VERSION ""

NS_ :

BS_:

BU_: Dummy_FO TestTool_FO LRR_FO RFSRR_FO LFSRR_FO RSRR_FO VIS_FO EOCM_F_FO
VAL_TABLE_ vt_BooleanValues 1 "true" 0 "false" ;
VAL_TABLE_ PAWarningSt 15 "Zone 15" 14 "Zone 14" 13 "Zone 13" 12 "Zone 12" 11 "Zone 11" 10 "Zone 10" 9 "Zone 9" 8 "Zone 8" 7 "Zone 7" 6 "Zone 6" 5 "Zone 5" 4 "Zone 4" 3 "Zone 3" 2 "Zone 2" 1 "Zone 1" 0 "No Object" ;
VAL_TABLE_ BWWarningSt 4 "Vehicle Hold" 3 "Auto Brake" 2 "Imminent Alert" 1 "Caution Alert" 0 "No Alert" ;
VAL_TABLE_ PASysStatus 3 "Failed" 2 "Inhibited" 1 "Enabled" 0 "Disabled" ;
VAL_TABLE_ VBBrkCtrlSt 4 "Release Control" 3 "Hold Vehicle" 2 "Apply Brake" 1 "Decrease Torque" 0 "No Action" ;
VAL_TABLE_ UPABrkCtrlStat 4 "Release Control" 3 "Hold Vehicle" 2 "Apply Brake" 1 "Decrease Torque" 0 "No Action" ;
VAL_TABLE_ ObstacleType 6 "NO_OBJECT" 5 "OBJ_GUARDRAIL" 4 "OBJ_TUNNEL " 3 "OBJ_TRAFFIC_SIGN" 2 "OBJ_VEHICLE" 1 "OBJ_BRIDGE " 0 "OBJ_UNKNOWN" ;
VAL_TABLE_ VpathMode 2 "Mid Hi Spped" 1 "Low Speed" 0 "Disabled" ;
VAL_TABLE_ LaneChngStatus 2 "Lane Change Right" 1 "Lane Change Left" 0 "Idle" ;
VAL_TABLE_ TravelDirection 3 "Other (excessive side slip)" 2 "reverse / stopped in rvrs gear" 1 "Forward / stopped in frwd gear" 0 "Unknown" ;
VAL_TABLE_ TrueOrFalse 1 "true" 0 "false" ;
VAL_TABLE_ ModeCommand 5 "Sensing with Reduced Power" 4 "Undefined" 3 "Radio Silent" 2 "Sensing" 1 "Not Sensing" 0 "Undefined" ;
VAL_TABLE_ LaneSnsLLnPosValid 1 "Invalid" 0 "Valid" ;
VAL_TABLE_ LnSnsRLnPosValid 1 "Invalid" 0 "Valid" ;
VAL_TABLE_ Elevation 3 "Low " 2 "mid (reserved)" 1 "high " 0 "Unknown" ;
VAL_TABLE_ ModeCommandFdbk 5 "Sensing with reduced power" 4 "Undefined" 3 "Radio Silent" 2 "Sensing" 1 "Not Sensing" 0 "Undefined" ;
VAL_TABLE_ relativeLane 3 "Left Lane" 2 "Right Lane" 1 "Host Lane" 0 "Unknown" ;
VAL_TABLE_ RoadTypeInfo 5 "Constiction Zone Exit" 4 "Construction Zone Entry" 3 "Highway" 2 "Secondary Road" 1 "City" 0 "Unknown" ;
VAL_TABLE_ ObjectLossInfo 2 "elevation conditions" 1 "tight curve" 0 "not lost" ;
VAL_TABLE_ MeasurementStatus 3 "Measured this cycle" 2 "Latent track not detctd this cyc" 1 "New Object" 0 "No Object" ;
VAL_TABLE_ ObjectType 7 "no object present" 6 "fixed roadside object" 5 "fixed overhead object" 4 "pedestrian" 3 "motocycle  / bicycle" 2 "Large vehicle (semi)" 1 "4 Wheel Vehicle (car, small trk)" 0 "Unknown" ;
VAL_TABLE_ Confidence 3 "confident" 2 "speculative" 1 "highly speculative" 0 "invalid" ;
VAL_TABLE_ DynamicProp 4 "Moving in opposite direction" 3 "Moving in same direction as host" 2 "Has moved but currently stopped" 1 "Has never moved" 0 "Unknown" ;
VAL_TABLE_ OtsdAmbtLtLvlStat 2 "Day" 1 "Night" 0 "Unknown" ;
VAL_TABLE_ SysPwrMd 3 "Crank Request" 2 "Run" 1 "Accessory" 0 "Off" ;
VAL_TABLE_ ValidityStates 1 "Invalid" 0 "Valid" ;

BO_ 1401 R_Rwd_Fus_Obj_TrackB_9: 7 EOCM_F_FO
 SG_ RwdFusTrkBAnlgRlLn9 : 46|8@0- (0.1,0) [-12.8|12.7] ""  Dummy_FO
 SG_ RwdFusTrkB9RollingCnt : 7|2@0+ (1,0) [0|3] ""  Dummy_FO
 SG_ RwdFusTrkB9Width : 5|6@0+ (0.25,0) [0|15.75] "m"  Dummy_FO
 SG_ RwdFusTrkB9MsgIndex : 15|4@0+ (1,0) [0|15] ""  Dummy_FO
 SG_ RwdFusTrkB9DynProp : 11|3@0+ (1,0) [0|7] ""  Dummy_FO
 SG_ RwdFusTrkB9RelLnAccl : 8|9@0- (0.125,0) [-32|31.875] "m/s^2"  Dummy_FO
 SG_ RwdFusTrkB9RelLane : 31|2@0+ (1,0) [0|3] ""  Dummy_FO
 SG_ RwdFusTrkB9Height : 54|6@0+ (0.25,0) [0|15.75] "m"  Dummy_FO
 SG_ RFusTrkB9ObjSrcLFSrr : 29|1@0+ (1,0) [0|1] ""  Dummy_FO
 SG_ RFusTrkB9ObjSrcLCSrr : 28|1@0+ (1,0) [0|1] ""  Dummy_FO
 SG_ RFusTrkB9ObjSrcRCSrr : 27|1@0+ (1,0) [0|1] ""  Dummy_FO
 SG_ RFusTrkB9ObjSrcRFSrr : 26|1@0+ (1,0) [0|1] ""  Dummy_FO
 SG_ RFusTrkB9ObjSrcVIs : 25|1@0+ (1,0) [0|1] ""  Dummy_FO
 SG_ RwdFusTrkB9ObjSrcLrr : 24|1@0+ (1,0) [0|1] ""  Dummy_FO
 SG_ RwdFusTrkB9NmCycTrkd : 39|3@0+ (1,0) [0|7] ""  Dummy_FO
 SG_ RwdFusTrkB9LatPosDev : 36|3@0+ (1,0) [0|7] ""  Dummy_FO
 SG_ RwdFusTrkB9LngPosDev : 33|3@0+ (1,0) [0|7] ""  Dummy_FO

BO_ 1400 R_Rwd_Fus_Obj_TrackB_8: 7 EOCM_F_FO
 SG_ RwdFusTrkBAnlgRlLn8 : 46|8@0- (0.1,0) [-12.8|12.7] ""  Dummy_FO
 SG_ RwdFusTrkB8RollingCnt : 7|2@0+ (1,0) [0|3] ""  Dummy_FO
 SG_ RwdFusTrkB8Width : 5|6@0+ (0.25,0) [0|15.75] "m"  Dummy_FO
 SG_ RwdFusTrkB8MsgIndex : 15|4@0+ (1,0) [0|15] ""  Dummy_FO
 SG_ RwdFusTrkB8DynProp : 11|3@0+ (1,0) [0|7] ""  Dummy_FO
 SG_ RwdFusTrkB8RelLnAccl : 8|9@0- (0.125,0) [-32|31.875] "m/s^2"  Dummy_FO
 SG_ RwdFusTrkB8RelLane : 31|2@0+ (1,0) [0|3] ""  Dummy_FO
 SG_ RwdFusTrkB8Height : 54|6@0+ (0.25,0) [0|15.75] "m"  Dummy_FO
 SG_ RFusTrkB8ObjSrcLFSrr : 29|1@0+ (1,0) [0|1] ""  Dummy_FO
 SG_ RFusTrkB8ObjSrcLCSrr : 28|1@0+ (1,0) [0|1] ""  Dummy_FO
 SG_ RFusTrkB8ObjSrcRCSrr : 27|1@0+ (1,0) [0|1] ""  Dummy_FO
 SG_ RFusTrkB8ObjSrcRFSrr : 26|1@0+ (1,0) [0|1] ""  Dummy_FO
 SG_ RFusTrkB8ObjSrcVIs : 25|1@0+ (1,0) [0|1] ""  Dummy_FO
 SG_ RwdFusTrkB8ObjSrcLrr : 24|1@0+ (1,0) [0|1] ""  Dummy_FO
 SG_ RwdFusTrkB8NmCycTrkd : 39|3@0+ (1,0) [0|7] ""  Dummy_FO
 SG_ RwdFusTrkB8LatPosDev : 36|3@0+ (1,0) [0|7] ""  Dummy_FO
 SG_ RwdFusTrkB8LngPosDev : 33|3@0+ (1,0) [0|7] ""  Dummy_FO

BO_ 1399 R_Rwd_Fus_Obj_TrackB_7: 7 EOCM_F_FO
 SG_ RwdFusTrkBAnlgRlLn7 : 46|8@0- (0.1,0) [-12.8|12.7] ""  Dummy_FO
 SG_ RwdFusTrkB7RollingCnt : 7|2@0+ (1,0) [0|3] ""  Dummy_FO
 SG_ RwdFusTrkB7Width : 5|6@0+ (0.25,0) [0|15.75] "m"  Dummy_FO
 SG_ RwdFusTrkB7MsgIndex : 15|4@0+ (1,0) [0|15] ""  Dummy_FO
 SG_ RwdFusTrkB7DynProp : 11|3@0+ (1,0) [0|7] ""  Dummy_FO
 SG_ RwdFusTrkB7RelLnAccl : 8|9@0- (0.125,0) [-32|31.875] "m/s^2"  Dummy_FO
 SG_ RwdFusTrkB7RelLane : 31|2@0+ (1,0) [0|3] ""  Dummy_FO
 SG_ RwdFusTrkB7Height : 54|6@0+ (0.25,0) [0|15.75] "m"  Dummy_FO
 SG_ RFusTrkB7ObjSrcLFSrr : 29|1@0+ (1,0) [0|1] ""  Dummy_FO
 SG_ RFusTrkB7ObjSrcLCSrr : 28|1@0+ (1,0) [0|1] ""  Dummy_FO
 SG_ RFusTrkB7ObjSrcRCSrr : 27|1@0+ (1,0) [0|1] ""  Dummy_FO
 SG_ RFusTrkB7ObjSrcRFSrr : 26|1@0+ (1,0) [0|1] ""  Dummy_FO
 SG_ RFusTrkB7ObjSrcVIs : 25|1@0+ (1,0) [0|1] ""  Dummy_FO
 SG_ RwdFusTrkB7ObjSrcLrr : 24|1@0+ (1,0) [0|1] ""  Dummy_FO
 SG_ RwdFusTrkB7NmCycTrkd : 39|3@0+ (1,0) [0|7] ""  Dummy_FO
 SG_ RwdFusTrkB7LatPosDev : 36|3@0+ (1,0) [0|7] ""  Dummy_FO
 SG_ RwdFusTrkB7LngPosDev : 33|3@0+ (1,0) [0|7] ""  Dummy_FO

BO_ 1398 R_Rwd_Fus_Obj_TrackB_6: 7 EOCM_F_FO
 SG_ RwdFusTrkB6LngPosDev : 33|3@0+ (1,0) [0|7] ""  Dummy_FO
 SG_ RwdFusTrkBAnlgRlLn6 : 46|8@0- (0.1,0) [-12.8|12.7] ""  Dummy_FO
 SG_ RwdFusTrkB6RollingCnt : 7|2@0+ (1,0) [0|3] ""  Dummy_FO
 SG_ RwdFusTrkB6Width : 5|6@0+ (0.25,0) [0|15.75] "m"  Dummy_FO
 SG_ RwdFusTrkB6MsgIndex : 15|4@0+ (1,0) [0|15] ""  Dummy_FO
 SG_ RwdFusTrkB6DynProp : 11|3@0+ (1,0) [0|7] ""  Dummy_FO
 SG_ RwdFusTrkB6RelLnAccl : 8|9@0- (0.125,0) [-32|31.875] "m/s^2"  Dummy_FO
 SG_ RwdFusTrkB6RelLane : 31|2@0+ (1,0) [0|3] ""  Dummy_FO
 SG_ RwdFusTrkB6Height : 54|6@0+ (0.25,0) [0|15.75] "m"  Dummy_FO
 SG_ RFusTrkB6ObjSrcLFSrr : 29|1@0+ (1,0) [0|1] ""  Dummy_FO
 SG_ RFusTrkB6ObjSrcLCSrr : 28|1@0+ (1,0) [0|1] ""  Dummy_FO
 SG_ RFusTrkB6ObjSrcRCSrr : 27|1@0+ (1,0) [0|1] ""  Dummy_FO
 SG_ RFusTrkB6ObjSrcRFSrr : 26|1@0+ (1,0) [0|1] ""  Dummy_FO
 SG_ RFusTrkB6ObjSrcVIs : 25|1@0+ (1,0) [0|1] ""  Dummy_FO
 SG_ RwdFusTrkB6ObjSrcLrr : 24|1@0+ (1,0) [0|1] ""  Dummy_FO
 SG_ RwdFusTrkB6NmCycTrkd : 39|3@0+ (1,0) [0|7] ""  Dummy_FO
 SG_ RwdFusTrkB6LatPosDev : 36|3@0+ (1,0) [0|7] ""  Dummy_FO

BO_ 1397 R_Rwd_Fus_Obj_TrackB_5: 7 EOCM_F_FO
 SG_ RwdFusTrkBAnlgRlLn5 : 46|8@0- (0.1,0) [-12.8|12.7] ""  Dummy_FO
 SG_ RwdFusTrkB5RollingCnt : 7|2@0+ (1,0) [0|3] ""  Dummy_FO
 SG_ RwdFusTrkB5Width : 5|6@0+ (0.25,0) [0|15.75] "m"  Dummy_FO
 SG_ RwdFusTrkB5MsgIndex : 15|4@0+ (1,0) [0|15] ""  Dummy_FO
 SG_ RwdFusTrkB5DynProp : 11|3@0+ (1,0) [0|7] ""  Dummy_FO
 SG_ RwdFusTrkB5RelLnAccl : 8|9@0- (0.125,0) [-32|31.875] "m/s^2"  Dummy_FO
 SG_ RwdFusTrkB5RelLane : 31|2@0+ (1,0) [0|3] ""  Dummy_FO
 SG_ RwdFusTrkB5Height : 54|6@0+ (0.25,0) [0|15.75] "m"  Dummy_FO
 SG_ RFusTrkB5ObjSrcLFSrr : 29|1@0+ (1,0) [0|1] ""  Dummy_FO
 SG_ RFusTrkB5ObjSrcLCSrr : 28|1@0+ (1,0) [0|1] ""  Dummy_FO
 SG_ RFusTrkB5ObjSrcRCSrr : 27|1@0+ (1,0) [0|1] ""  Dummy_FO
 SG_ RFusTrkB5ObjSrcRFSrr : 26|1@0+ (1,0) [0|1] ""  Dummy_FO
 SG_ RFusTrkB5ObjSrcVIs : 25|1@0+ (1,0) [0|1] ""  Dummy_FO
 SG_ RwdFusTrkB5ObjSrcLrr : 24|1@0+ (1,0) [0|1] ""  Dummy_FO
 SG_ RwdFusTrkB5NmCycTrkd : 39|3@0+ (1,0) [0|7] ""  Dummy_FO
 SG_ RwdFusTrkB5LatPosDev : 36|3@0+ (1,0) [0|7] ""  Dummy_FO
 SG_ RwdFusTrkB5LngPosDev : 33|3@0+ (1,0) [0|7] ""  Dummy_FO

BO_ 1396 R_Rwd_Fus_Obj_TrackB_4: 7 EOCM_F_FO
 SG_ RwdFusTrkBAnlgRlLn4 : 46|8@0- (0.1,0) [-12.8|12.7] ""  Dummy_FO
 SG_ RwdFusTrkB4RollingCnt : 7|2@0+ (1,0) [0|3] ""  Dummy_FO
 SG_ RwdFusTrkB4Width : 5|6@0+ (0.25,0) [0|15.75] "m"  Dummy_FO
 SG_ RwdFusTrkB4MsgIndex : 15|4@0+ (1,0) [0|15] ""  Dummy_FO
 SG_ RwdFusTrkB4DynProp : 11|3@0+ (1,0) [0|7] ""  Dummy_FO
 SG_ RwdFusTrkB4RelLnAccl : 8|9@0- (0.125,0) [-32|31.875] "m/s^2"  Dummy_FO
 SG_ RwdFusTrkB4RelLane : 31|2@0+ (1,0) [0|3] ""  Dummy_FO
 SG_ RwdFusTrkB4Height : 54|6@0+ (0.25,0) [0|15.75] "m"  Dummy_FO
 SG_ RFusTrkB4ObjSrcLFSrr : 29|1@0+ (1,0) [0|1] ""  Dummy_FO
 SG_ RFusTrkB4ObjSrcLCSrr : 28|1@0+ (1,0) [0|1] ""  Dummy_FO
 SG_ RFusTrkB4ObjSrcRCSrr : 27|1@0+ (1,0) [0|1] ""  Dummy_FO
 SG_ RFusTrkB4ObjSrcRFSrr : 26|1@0+ (1,0) [0|1] ""  Dummy_FO
 SG_ RFusTrkB4ObjSrcVIs : 25|1@0+ (1,0) [0|1] ""  Dummy_FO
 SG_ RwdFusTrkB4ObjSrcLrr : 24|1@0+ (1,0) [0|1] ""  Dummy_FO
 SG_ RwdFusTrkB4NmCycTrkd : 39|3@0+ (1,0) [0|7] ""  Dummy_FO
 SG_ RwdFusTrkB4LatPosDev : 36|3@0+ (1,0) [0|7] ""  Dummy_FO
 SG_ RwdFusTrkB4LngPosDev : 33|3@0+ (1,0) [0|7] ""  Dummy_FO

BO_ 1395 R_Rwd_Fus_Obj_TrackB_3: 7 EOCM_F_FO
 SG_ RwdFusTrkBAnlgRlLn3 : 46|8@0- (0.1,0) [-12.8|12.7] ""  Dummy_FO
 SG_ RwdFusTrkB3RollingCnt : 7|2@0+ (1,0) [0|3] ""  Dummy_FO
 SG_ RwdFusTrkB3Width : 5|6@0+ (0.25,0) [0|15.75] "m"  Dummy_FO
 SG_ RwdFusTrkB3MsgIndex : 15|4@0+ (1,0) [0|15] ""  Dummy_FO
 SG_ RwdFusTrkB3DynProp : 11|3@0+ (1,0) [0|7] ""  Dummy_FO
 SG_ RwdFusTrkB3RelLnAccl : 8|9@0- (0.125,0) [-32|31.875] "m/s^2"  Dummy_FO
 SG_ RwdFusTrkB3RelLane : 31|2@0+ (1,0) [0|3] ""  Dummy_FO
 SG_ RwdFusTrkB3Height : 54|6@0+ (0.25,0) [0|15.75] "m"  Dummy_FO
 SG_ RFusTrkB3ObjSrcLFSrr : 29|1@0+ (1,0) [0|1] ""  Dummy_FO
 SG_ RFusTrkB3ObjSrcLCSrr : 28|1@0+ (1,0) [0|1] ""  Dummy_FO
 SG_ RFusTrkB3ObjSrcRCSrr : 27|1@0+ (1,0) [0|1] ""  Dummy_FO
 SG_ RFusTrkB3ObjSrcRFSrr : 26|1@0+ (1,0) [0|1] ""  Dummy_FO
 SG_ RFusTrkB3ObjSrcVIs : 25|1@0+ (1,0) [0|1] ""  Dummy_FO
 SG_ RwdFusTrkB3ObjSrcLrr : 24|1@0+ (1,0) [0|1] ""  Dummy_FO
 SG_ RwdFusTrkB3NmCycTrkd : 39|3@0+ (1,0) [0|7] ""  Dummy_FO
 SG_ RwdFusTrkB3LatPosDev : 36|3@0+ (1,0) [0|7] ""  Dummy_FO
 SG_ RwdFusTrkB3LngPosDev : 33|3@0+ (1,0) [0|7] ""  Dummy_FO

BO_ 1394 R_Rwd_Fus_Obj_TrackB_2: 7 EOCM_F_FO
 SG_ RwdFusTrkBAnlgRlLn2 : 46|8@0- (0.1,0) [-12.8|12.7] ""  Dummy_FO
 SG_ RwdFusTrkB2RollingCnt : 7|2@0+ (1,0) [0|3] ""  Dummy_FO
 SG_ RwdFusTrkB2Width : 5|6@0+ (0.25,0) [0|15.75] "m"  Dummy_FO
 SG_ RwdFusTrkB2MsgIndex : 15|4@0+ (1,0) [0|15] ""  Dummy_FO
 SG_ RwdFusTrkB2DynProp : 11|3@0+ (1,0) [0|7] ""  Dummy_FO
 SG_ RwdFusTrkB2RelLnAccl : 8|9@0- (0.125,0) [-32|31.875] "m/s^2"  Dummy_FO
 SG_ RwdFusTrkB2RelLane : 31|2@0+ (1,0) [0|3] ""  Dummy_FO
 SG_ RwdFusTrkB2Height : 54|6@0+ (0.25,0) [0|15.75] "m"  Dummy_FO
 SG_ RFusTrkB2ObjSrcLFSrr : 29|1@0+ (1,0) [0|1] ""  Dummy_FO
 SG_ RFusTrkB2ObjSrcLCSrr : 28|1@0+ (1,0) [0|1] ""  Dummy_FO
 SG_ RFusTrkB2ObjSrcRCSrr : 27|1@0+ (1,0) [0|1] ""  Dummy_FO
 SG_ RFusTrkB2ObjSrcRFSrr : 26|1@0+ (1,0) [0|1] ""  Dummy_FO
 SG_ RFusTrkB2ObjSrcVIs : 25|1@0+ (1,0) [0|1] ""  Dummy_FO
 SG_ RwdFusTrkB2ObjSrcLrr : 24|1@0+ (1,0) [0|1] ""  Dummy_FO
 SG_ RwdFusTrkB2NmCycTrkd : 39|3@0+ (1,0) [0|7] ""  Dummy_FO
 SG_ RwdFusTrkB2LatPosDev : 36|3@0+ (1,0) [0|7] ""  Dummy_FO
 SG_ RwdFusTrkB2LngPosDev : 33|3@0+ (1,0) [0|7] ""  Dummy_FO

BO_ 1407 R_Rwd_Fus_Obj_TrackB_15: 7 EOCM_F_FO
 SG_ RwdFusTrkBAnlgRlLn15 : 46|8@0- (0.1,0) [-12.8|12.7] ""  Dummy_FO
 SG_ RwdFusTrkB15RollingCnt : 7|2@0+ (1,0) [0|3] ""  Dummy_FO
 SG_ RwdFusTrkB15Width : 5|6@0+ (0.25,0) [0|15.75] "m"  Dummy_FO
 SG_ RwdFusTrkB15MsgIndex : 15|4@0+ (1,0) [0|15] ""  Dummy_FO
 SG_ RwdFusTrkB15DynProp : 11|3@0+ (1,0) [0|7] ""  Dummy_FO
 SG_ RwdFusTrkB15RelLnAccl : 8|9@0- (0.125,0) [-32|31.875] "m/s^2"  Dummy_FO
 SG_ RwdFusTrkB15RelLane : 31|2@0+ (1,0) [0|3] ""  Dummy_FO
 SG_ RwdFusTrkB15Height : 54|6@0+ (0.25,0) [0|15.75] "m"  Dummy_FO
 SG_ RFusTrkB15ObjSrcLFSrr : 29|1@0+ (1,0) [0|1] ""  Dummy_FO
 SG_ RFusTrkB15ObjSrcLCSrr : 28|1@0+ (1,0) [0|1] ""  Dummy_FO
 SG_ RFusTrkB15ObjSrcRCSrr : 27|1@0+ (1,0) [0|1] ""  Dummy_FO
 SG_ RFusTrkB15ObjSrcRFSrr : 26|1@0+ (1,0) [0|1] ""  Dummy_FO
 SG_ RFusTkB15ObjSrcVIs : 25|1@0+ (1,0) [0|1] ""  Dummy_FO
 SG_ RwdFusTrkB15ObjSrcLrr : 24|1@0+ (1,0) [0|1] ""  Dummy_FO
 SG_ RwdFusTrkB15NmCycTrkd : 39|3@0+ (1,0) [0|7] ""  Dummy_FO
 SG_ RwdFusTrkB15LatPosDev : 36|3@0+ (1,0) [0|7] ""  Dummy_FO
 SG_ RwdFusTrkB15LngPosDev : 33|3@0+ (1,0) [0|7] ""  Dummy_FO

BO_ 1406 R_Rwd_Fus_Obj_TrackB_14: 7 EOCM_F_FO
 SG_ RwdFusTrkBAnlgRlLn14 : 46|8@0- (0.1,0) [-12.8|12.7] ""  Dummy_FO
 SG_ RwdFusTrkB14RollingCnt : 7|2@0+ (1,0) [0|3] ""  Dummy_FO
 SG_ RwdFusTrkB14Width : 5|6@0+ (0.25,0) [0|15.75] "m"  Dummy_FO
 SG_ RwdFusTrkB14MsgIndex : 15|4@0+ (1,0) [0|15] ""  Dummy_FO
 SG_ RwdFusTrkB14DynProp : 11|3@0+ (1,0) [0|7] ""  Dummy_FO
 SG_ RwdFusTrkB14RelLnAccl : 8|9@0- (0.125,0) [-32|31.875] "m/s^2"  Dummy_FO
 SG_ RwdFusTrkB14RelLane : 31|2@0+ (1,0) [0|3] ""  Dummy_FO
 SG_ RwdFusTrkB14Height : 54|6@0+ (0.25,0) [0|15.75] "m"  Dummy_FO
 SG_ RFusTrkB14ObjSrcLFSrr : 29|1@0+ (1,0) [0|1] ""  Dummy_FO
 SG_ RFusTrkB14ObjSrcLCSrr : 28|1@0+ (1,0) [0|1] ""  Dummy_FO
 SG_ RFusTrkB14ObjSrcRCSrr : 27|1@0+ (1,0) [0|1] ""  Dummy_FO
 SG_ RFusTrkB14ObjSrcRFSrr : 26|1@0+ (1,0) [0|1] ""  Dummy_FO
 SG_ RFusTrkB14ObjSrcVIs : 25|1@0+ (1,0) [0|1] ""  Dummy_FO
 SG_ RwdFusTrkB14ObjSrcLrr : 24|1@0+ (1,0) [0|1] ""  Dummy_FO
 SG_ RwdFusTrkB14NmCycTrkd : 39|3@0+ (1,0) [0|7] ""  Dummy_FO
 SG_ RwdFusTrkB14LatPosDev : 36|3@0+ (1,0) [0|7] ""  Dummy_FO
 SG_ RwdFusTrkB14LngPosDev : 33|3@0+ (1,0) [0|7] ""  Dummy_FO

BO_ 1405 R_Rwd_Fus_Obj_TrackB_13: 7 EOCM_F_FO
 SG_ RwdFusTrkBAnlgRlLn13 : 46|8@0- (0.1,0) [-12.8|12.7] ""  Dummy_FO
 SG_ RwdFusTrkB13RollingCnt : 7|2@0+ (1,0) [0|3] ""  Dummy_FO
 SG_ RwdFusTrkB13Width : 5|6@0+ (0.25,0) [0|15.75] "m"  Dummy_FO
 SG_ RwdFusTrkB13MsgIndex : 15|4@0+ (1,0) [0|15] ""  Dummy_FO
 SG_ RwdFusTrkB13DynProp : 11|3@0+ (1,0) [0|7] ""  Dummy_FO
 SG_ RwdFusTrkB13RelLnAccl : 8|9@0- (0.125,0) [-32|31.875] "m/s^2"  Dummy_FO
 SG_ RwdFusTrkB13RelLane : 31|2@0+ (1,0) [0|3] ""  Dummy_FO
 SG_ RwdFusTrkB13Height : 54|6@0+ (0.25,0) [0|15.75] "m"  Dummy_FO
 SG_ RFusTrkB13ObjSrcLFSrr : 29|1@0+ (1,0) [0|1] ""  Dummy_FO
 SG_ RFusTrkB13ObjSrcLCSrr : 28|1@0+ (1,0) [0|1] ""  Dummy_FO
 SG_ RFusTrkB13ObjSrcRCSrr : 27|1@0+ (1,0) [0|1] ""  Dummy_FO
 SG_ RFusTrkB13ObjSrcRFSrr : 26|1@0+ (1,0) [0|1] ""  Dummy_FO
 SG_ RFusTrkB13ObjSrcVIs : 25|1@0+ (1,0) [0|1] ""  Dummy_FO
 SG_ RwdFusTrkB13ObjSrcLrr : 24|1@0+ (1,0) [0|1] ""  Dummy_FO
 SG_ RwdFusTrkB13NmCycTrkd : 39|3@0+ (1,0) [0|7] ""  Dummy_FO
 SG_ RwdFusTrkB13LatPosDev : 36|3@0+ (1,0) [0|7] ""  Dummy_FO
 SG_ RwdFusTrkB13LngPosDev : 33|3@0+ (1,0) [0|7] ""  Dummy_FO

BO_ 1404 R_Rwd_Fus_Obj_TrackB_12: 7 EOCM_F_FO
 SG_ RwdFusTrkBAnlgRlLn12 : 46|8@0- (0.1,0) [-12.8|12.7] ""  Dummy_FO
 SG_ RwdFusTrkB12RollingCnt : 7|2@0+ (1,0) [0|3] ""  Dummy_FO
 SG_ RwdFusTrkB12Width : 5|6@0+ (0.25,0) [0|15.75] "m"  Dummy_FO
 SG_ RwdFusTrkB12MsgIndex : 15|4@0+ (1,0) [0|15] ""  Dummy_FO
 SG_ RwdFusTrkB12DynProp : 11|3@0+ (1,0) [0|7] ""  Dummy_FO
 SG_ RwdFusTrkB12RelLnAccl : 8|9@0- (0.125,0) [-32|31.875] "m/s^2"  Dummy_FO
 SG_ RwdFusTrkB12RelLane : 31|2@0+ (1,0) [0|3] ""  Dummy_FO
 SG_ RwdFusTrkB12Height : 54|6@0+ (0.25,0) [0|15.75] "m"  Dummy_FO
 SG_ RFusTrkB12ObjSrcLFSrr : 29|1@0+ (1,0) [0|1] ""  Dummy_FO
 SG_ RFusTrkB12ObjSrcLCSrr : 28|1@0+ (1,0) [0|1] ""  Dummy_FO
 SG_ RFusTrkB12ObjSrcRCSrr : 27|1@0+ (1,0) [0|1] ""  Dummy_FO
 SG_ RFusTrkB12ObjSrcRFSrr : 26|1@0+ (1,0) [0|1] ""  Dummy_FO
 SG_ RFusTrkB12ObjSrcVIs : 25|1@0+ (1,0) [0|1] ""  Dummy_FO
 SG_ RwdFusTrkB12ObjSrcLrr : 24|1@0+ (1,0) [0|1] ""  Dummy_FO
 SG_ RwdFusTrkB12NmCycTrkd : 39|3@0+ (1,0) [0|7] ""  Dummy_FO
 SG_ RwdFusTrkB12LatPosDev : 36|3@0+ (1,0) [0|7] ""  Dummy_FO
 SG_ RwdFusTrkB12LngPosDev : 33|3@0+ (1,0) [0|7] ""  Dummy_FO

BO_ 1403 R_Rwd_Fus_Obj_TrackB_11: 7 EOCM_F_FO
 SG_ RwdFusTrkBAnlgRlLn11 : 46|8@0- (0.1,0) [-12.8|12.7] ""  Dummy_FO
 SG_ RwdFusTrkB11RollingCnt : 7|2@0+ (1,0) [0|3] ""  Dummy_FO
 SG_ RwdFusTrkB11Width : 5|6@0+ (0.25,0) [0|15.75] "m"  Dummy_FO
 SG_ RwdFusTrkB11MsgIndex : 15|4@0+ (1,0) [0|15] ""  Dummy_FO
 SG_ RwdFusTrkB11DynProp : 11|3@0+ (1,0) [0|7] ""  Dummy_FO
 SG_ RwdFusTrkB11RelLnAccl : 8|9@0- (0.125,0) [-32|31.875] "m/s^2"  Dummy_FO
 SG_ RwdFusTrkB11RelLane : 31|2@0+ (1,0) [0|3] ""  Dummy_FO
 SG_ RwdFusTrkB11Height : 54|6@0+ (0.25,0) [0|15.75] "m"  Dummy_FO
 SG_ RFusTrkB11ObjSrcLFSrr : 29|1@0+ (1,0) [0|1] ""  Dummy_FO
 SG_ RFusTrkB11ObjSrcLCSrr : 28|1@0+ (1,0) [0|1] ""  Dummy_FO
 SG_ RFusTrkB11ObjSrcRCSrr : 27|1@0+ (1,0) [0|1] ""  Dummy_FO
 SG_ RFusTrkB11ObjSrcRFSrr : 26|1@0+ (1,0) [0|1] ""  Dummy_FO
 SG_ RFusTrkB11ObjSrcVIs : 25|1@0+ (1,0) [0|1] ""  Dummy_FO
 SG_ RwdFusTrkB11ObjSrcLrr : 24|1@0+ (1,0) [0|1] ""  Dummy_FO
 SG_ RwdFusTrkB11NmCycTrkd : 39|3@0+ (1,0) [0|7] ""  Dummy_FO
 SG_ RwdFusTrkB11LatPosDev : 36|3@0+ (1,0) [0|7] ""  Dummy_FO
 SG_ RwdFusTrkB11LngPosDev : 33|3@0+ (1,0) [0|7] ""  Dummy_FO

BO_ 1402 R_Rwd_Fus_Obj_TrackB_10: 7 EOCM_F_FO
 SG_ RwdFusTrkB10NmCycTrkd : 39|3@0+ (1,0) [0|7] ""  Dummy_FO
 SG_ RwdFusTrkB10LatPosDev : 36|3@0+ (1,0) [0|7] ""  Dummy_FO
 SG_ RwdFusTrkB10LngPosDev : 33|3@0+ (1,0) [0|7] ""  Dummy_FO
 SG_ RwdFusTrkBAnlgRlLn10 : 46|8@0- (0.1,0) [-12.8|12.7] ""  Dummy_FO
 SG_ RwdFusTrkB10RollingCnt : 7|2@0+ (1,0) [0|3] ""  Dummy_FO
 SG_ RwdFusTrkB10Width : 5|6@0+ (0.25,0) [0|15.75] "m"  Dummy_FO
 SG_ RwdFusTrkB10MsgIndex : 15|4@0+ (1,0) [0|15] ""  Dummy_FO
 SG_ RwdFusTrkB10DynProp : 11|3@0+ (1,0) [0|7] ""  Dummy_FO
 SG_ RwdFusTrkB10RelLnAccl : 8|9@0- (0.125,0) [-32|31.875] "m/s^2"  Dummy_FO
 SG_ RwdFusTrkB10RelLane : 31|2@0+ (1,0) [0|3] ""  Dummy_FO
 SG_ RwdFusTrkB10Height : 54|6@0+ (0.25,0) [0|15.75] "m"  Dummy_FO
 SG_ RFusTrkB10ObjSrcLFSrr : 29|1@0+ (1,0) [0|1] ""  Dummy_FO
 SG_ RFusTrkB10ObjSrcLCSrr : 28|1@0+ (1,0) [0|1] ""  Dummy_FO
 SG_ RFusTrkB10ObjSrcRCSrr : 27|1@0+ (1,0) [0|1] ""  Dummy_FO
 SG_ RFusTrkB10ObjSrcRFSrr : 26|1@0+ (1,0) [0|1] ""  Dummy_FO
 SG_ RFusTrkB10ObjSrcVIs : 25|1@0+ (1,0) [0|1] ""  Dummy_FO
 SG_ RwdFusTrkB10ObjSrcLrr : 24|1@0+ (1,0) [0|1] ""  Dummy_FO

BO_ 1393 R_Rwd_Fus_Obj_TrackB_1: 7 EOCM_F_FO
 SG_ RwdFusTrkBAnlgRlLn1 : 46|8@0- (0.1,0) [-12.8|12.7] ""  Dummy_FO
 SG_ RwdFusTrkB1RollingCnt : 7|2@0+ (1,0) [0|3] ""  Dummy_FO
 SG_ RwdFusTrkB1Width : 5|6@0+ (0.25,0) [0|15.75] "m"  Dummy_FO
 SG_ RwdFusTrkB1MsgIndex : 15|4@0+ (1,0) [0|15] ""  Dummy_FO
 SG_ RwdFusTrkB1DynProp : 11|3@0+ (1,0) [0|7] ""  Dummy_FO
 SG_ RwdFusTrkB1RelLnAccl : 8|9@0- (0.125,0) [-32|31.875] "m/s^2"  Dummy_FO
 SG_ RwdFusTrkB1RelLane : 31|2@0+ (1,0) [0|3] ""  Dummy_FO
 SG_ RwdFusTrkB1Height : 54|6@0+ (0.25,0) [0|15.75] "m"  Dummy_FO
 SG_ RFusTrkB1ObjSrcLFSrr : 29|1@0+ (1,0) [0|1] ""  Dummy_FO
 SG_ RFusTrkB1ObjSrcLCSrr : 28|1@0+ (1,0) [0|1] ""  Dummy_FO
 SG_ RFusTrkB1ObjSrcRCSrr : 27|1@0+ (1,0) [0|1] ""  Dummy_FO
 SG_ RFusTrkB1ObjSrcRFSrr : 26|1@0+ (1,0) [0|1] ""  Dummy_FO
 SG_ RFusTrkB1ObjSrcVIs : 25|1@0+ (1,0) [0|1] ""  Dummy_FO
 SG_ RwdFusTrkB1ObjSrcLrr : 24|1@0+ (1,0) [0|1] ""  Dummy_FO
 SG_ RwdFusTrkB1NmCycTrkd : 39|3@0+ (1,0) [0|7] ""  Dummy_FO
 SG_ RwdFusTrkB1LatPosDev : 36|3@0+ (1,0) [0|7] ""  Dummy_FO
 SG_ RwdFusTrkB1LngPosDev : 33|3@0+ (1,0) [0|7] ""  Dummy_FO

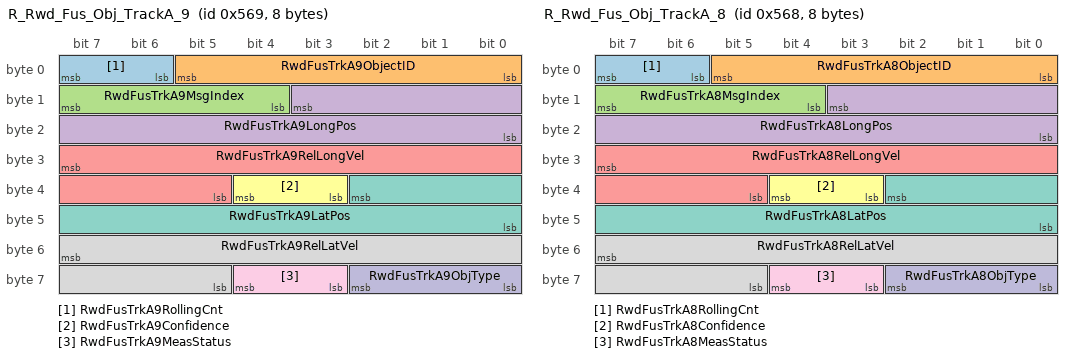
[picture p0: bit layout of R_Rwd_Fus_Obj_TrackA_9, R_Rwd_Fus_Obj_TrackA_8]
BO_ 1385 R_Rwd_Fus_Obj_TrackA_9: 8 EOCM_F_FO
 SG_ RwdFusTrkA9RollingCnt : 7|2@0+ (1,0) [0|3] ""  Dummy_FO
 SG_ RwdFusTrkA9ObjectID : 5|6@0+ (1,0) [0|63] ""  Dummy_FO
 SG_ RwdFusTrkA9MsgIndex : 15|4@0+ (1,0) [0|15] ""  Dummy_FO
 SG_ RwdFusTrkA9LongPos : 11|12@0- (0.125,0) [-256|255.875] "m"  Dummy_FO
 SG_ RwdFusTrkA9RelLongVel : 31|11@0- (0.125,0) [-128|127.875] "m/s"  Dummy_FO
 SG_ RwdFusTrkA9Confidence : 36|2@0+ (1,0) [0|3] ""  Dummy_FO
 SG_ RwdFusTrkA9LatPos : 34|11@0- (0.125,0) [-128|127.875] "m"  Dummy_FO
 SG_ RwdFusTrkA9RelLatVel : 55|11@0- (0.125,0) [-128|127.875] "m/s"  Dummy_FO
 SG_ RwdFusTrkA9MeasStatus : 60|2@0+ (1,0) [0|3] ""  Dummy_FO
 SG_ RwdFusTrkA9ObjType : 58|3@0+ (1,0) [0|7] ""  Dummy_FO

BO_ 1384 R_Rwd_Fus_Obj_TrackA_8: 8 EOCM_F_FO
 SG_ RwdFusTrkA8RollingCnt : 7|2@0+ (1,0) [0|3] ""  Dummy_FO
 SG_ RwdFusTrkA8ObjectID : 5|6@0+ (1,0) [0|63] ""  Dummy_FO
 SG_ RwdFusTrkA8MsgIndex : 15|4@0+ (1,0) [0|15] ""  Dummy_FO
 SG_ RwdFusTrkA8LongPos : 11|12@0- (0.125,0) [-256|255.875] "m"  Dummy_FO
 SG_ RwdFusTrkA8RelLongVel : 31|11@0- (0.125,0) [-128|127.875] "m/s"  Dummy_FO
 SG_ RwdFusTrkA8Confidence : 36|2@0+ (1,0) [0|3] ""  Dummy_FO
 SG_ RwdFusTrkA8LatPos : 34|11@0- (0.125,0) [-128|127.875] "m"  Dummy_FO
 SG_ RwdFusTrkA8RelLatVel : 55|11@0- (0.125,0) [-128|127.875] "m/s"  Dummy_FO
 SG_ RwdFusTrkA8MeasStatus : 60|2@0+ (1,0) [0|3] ""  Dummy_FO
 SG_ RwdFusTrkA8ObjType : 58|3@0+ (1,0) [0|7] ""  Dummy_FO

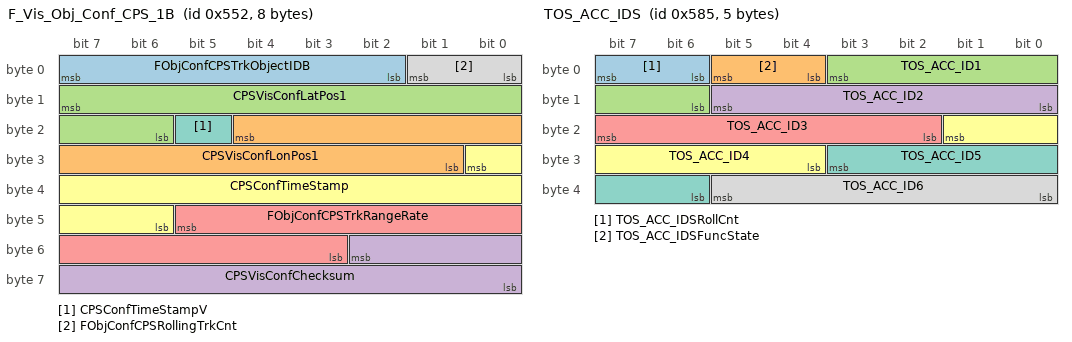
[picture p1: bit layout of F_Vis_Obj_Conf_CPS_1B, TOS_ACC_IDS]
BO_ 1362 F_Vis_Obj_Conf_CPS_1B: 8 EOCM_F_FO
 SG_ FObjConfCPSTrkObjectIDB : 7|6@0+ (1,0) [0|63] ""  VIS_FO
 SG_ CPSVisConfLonPos1 : 20|12@0- (0.125,0) [-256|255.875] "m"  VIS_FO
 SG_ CPSVisConfLatPos1 : 15|10@0- (0.125,0) [-64|63.875] "m"  VIS_FO
 SG_ CPSVisConfChecksum : 50|11@0+ (1,0) [0|2047] ""  VIS_FO
 SG_ FObjConfCPSTrkRangeRate : 45|11@0- (0.125,0) [-128|127.875] "m/s"  VIS_FO
 SG_ CPSConfTimeStamp : 24|11@0+ (1,0) [0|2047] "ms"  VIS_FO
 SG_ CPSConfTimeStampV : 21|1@0+ (1,0) [0|1] ""  VIS_FO
 SG_ FObjConfCPSRollingTrkCnt : 1|2@0+ (1,0) [0|3] ""  VIS_FO

BO_ 1413 TOS_ACC_IDS: 5 EOCM_F_FO
 SG_ TOS_ACC_IDSRollCnt : 7|2@0+ (1,0) [0|3] ""  Dummy_FO
 SG_ TOS_ACC_IDSFuncState : 5|2@0+ (1,0) [0|3] ""  Dummy_FO
 SG_ TOS_ACC_ID1 : 3|6@0+ (1,0) [0|63] ""  Dummy_FO
 SG_ TOS_ACC_ID2 : 13|6@0+ (1,0) [0|63] ""  Dummy_FO
 SG_ TOS_ACC_ID3 : 23|6@0+ (1,0) [0|63] ""  Dummy_FO
 SG_ TOS_ACC_ID4 : 17|6@0+ (1,0) [0|63] ""  Dummy_FO
 SG_ TOS_ACC_ID5 : 27|6@0+ (1,0) [0|63] ""  Dummy_FO
 SG_ TOS_ACC_ID6 : 37|6@0+ (1,0) [0|63] ""  Dummy_FO

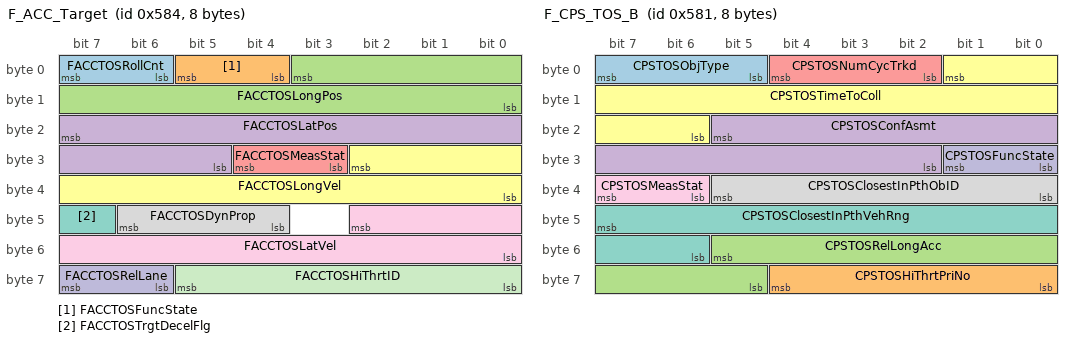
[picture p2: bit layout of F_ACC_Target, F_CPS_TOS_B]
BO_ 1412 F_ACC_Target: 8 EOCM_F_FO
 SG_ FACCTOSRollCnt : 7|2@0+ (1,0) [0|3] ""  Dummy_FO
 SG_ FACCTOSFuncState : 5|2@0+ (1,0) [0|3] ""  Dummy_FO
 SG_ FACCTOSLongPos : 3|12@0- (0.125,0) [-256|255.875] "m"  Dummy_FO
 SG_ FACCTOSLatPos : 23|11@0- (0.125,0) [-128|127.875] "m"  Dummy_FO
 SG_ FACCTOSMeasStat : 28|2@0+ (1,0) [0|3] ""  Dummy_FO
 SG_ FACCTOSLongVel : 26|11@0- (0.125,0) [-128|127.875] "m/s"  Dummy_FO
 SG_ FACCTOSTrgtDecelFlg : 47|1@0+ (1,0) [0|1] ""  Dummy_FO
 SG_ FACCTOSDynProp : 46|3@0+ (1,0) [0|7] ""  Dummy_FO
 SG_ FACCTOSLatVel : 42|11@0- (0.125,0) [-128|127.875] "m/s"  Dummy_FO
 SG_ FACCTOSRelLane : 63|2@0+ (1,0) [0|3] ""  Dummy_FO
 SG_ FACCTOSHiThrtID : 61|6@0+ (1,0) [0|63] ""  Dummy_FO

BO_ 1409 F_CPS_TOS_B: 8 EOCM_F_FO
 SG_ CPSTOSObjType : 7|3@0+ (1,0) [0|7] ""  Dummy_FO
 SG_ CPSTOSHiThrtPriNo : 60|5@0+ (1,0) [0|31] ""  Dummy_FO
 SG_ CPSTOSRelLongAcc : 53|9@0- (0.125,0) [-32|31.875] "m/s^2"  Dummy_FO
 SG_ CPSTOSConfAsmt : 21|12@0+ (1,0) [0|4095] ""  Dummy_FO
 SG_ CPSTOSNumCycTrkd : 4|3@0+ (1,0) [0|7] ""  Dummy_FO
 SG_ CPSTOSTimeToColl : 1|12@0+ (0.025,0) [0|102.375] "s"  Dummy_FO
 SG_ CPSTOSClosestInPthVehRng : 47|10@0+ (0.25,0) [0|255.75] "m"  Dummy_FO
 SG_ CPSTOSClosestInPthObID : 37|6@0+ (1,0) [0|63] "m"  Dummy_FO
 SG_ CPSTOSMeasStat : 39|2@0+ (1,0) [0|3] ""  Dummy_FO
 SG_ CPSTOSFuncState : 25|2@0+ (1,0) [0|3] ""  Dummy_FO

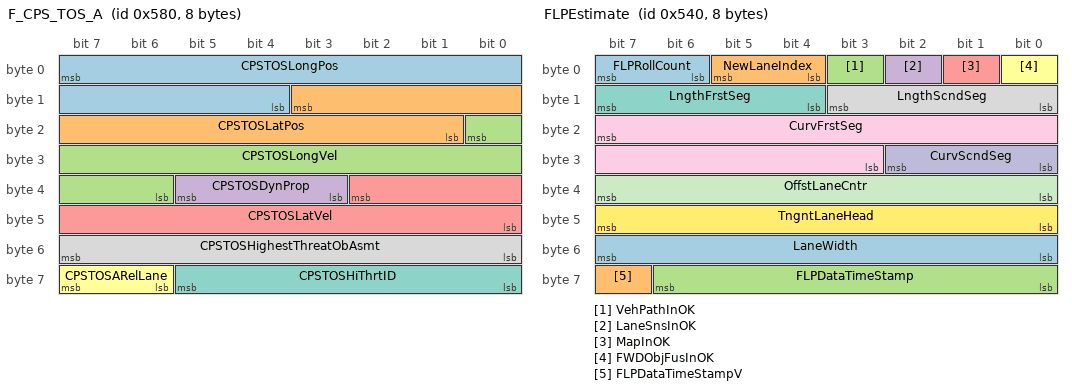
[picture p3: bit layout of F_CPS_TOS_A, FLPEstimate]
BO_ 1408 F_CPS_TOS_A: 8 EOCM_F_FO
 SG_ CPSTOSLongPos : 7|12@0- (0.125,0) [-256|255.875] "m"  Dummy_FO
 SG_ CPSTOSLatPos : 11|11@0- (0.125,0) [-128|127.875] "m"  Dummy_FO
 SG_ CPSTOSLongVel : 16|11@0- (0.125,0) [-128|127.875] "m/s"  Dummy_FO
 SG_ CPSTOSDynProp : 37|3@0+ (1,0) [0|7] ""  Dummy_FO
 SG_ CPSTOSLatVel : 34|11@0- (0.125,0) [-128|127.875] "m/s"  Dummy_FO
 SG_ CPSTOSARelLane : 63|2@0+ (1,0) [0|3] ""  Dummy_FO
 SG_ CPSTOSHiThrtID : 61|6@0+ (1,0) [0|63] ""  Dummy_FO
 SG_ CPSTOSHighestThreatObAsmt : 55|8@0+ (1,0) [0|255] ""  Dummy_FO

BO_ 1344 FLPEstimate: 8 EOCM_F_FO
 SG_ FLPRollCount : 7|2@0+ (1,0) [0|3] ""  Dummy_FO
 SG_ NewLaneIndex : 5|2@0+ (1,0) [0|3] ""  Dummy_FO
 SG_ VehPathInOK : 3|1@0+ (1,0) [0|1] ""  Dummy_FO
 SG_ LaneSnsInOK : 2|1@0+ (1,0) [0|1] ""  Dummy_FO
 SG_ MapInOK : 1|1@0+ (1,0) [0|1] ""  Dummy_FO
 SG_ FWDObjFusInOK : 0|1@0+ (1,0) [0|1] ""  Dummy_FO
 SG_ LngthFrstSeg : 15|4@0+ (10,0) [0|150] "m"  Dummy_FO
 SG_ LngthScndSeg : 11|4@0+ (10,0) [0|150] "m"  Dummy_FO
 SG_ CurvFrstSeg : 23|13@0- (5E-005,0) [-0.2048|0.20475] "1/m"  Dummy_FO
 SG_ CurvScndSeg : 26|3@0- (0.001,0) [-0.004|0.003] "1/m"  Dummy_FO
 SG_ OffstLaneCntr : 39|8@0- (0.05,0) [-6.4|6.35] "m"  Dummy_FO
 SG_ TngntLaneHead : 47|8@0- (0.002,0) [-0.256|0.254] "m/m"  Dummy_FO
 SG_ LaneWidth : 55|8@0+ (0.05,0) [0|12.75] "m"  Dummy_FO
 SG_ FLPDataTimeStampV : 63|1@0+ (1,0) [0|1] ""  Dummy_FO
 SG_ FLPDataTimeStamp : 62|7@0+ (16,0) [0|2032] "ms"  Dummy_FO

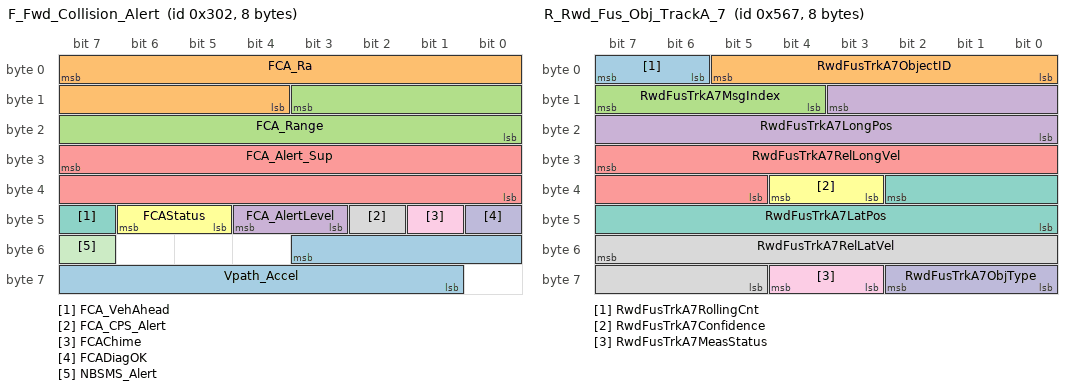
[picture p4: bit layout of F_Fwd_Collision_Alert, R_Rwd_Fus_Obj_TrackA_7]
BO_ 770 F_Fwd_Collision_Alert: 8 EOCM_F_FO
 SG_ Vpath_Accel : 51|11@0- (0.125,0) [-128|127.875] "m/s^2"  Dummy_FO
 SG_ FCA_Ra : 7|12@0- (0.125,0) [-256|255.875] "m"  Dummy_FO
 SG_ FCA_Range : 11|12@0- (0.125,0) [-256|255.875] "m"  Dummy_FO
 SG_ FCA_AlertLevel : 44|2@0+ (1,0) [0|3] ""  Dummy_FO
 SG_ FCA_Alert_Sup : 31|16@0+ (1,0) [0|65535] ""  Dummy_FO
 SG_ FCAStatus : 46|2@0+ (1,0) [0|3] ""  Dummy_FO
 SG_ FCA_VehAhead : 47|1@0+ (1,0) [0|1] ""  Dummy_FO
 SG_ FCA_CPS_Alert : 42|1@0+ (1,0) [0|1] ""  Dummy_FO
 SG_ FCAChime : 41|1@0+ (1,0) [0|1] ""  Dummy_FO
 SG_ FCADiagOK : 40|1@0+ (1,0) [0|1] ""  Dummy_FO
 SG_ NBSMS_Alert : 55|1@0+ (1,0) [0|1] ""  Dummy_FO

BO_ 1601 USDT_Resp_From_VIS: 8 VIS_FO
 SG_ DgnInf_OBJ641 : 7|64@0+ (1,0) [0|1.844674407371E+019] ""  TestTool_FO

BO_ 1606 USDT_Resp_From_RFSRR: 8 RFSRR_FO
 SG_ DgnInf_OBJ646 : 7|64@0+ (1,0) [0|1.844674407371E+019] ""  TestTool_FO

BO_ 1603 USDT_Resp_From_LFSRR: 8 LFSRR_FO
 SG_ DgnInf_OBJ643 : 7|64@0+ (1,0) [0|1.844674407371E+019] ""  TestTool_FO

BO_ 1602 USDT_Resp_From_LRR: 8 LRR_FO
 SG_ DgnInf_OBJ642 : 7|64@0+ (1,0) [0|1.844674407371E+019] ""  TestTool_FO

BO_ 1625 USDT_Resp_From_RSRR: 8 RSRR_FO
 SG_ DgnInf_OBJ644 : 7|64@0+ (1,0) [0|1.844674407371E+019] ""  TestTool_FO

BO_ 1611 USDT_Resp_From_FEOCM_FO: 8 EOCM_F_FO
 SG_ DgnInf_OBJ64B : 7|64@0+ (1,0) [0|1.844674407371E+019] ""  TestTool_FO

BO_ 1383 R_Rwd_Fus_Obj_TrackA_7: 8 EOCM_F_FO
 SG_ RwdFusTrkA7RollingCnt : 7|2@0+ (1,0) [0|3] ""  Dummy_FO
 SG_ RwdFusTrkA7ObjectID : 5|6@0+ (1,0) [0|63] ""  Dummy_FO
 SG_ RwdFusTrkA7MsgIndex : 15|4@0+ (1,0) [0|15] ""  Dummy_FO
 SG_ RwdFusTrkA7LongPos : 11|12@0- (0.125,0) [-256|255.875] "m"  Dummy_FO
 SG_ RwdFusTrkA7RelLongVel : 31|11@0- (0.125,0) [-128|127.875] "m/s"  Dummy_FO
 SG_ RwdFusTrkA7Confidence : 36|2@0+ (1,0) [0|3] ""  Dummy_FO
 SG_ RwdFusTrkA7LatPos : 34|11@0- (0.125,0) [-128|127.875] "m"  Dummy_FO
 SG_ RwdFusTrkA7RelLatVel : 55|11@0- (0.125,0) [-128|127.875] "m/s"  Dummy_FO
 SG_ RwdFusTrkA7MeasStatus : 60|2@0+ (1,0) [0|3] ""  Dummy_FO
 SG_ RwdFusTrkA7ObjType : 58|3@0+ (1,0) [0|7] ""  Dummy_FO

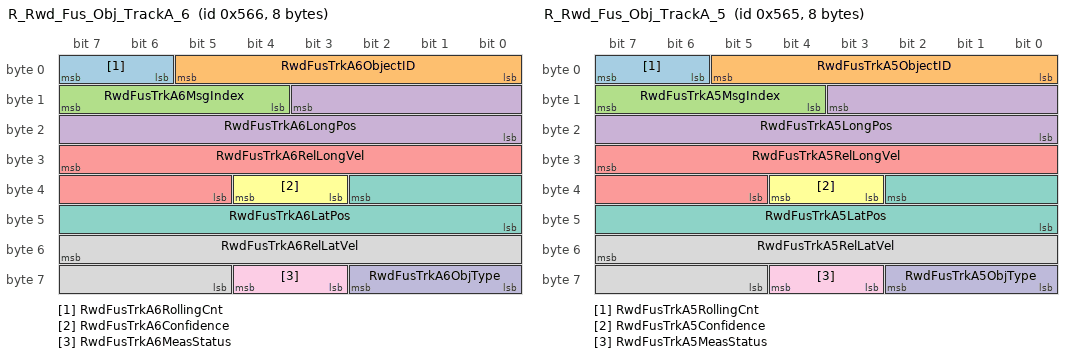
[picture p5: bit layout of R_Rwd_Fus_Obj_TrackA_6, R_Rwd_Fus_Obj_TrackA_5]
BO_ 1382 R_Rwd_Fus_Obj_TrackA_6: 8 EOCM_F_FO
 SG_ RwdFusTrkA6RollingCnt : 7|2@0+ (1,0) [0|3] ""  Dummy_FO
 SG_ RwdFusTrkA6ObjectID : 5|6@0+ (1,0) [0|63] ""  Dummy_FO
 SG_ RwdFusTrkA6MsgIndex : 15|4@0+ (1,0) [0|15] ""  Dummy_FO
 SG_ RwdFusTrkA6LongPos : 11|12@0- (0.125,0) [-256|255.875] "m"  Dummy_FO
 SG_ RwdFusTrkA6RelLongVel : 31|11@0- (0.125,0) [-128|127.875] "m/s"  Dummy_FO
 SG_ RwdFusTrkA6Confidence : 36|2@0+ (1,0) [0|3] ""  Dummy_FO
 SG_ RwdFusTrkA6LatPos : 34|11@0- (0.125,0) [-128|127.875] "m"  Dummy_FO
 SG_ RwdFusTrkA6RelLatVel : 55|11@0- (0.125,0) [-128|127.875] "m/s"  Dummy_FO
 SG_ RwdFusTrkA6MeasStatus : 60|2@0+ (1,0) [0|3] ""  Dummy_FO
 SG_ RwdFusTrkA6ObjType : 58|3@0+ (1,0) [0|7] ""  Dummy_FO

BO_ 1381 R_Rwd_Fus_Obj_TrackA_5: 8 EOCM_F_FO
 SG_ RwdFusTrkA5RollingCnt : 7|2@0+ (1,0) [0|3] ""  Dummy_FO
 SG_ RwdFusTrkA5ObjectID : 5|6@0+ (1,0) [0|63] ""  Dummy_FO
 SG_ RwdFusTrkA5MsgIndex : 15|4@0+ (1,0) [0|15] ""  Dummy_FO
 SG_ RwdFusTrkA5LongPos : 11|12@0- (0.125,0) [-256|255.875] "m"  Dummy_FO
 SG_ RwdFusTrkA5RelLongVel : 31|11@0- (0.125,0) [-128|127.875] "m/s"  Dummy_FO
 SG_ RwdFusTrkA5Confidence : 36|2@0+ (1,0) [0|3] ""  Dummy_FO
 SG_ RwdFusTrkA5LatPos : 34|11@0- (0.125,0) [-128|127.875] "m"  Dummy_FO
 SG_ RwdFusTrkA5RelLatVel : 55|11@0- (0.125,0) [-128|127.875] "m/s"  Dummy_FO
 SG_ RwdFusTrkA5MeasStatus : 60|2@0+ (1,0) [0|3] ""  Dummy_FO
 SG_ RwdFusTrkA5ObjType : 58|3@0+ (1,0) [0|7] ""  Dummy_FO

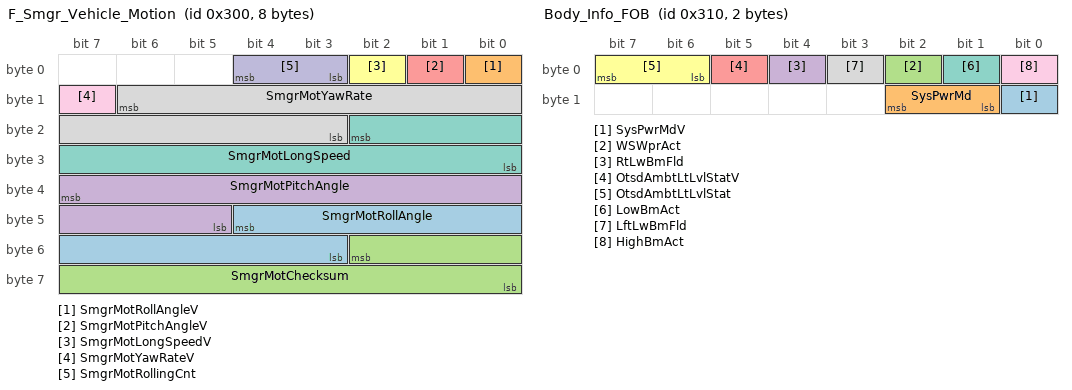
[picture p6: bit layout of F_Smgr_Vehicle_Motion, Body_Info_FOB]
BO_ 768 F_Smgr_Vehicle_Motion: 8 EOCM_F_FO
 SG_ SmgrMotRollAngle : 44|10@0- (0.1,0) [-51.2|51.1] "deg"  VIS_FO
 SG_ SmgrMotRollAngleV : 0|1@0+ (1,0) [0|1] ""  VIS_FO
 SG_ SmgrMotChecksum : 50|11@0+ (1,0) [0|2047] ""  VIS_FO
 SG_ SmgrMotPitchAngle : 39|11@0- (0.1,0) [-102.4|102.3] "deg"  VIS_FO
 SG_ SmgrMotPitchAngleV : 1|1@0+ (1,0) [0|1] ""  VIS_FO
 SG_ SmgrMotLongSpeedV : 2|1@0+ (1,0) [0|1] " "  VIS_FO
 SG_ SmgrMotLongSpeed : 18|11@0- (0.1,0) [-102.4|102.3] "m/s"  VIS_FO
 SG_ SmgrMotYawRate : 14|12@0- (0.05,0) [-102.4|102.35] "deg/s"  VIS_FO
 SG_ SmgrMotYawRateV : 15|1@0+ (1,0) [0|1] ""  VIS_FO
 SG_ SmgrMotRollingCnt : 4|2@0+ (1,0) [0|3] ""  VIS_FO

BO_ 1350 UUDT_Resp_From_RFSRR: 8 RFSRR_FO
 SG_ DgnInf_OBJ546 : 7|64@0+ (1,0) [0|1.844674407371E+019] ""  TestTool_FO

BO_ 1369 UUDT_Resp_From_RSRR: 8 RSRR_FO
 SG_ DgnInf_OBJ544 : 7|64@0+ (1,0) [0|1.844674407371E+019] ""  TestTool_FO

BO_ 1347 UUDT_Resp_From_LFSRR: 8 LFSRR_FO
 SG_ DgnInf_OBJ543 : 7|64@0+ (1,0) [0|1.844674407371E+019] ""  TestTool_FO

BO_ 1346 UUDT_Resp_From_LRR: 8 LRR_FO
 SG_ DgnInf_OBJ542 : 7|64@0+ (1,0) [0|1.844674407371E+019] ""  TestTool_FO

BO_ 1345 UUDT_Resp_From_VIS: 8 VIS_FO
 SG_ DgnInf_OBJ541 : 7|64@0+ (1,0) [0|1.844674407371E+019] ""  TestTool_FO

BO_ 579 USDT_Req_to_LFSRR: 8 TestTool_FO
 SG_ DgnInf : 7|64@0+ (1,0) [0|1.844674407371E+019] ""  LFSRR_FO

BO_ 577 USDT_Req_to_VIS: 8 TestTool_FO
 SG_ DgnInf : 7|64@0+ (1,0) [0|1.844674407371E+019] ""  VIS_FO

BO_ 578 USDT_Req_to_LRR: 8 TestTool_FO
 SG_ DgnInf : 7|64@0+ (1,0) [0|1.844674407371E+019] ""  LRR_FO

BO_ 582 USDT_Req_to_RFSRR: 8 TestTool_FO
 SG_ DgnInf : 7|64@0+ (1,0) [0|1.844674407371E+019] ""  RFSRR_FO

BO_ 601 USDT_Req_to_RSRR: 8 TestTool_FO
 SG_ DgnInf : 7|64@0+ (1,0) [0|1.844674407371E+019] ""  RSRR_FO

BO_ 1355 UUDT_Resp_From_FEOCM_FO: 8 EOCM_F_FO
 SG_ DgnInf_OBJ54B : 7|64@0+ (1,0) [0|1.844674407371E+019] ""  TestTool_FO

BO_ 587 USDT_Req_to_FEOCM_obj: 8 TestTool_FO
 SG_ DgnInf : 7|64@0+ (1,0) [0|1.844674407371E+019] ""  EOCM_F_FO

BO_ 784 Body_Info_FOB: 2 EOCM_F_FO
 SG_ SysPwrMdV : 8|1@0+ (1,0) [0|1] ""  VIS_FO,RSRR_FO,RFSRR_FO,LRR_FO,LFSRR_FO
 SG_ SysPwrMd : 10|2@0+ (1,0) [0|3] ""  VIS_FO,RSRR_FO,RFSRR_FO,LRR_FO,LFSRR_FO
 SG_ WSWprAct : 2|1@0+ (1,0) [0|1] ""  VIS_FO
 SG_ RtLwBmFld : 4|1@0+ (1,0) [0|1] ""  VIS_FO
 SG_ OtsdAmbtLtLvlStatV : 5|1@0+ (1,0) [0|1] ""  VIS_FO
 SG_ OtsdAmbtLtLvlStat : 7|2@0+ (1,0) [0|3] ""  VIS_FO
 SG_ LowBmAct : 1|1@0+ (1,0) [0|1] ""  VIS_FO
 SG_ LftLwBmFld : 3|1@0+ (1,0) [0|1] ""  VIS_FO
 SG_ HighBmAct : 0|1@0+ (1,0) [0|1] ""  VIS_FO

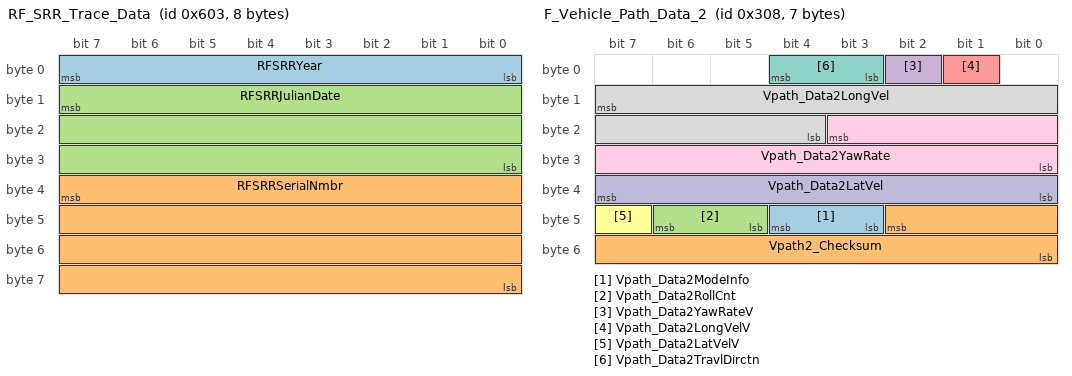
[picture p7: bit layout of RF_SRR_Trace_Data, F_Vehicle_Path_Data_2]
BO_ 1539 RF_SRR_Trace_Data: 8 RFSRR_FO
 SG_ RFSRRYear : 7|8@0+ (1,0) [0|0] ""  EOCM_F_FO
 SG_ RFSRRSerialNmbr : 39|32@0+ (1,0) [0|0] ""  EOCM_F_FO
 SG_ RFSRRJulianDate : 15|24@0+ (1,0) [0|0] ""  EOCM_F_FO

BO_ 776 F_Vehicle_Path_Data_2: 7 EOCM_F_FO
 SG_ Vpath_Data2ModeInfo : 44|2@0+ (1,0) [0|3] ""  VIS_FO,RSRR_FO,RFSRR_FO,LRR_FO,LFSRR_FO
 SG_ Vpath2_Checksum : 42|11@0+ (1,0) [0|2047] ""  VIS_FO,RFSRR_FO,LFSRR_FO,RSRR_FO,LRR_FO
 SG_ Vpath_Data2RollCnt : 46|2@0+ (1,0) [0|3] ""  VIS_FO,RSRR_FO,RFSRR_FO,LRR_FO,LFSRR_FO
 SG_ Vpath_Data2YawRateV : 2|1@0+ (1,0) [0|1] ""  VIS_FO,RSRR_FO,RFSRR_FO,LRR_FO,LFSRR_FO
 SG_ Vpath_Data2LongVelV : 1|1@0+ (1,0) [0|1] ""  VIS_FO,RSRR_FO,RFSRR_FO,LRR_FO,LFSRR_FO
 SG_ Vpath_Data2LatVelV : 47|1@0+ (1,0) [0|1] ""  VIS_FO,RSRR_FO,RFSRR_FO,LRR_FO,LFSRR_FO
 SG_ Vpath_Data2TravlDirctn : 4|2@0+ (1,0) [0|0] ""  VIS_FO,RSRR_FO,RFSRR_FO,LRR_FO,LFSRR_FO
 SG_ Vpath_Data2LongVel : 15|12@0- (0.0625,0) [-128|127.9375] "m/s"  VIS_FO,RSRR_FO,RFSRR_FO,LRR_FO,LFSRR_FO
 SG_ Vpath_Data2YawRate : 19|12@0- (0.0625,0) [-128|127.9375] "deg/s"  VIS_FO,RSRR_FO,RFSRR_FO,LRR_FO,LFSRR_FO
 SG_ Vpath_Data2LatVel : 39|8@0- (0.05,0) [-6.4|6.35] "m/s"  VIS_FO,RSRR_FO,RFSRR_FO,LRR_FO,LFSRR_FO

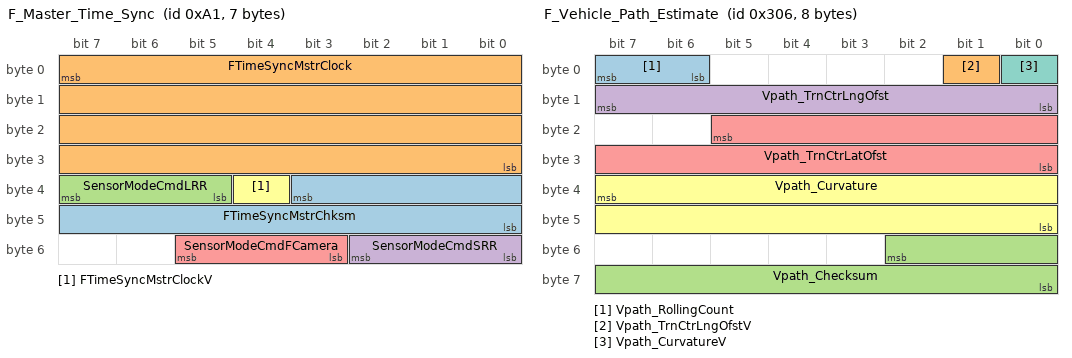
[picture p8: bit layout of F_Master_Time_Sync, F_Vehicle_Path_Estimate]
BO_ 161 F_Master_Time_Sync: 7 EOCM_F_FO
 SG_ FTimeSyncMstrChksm : 35|12@0+ (1,0) [0|4095] ""  VIS_FO,RSRR_FO,RFSRR_FO,LRR_FO,LFSRR_FO
 SG_ FTimeSyncMstrClock : 7|32@0+ (1,0) [0|4294967295] "ms"  VIS_FO,RSRR_FO,RFSRR_FO,LRR_FO,LFSRR_FO
 SG_ SensorModeCmdLRR : 39|3@0+ (1,0) [0|0] ""  VIS_FO,RSRR_FO,RFSRR_FO,LRR_FO,LFSRR_FO
 SG_ SensorModeCmdSRR : 50|3@0+ (1,0) [0|0] ""  VIS_FO,RSRR_FO,RFSRR_FO,LRR_FO,LFSRR_FO
 SG_ SensorModeCmdFCamera : 53|3@0+ (1,0) [0|0] ""  VIS_FO,RSRR_FO,RFSRR_FO,LRR_FO,LFSRR_FO
 SG_ FTimeSyncMstrClockV : 36|1@0+ (1,0) [0|1] ""  VIS_FO,RSRR_FO,LRR_FO,RFSRR_FO,LFSRR_FO

BO_ 774 F_Vehicle_Path_Estimate: 8 EOCM_F_FO
 SG_ Vpath_RollingCount : 7|2@0+ (1,0) [0|3] ""  VIS_FO,RSRR_FO,RFSRR_FO,LRR_FO,LFSRR_FO
 SG_ Vpath_TrnCtrLngOfstV : 1|1@0+ (1,0) [0|1] ""  LRR_FO,VIS_FO,RSRR_FO,RFSRR_FO,LFSRR_FO
 SG_ Vpath_Checksum : 50|11@0+ (1,0) [0|2047] ""  VIS_FO,RSRR_FO,RFSRR_FO,LRR_FO,LFSRR_FO
 SG_ Vpath_TrnCtrLngOfst : 15|8@0- (0.1,0) [-12.8|12.7] "m"  LRR_FO,VIS_FO,RSRR_FO,RFSRR_FO,LFSRR_FO
 SG_ Vpath_TrnCtrLatOfst : 21|14@0- (1,0) [-8192|8191] "m"  LRR_FO,VIS_FO,RSRR_FO,RFSRR_FO,LFSRR_FO
 SG_ Vpath_Curvature : 39|16@0- (1E-005,0) [-0.32768|0.32767] "1/m"  VIS_FO,RSRR_FO,RFSRR_FO,LRR_FO,LFSRR_FO
 SG_ Vpath_CurvatureV : 0|1@0+ (1,0) [0|1] ""  VIS_FO,LRR_FO,RSRR_FO,RFSRR_FO,LFSRR_FO

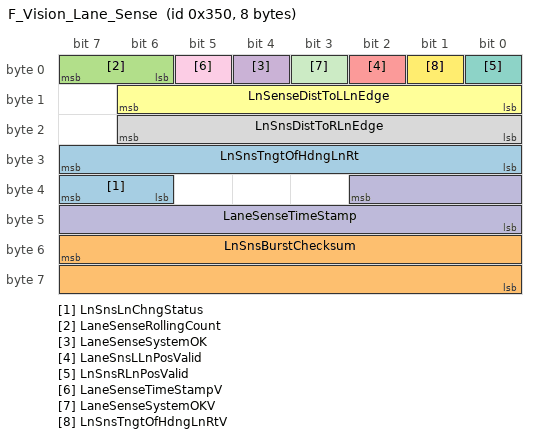
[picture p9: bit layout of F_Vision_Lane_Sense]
BO_ 848 F_Vision_Lane_Sense: 8 VIS_FO
 SG_ LnSnsLnChngStatus : 39|2@0+ (1,0) [0|3] ""  EOCM_F_FO
 SG_ LnSnsBurstChecksum : 55|16@0+ (1,0) [0|65535] ""  EOCM_F_FO
 SG_ LaneSenseRollingCount : 7|2@0+ (1,0) [0|3] ""  EOCM_F_FO
 SG_ LaneSenseSystemOK : 4|1@0+ (1,0) [0|1] ""  EOCM_F_FO
 SG_ LaneSnsLLnPosValid : 2|1@0+ (1,0) [0|1] ""  EOCM_F_FO
 SG_ LnSenseDistToLLnEdge : 14|7@0+ (0.05,0) [0|6.35] "m"  EOCM_F_FO
 SG_ LnSnsRLnPosValid : 0|1@0+ (1,0) [0|1] ""  EOCM_F_FO
 SG_ LnSnsDistToRLnEdge : 22|7@0+ (0.05,0) [0|6.35] "m"  EOCM_F_FO
 SG_ LaneSenseTimeStampV : 5|1@0+ (1,0) [0|1] ""  EOCM_F_FO
 SG_ LaneSenseTimeStamp : 34|11@0+ (1,0) [0|2047] "ms"  EOCM_F_FO
 SG_ LaneSenseSystemOKV : 3|1@0+ (1,0) [0|1] ""  EOCM_F_FO
 SG_ LnSnsTngtOfHdngLnRtV : 1|1@0+ (1,0) [0|1] ""  EOCM_F_FO
 SG_ LnSnsTngtOfHdngLnRt : 31|8@0- (0.002,0) [-0.256|0.254] "m/m"  EOCM_F_FO

CM_ "Front Object Bus (High Speed)";
CM_ BU_ Dummy_FO "This is for avoid signle ended signalling";
CM_ BU_ LRR_FO "Long Range Radar";
CM_ BU_ RFSRR_FO "Right Front Short Range Radar";
CM_ BU_ LFSRR_FO "Left Front Short Range Radar";
CM_ BU_ RSRR_FO "Rear Short Range Radar";
CM_ BU_ VIS_FO "Vision";
CM_ BU_ EOCM_F_FO "External Object Control Module - Front";
CM_ SG_ 1409 CPSTOSObjType "0 = unknown
1 = 4-wheel vehicle (car, small truck)
2 = large vehicle (semi)
3 = motorcycle/bicycle
4 = pedestrian
5 = fixed overhead object
6 = fixed roadside object
7 = no object present";
CM_ SG_ 1409 CPSTOSConfAsmt "0 = unknown
1 = 4-wheel vehicle (car, small truck)
2 = large vehicle (semi)
3 = motorcycle/bicycle
4 = pedestrian
5 = fixed overhead object
6 = fixed roadside object
7 = no object present";
CM_ SG_ 1409 CPSTOSNumCycTrkd "0 = 0
1 = 1
2 = less than 4
3 = less than 8
4 = less than 16
5 = less then 32
6 = less than 64
7 = 64 or more";
CM_ SG_ 1409 CPSTOSTimeToColl "0 = unknown
(This may not be tru TTC but rather time to intersection of target center with vehicle system origin)
";
CM_ SG_ 1409 CPSTOSClosestInPthVehRng "E=N*1/4";
CM_ SG_ 1409 CPSTOSClosestInPthObID "E=N*1";
BA_DEF_  "BusType" STRING ;
BA_DEF_ SG_  "VNSigSLHSSharedDiagnostic" ENUM  "No","Yes";
BA_DEF_ SG_  "SignalType" STRING ;
BA_DEF_ SG_  "PacketOrder" INT 0 65535;
BA_DEF_ SG_  "SignalLongName" STRING ;
BA_DEF_ SG_  "GenSigStartValue" INT 0 65535;
BA_DEF_ SG_  "VNSigAllNodes" ENUM  "No","Yes";
BA_DEF_ SG_  "GenSigSendType" ENUM  "not used","not used","not used","not used","not used","not used","not used","NoSigSendType","not used","not used","OnAnyChange","OnChangeIfActive","OnDelta";
BA_DEF_ SG_  "GenSigSendOnInit" ENUM  "Not Initialized","Application","Handler";
BA_DEF_ BO_  "GenMsgILSupport" ENUM  "No","Yes";
BA_DEF_ BO_  "TpApplType" STRING ;
BA_DEF_ BO_  "Prio" INT 0 7;
BA_DEF_ BO_  "MessageSubnet" ENUM  "LS","MS","HS","CE","PE","HV","FO";
BA_DEF_ BO_  "DiagState" ENUM  "No","Yes";
BA_DEF_ BO_  "GenMsgDelayTime" INT 0 100000;
BA_DEF_ BO_  "GenMsgCycleTime" INT 0 100000;
BA_DEF_ BO_  "GenMsgCycleTimeFast" INT 0 100000;
BA_DEF_ BO_  "GenMsgSendType" ENUM  "cyclicX","spontanX","cyclicIfActiveX","spontanWithDelay","cyclicAndSpontanX","cyclicAndSpontanWithDelay","spontanWithRepitition","cyclicIfActiveAndSpontanWD";
BA_DEF_ BO_  "DiagResponse" ENUM  "No","Yes";
BA_DEF_ BO_  "DiagRequest" ENUM  "No","Yes";
BA_DEF_ BO_  "NmMessage" ENUM  "No","Yes";
BA_DEF_ BU_  "MessageManagerUsed" ENUM  "No","Yes";
BA_DEF_ BU_  "NmNode" ENUM  "No","Yes";
BA_DEF_ BU_  "ILUsed" ENUM  "No","Yes";
BA_DEF_ BU_  "NodeLayerModules" STRING ;
BA_DEF_ BU_  "VNECUSLHSSharedDiagnostic" ENUM  "None","Activator","Remoted","Activator and Remoted","Shared Local";
BA_DEF_ BU_  "D22_ReqType" ENUM  "Functional","Physical","Both";
BA_DEF_ BU_  "D2D_ReqType" ENUM  "Functional","Physical","Both";
BA_DEF_ BU_  "DAE_ReqType" ENUM  "Functional","Physical","Both";
BA_DEF_ BU_  "DAA_ReqType" ENUM  "Functional","Physical","Both";
BA_DEF_ BU_  "DA9_ReqType" ENUM  "Functional","Physical","Both";
BA_DEF_ BU_  "DA9_FRdDiagInfo" ENUM  "No","Yes","vector_leerstring";
BA_DEF_ BU_  "DA5_ReqType" ENUM  "Functional","Physical","Both";
BA_DEF_ BU_  "DA5_FProgMode" ENUM  "No","Yes","vector_leerstring";
BA_DEF_ BU_  "DA2_ReqType" ENUM  "Functional","Physical","Both";
BA_DEF_ BU_  "DA2_FRptPrgStat" ENUM  "No","Yes","vector_leerstring";
BA_DEF_ BU_  "D3E_ReqType" ENUM  "Functional","Physical","Both";
BA_DEF_ BU_  "D3E_FTstrPres" ENUM  "No","Yes","vector_leerstring";
BA_DEF_ BU_  "D3B_ReqType" ENUM  "Functional","Physical","Both";
BA_DEF_ BU_  "D36_ReqType" ENUM  "Functional","Physical","Both";
BA_DEF_ BU_  "D36_FXfrData" ENUM  "No","Yes","vector_leerstring";
BA_DEF_ BU_  "D34_ReqType" ENUM  "Functional","Physical","Both";
BA_DEF_ BU_  "D34_FReqDwnld" ENUM  "No","Yes";
BA_DEF_ BU_  "D2C_ReqType" ENUM  "Functional","Physical","Both";
BA_DEF_ BU_  "D28_ReqType" ENUM  "Functional","Physical","Both";
BA_DEF_ BU_  "D28_FDisNormComm" ENUM  "No","Yes","vector_leerstring";
BA_DEF_ BU_  "D27_ReqType" ENUM  "Functional","Physical","Both";
BA_DEF_ BU_  "D23_ReqType" ENUM  "Functional","Physical","Both";
BA_DEF_ BU_  "D20_ReqType" ENUM  "Functional","Physical","Both";
BA_DEF_ BU_  "D20_FRtnNormComm" ENUM  "No","Yes","vector_leerstring";
BA_DEF_ BU_  "D1A_ReqType" ENUM  "Functional","Physical","Both";
BA_DEF_ BU_  "D1A_FRdDataID" ENUM  "No","Yes","vector_leerstring";
BA_DEF_ BU_  "D12_ReqType" ENUM  "Functional","Physical","Both";
BA_DEF_ BU_  "D10_ReqType" ENUM  "Functional","Physical ","Both";
BA_DEF_ BU_  "D10_FInitDiagOp" ENUM  "No","Yes","vector_leerstring";
BA_DEF_ BU_  "D04_ReqType" ENUM  "Functional","Physical","Both","vector_leerstring";
BA_DEF_ BU_  "D04_FClrDTC" ENUM  "No","Yes","vector_leerstring";
BA_DEF_ BU_  "VNECUAllNodes" ENUM  "None","Activator","Remoted","Activator and Remoted","Shared Local";
BA_DEF_ BU_  "ECU_Id" HEX 0 255;
BA_DEF_ BU_  "SourceId" HEX 0 253;
BA_DEF_  "SyncJumpWidthMax" INT 0 255;
BA_DEF_  "SyncJumpWidthMin" INT 0 255;
BA_DEF_  "SamplePointMax" FLOAT 0 100;
BA_DEF_  "SamplePointMin" FLOAT 0 100;
BA_DEF_  "Baudrate" INT 0 1000000;
BA_DEF_  "VehicleArchitecture" STRING ;
BA_DEF_  "VNInitActSLHSSharedDiagnostic" ENUM  "No","Yes";
BA_DEF_  "VN_SLHSSharedDiagnostic" INT 0 255;
BA_DEF_  "VersionNumber" INT 0 65535;
BA_DEF_  "NmMessageCount" INT 0 32;
BA_DEF_  "NmBaseAddress" HEX 0 2032;
BA_DEF_  "NetworkType" STRING ;
BA_DEF_  "VNMFPeriodicInterval" INT 0 65535;
BA_DEF_  "BusWakeUpDelay" INT 0 65535;
BA_DEF_  "BusOffRecoveryTime" INT 0 65535;
BA_DEF_  "NodeStatusMsgID" HEX 0 536870911;
BA_DEF_  "NodeStatusMsgCycleTime" INT 0 65535;
BA_DEF_  "NodeStatusMsgTimeoutTime" INT 0 65535;
BA_DEF_  "UseGMParameterIDs" INT 0 1;
BA_DEF_  "VersionWeek" INT 0 255;
BA_DEF_  "VersionYear" INT 0 255;
BA_DEF_  "VN_AllNodes" INT 0 255;
BA_DEF_  "Manufacturer" ENUM  "DBAG","VAG","BMW","PAG","GM";
BA_DEF_  "NmType" STRING ;
BA_DEF_REL_ BU_SG_REL_  "GenSigSuprvRespComment" STRING ;
BA_DEF_REL_ BU_SG_REL_  "GenSigVBitResp" ENUM  "No","Yes";
BA_DEF_REL_ BU_SG_REL_  "GenSigVBitRespComment" STRING ;
BA_DEF_REL_ BU_SG_REL_  "GenSigVDAFailComment" STRING ;
BA_DEF_REL_ BU_SG_REL_  "GenSigSuprvResp" ENUM  "None","Notify App","Substitute Default";
BA_DEF_REL_ BU_SG_REL_  "GenSigTimeoutMsg" HEX -2147483648 268435455;
BA_DEF_REL_ BU_SG_REL_  "GenSigTimeoutTime" INT 0 15000;
BA_DEF_DEF_  "BusType" "";
BA_DEF_DEF_  "VNSigSLHSSharedDiagnostic" "No";
BA_DEF_DEF_  "SignalType" "";
BA_DEF_DEF_  "PacketOrder" 0;
BA_DEF_DEF_  "SignalLongName" "";
BA_DEF_DEF_  "GenSigStartValue" 0;
BA_DEF_DEF_  "VNSigAllNodes" "No";
BA_DEF_DEF_  "GenSigSendType" "NoSigSendType";
BA_DEF_DEF_  "GenSigSendOnInit" "Not Initialized";
BA_DEF_DEF_  "GenMsgILSupport" "Yes";
BA_DEF_DEF_  "TpApplType" "";
BA_DEF_DEF_  "Prio" 4;
BA_DEF_DEF_  "MessageSubnet" "FO";
BA_DEF_DEF_  "DiagState" "No";
BA_DEF_DEF_  "GenMsgDelayTime" 0;
BA_DEF_DEF_  "GenMsgCycleTime" 0;
BA_DEF_DEF_  "GenMsgCycleTimeFast" 0;
BA_DEF_DEF_  "GenMsgSendType" "spontanX";
BA_DEF_DEF_  "DiagResponse" "No";
BA_DEF_DEF_  "DiagRequest" "No";
BA_DEF_DEF_  "NmMessage" "No";
BA_DEF_DEF_REL_ "GenSigSuprvRespComment" "";
BA_DEF_DEF_REL_ "GenSigVBitResp" "No";
BA_DEF_DEF_REL_ "GenSigVBitRespComment" "";
BA_DEF_DEF_REL_ "GenSigVDAFailComment" "";
BA_DEF_DEF_REL_ "GenSigSuprvResp" "None";
BA_DEF_DEF_REL_ "GenSigTimeoutMsg" 0;
BA_DEF_DEF_REL_ "GenSigTimeoutTime" 0;
BA_DEF_DEF_  "MessageManagerUsed" "Yes";
BA_DEF_DEF_  "NmNode" "Yes";
BA_DEF_DEF_  "ILUsed" "Yes";
BA_DEF_DEF_  "NodeLayerModules" "gmlan02.dll";
BA_DEF_DEF_  "VNECUSLHSSharedDiagnostic" "None";
BA_DEF_DEF_  "D22_ReqType" "Both";
BA_DEF_DEF_  "D2D_ReqType" "Both";
BA_DEF_DEF_  "DAE_ReqType" "Both";
BA_DEF_DEF_  "DAA_ReqType" "Both";
BA_DEF_DEF_  "DA9_ReqType" "Both";
BA_DEF_DEF_  "DA9_FRdDiagInfo" "Yes";
BA_DEF_DEF_  "DA5_ReqType" "Both";
BA_DEF_DEF_  "DA5_FProgMode" "Yes";
BA_DEF_DEF_  "DA2_ReqType" "Both";
BA_DEF_DEF_  "DA2_FRptPrgStat" "Yes";
BA_DEF_DEF_  "D3E_ReqType" "Both";
BA_DEF_DEF_  "D3E_FTstrPres" "Yes";
BA_DEF_DEF_  "D3B_ReqType" "Both";
BA_DEF_DEF_  "D36_ReqType" "Both";
BA_DEF_DEF_  "D36_FXfrData" "Yes";
BA_DEF_DEF_  "D34_ReqType" "Both";
BA_DEF_DEF_  "D34_FReqDwnld" "Yes";
BA_DEF_DEF_  "D2C_ReqType" "Both";
BA_DEF_DEF_  "D28_ReqType" "Both";
BA_DEF_DEF_  "D28_FDisNormComm" "Yes";
BA_DEF_DEF_  "D27_ReqType" "Both";
BA_DEF_DEF_  "D23_ReqType" "Both";
BA_DEF_DEF_  "D20_ReqType" "Both";
BA_DEF_DEF_  "D20_FRtnNormComm" "Yes";
BA_DEF_DEF_  "D1A_ReqType" "Both";
BA_DEF_DEF_  "D1A_FRdDataID" "Yes";
BA_DEF_DEF_  "D12_ReqType" "Both";
BA_DEF_DEF_  "D10_ReqType" "Both";
BA_DEF_DEF_  "D10_FInitDiagOp" "Yes";
BA_DEF_DEF_  "D04_ReqType" "Both";
BA_DEF_DEF_  "D04_FClrDTC" "Yes";
BA_DEF_DEF_  "VNECUAllNodes" "None";
BA_DEF_DEF_  "ECU_Id" 0;
BA_DEF_DEF_  "SourceId" 0;
BA_DEF_DEF_  "SyncJumpWidthMax" 0;
BA_DEF_DEF_  "SyncJumpWidthMin" 0;
BA_DEF_DEF_  "SamplePointMax" 0;
BA_DEF_DEF_  "SamplePointMin" 0;
BA_DEF_DEF_  "Baudrate" 0;
BA_DEF_DEF_  "VehicleArchitecture" "";
BA_DEF_DEF_  "VNInitActSLHSSharedDiagnostic" "No";
BA_DEF_DEF_  "VN_SLHSSharedDiagnostic" 0;
BA_DEF_DEF_  "VersionNumber" 0;
BA_DEF_DEF_  "NmMessageCount" 32;
BA_DEF_DEF_  "NmBaseAddress" 1568;
BA_DEF_DEF_  "NetworkType" "";
BA_DEF_DEF_  "VNMFPeriodicInterval" 3000;
BA_DEF_DEF_  "BusWakeUpDelay" 100;
BA_DEF_DEF_  "BusOffRecoveryTime" 0;
BA_DEF_DEF_  "NodeStatusMsgID" 268427264;
BA_DEF_DEF_  "NodeStatusMsgCycleTime" 1200;
BA_DEF_DEF_  "NodeStatusMsgTimeoutTime" 0;
BA_DEF_DEF_  "UseGMParameterIDs" 1;
BA_DEF_DEF_  "VersionWeek" 0;
BA_DEF_DEF_  "VersionYear" 0;
BA_DEF_DEF_  "VN_AllNodes" 1;
BA_DEF_DEF_  "Manufacturer" "GM";
BA_DEF_DEF_  "NmType" "GMLAN";
BA_ "SyncJumpWidthMax" 4;
BA_ "SyncJumpWidthMin" 3;
BA_ "SamplePointMax" 81.25;
BA_ "SamplePointMin" 80;
BA_ "Baudrate" 500000;
BA_ "VehicleArchitecture" "Global A";
BA_ "VNInitActSLHSSharedDiagnostic" 1;
BA_ "NmMessageCount" 16;
BA_ "NmBaseAddress" 1584;
BA_ "NetworkType" "Powertrain";
BA_ "BusWakeUpDelay" 70;
BA_ "BusOffRecoveryTime" 160;
BA_ "NodeStatusMsgID" 0;
BA_ "NodeStatusMsgCycleTime" 0;
BA_ "UseGMParameterIDs" 0;
BA_ "VersionWeek" 43;
BA_ "VersionYear" 5;
BA_ "BusType" "CAN";
BA_ "VNECUSLHSSharedDiagnostic" BU_ TestTool_FO 4;
BA_ "VNECUAllNodes" BU_ TestTool_FO 4;
BA_ "VNECUSLHSSharedDiagnostic" BU_ LRR_FO 4;
BA_ "VNECUAllNodes" BU_ LRR_FO 4;
BA_ "ECU_Id" BU_ LRR_FO 2;
BA_ "SourceId" BU_ LRR_FO 210;
BA_ "VNECUSLHSSharedDiagnostic" BU_ RFSRR_FO 4;
BA_ "VNECUAllNodes" BU_ RFSRR_FO 4;
BA_ "ECU_Id" BU_ RFSRR_FO 6;
BA_ "SourceId" BU_ RFSRR_FO 214;
BA_ "VNECUSLHSSharedDiagnostic" BU_ LFSRR_FO 4;
BA_ "VNECUAllNodes" BU_ LFSRR_FO 4;
BA_ "ECU_Id" BU_ LFSRR_FO 3;
BA_ "SourceId" BU_ LFSRR_FO 211;
BA_ "VNECUSLHSSharedDiagnostic" BU_ RSRR_FO 4;
BA_ "VNECUAllNodes" BU_ RSRR_FO 4;
BA_ "ECU_Id" BU_ RSRR_FO 7;
BA_ "SourceId" BU_ RSRR_FO 215;
BA_ "VNECUSLHSSharedDiagnostic" BU_ VIS_FO 4;
BA_ "VNECUAllNodes" BU_ VIS_FO 4;
BA_ "ECU_Id" BU_ VIS_FO 1;
BA_ "SourceId" BU_ VIS_FO 209;
BA_ "VNECUSLHSSharedDiagnostic" BU_ EOCM_F_FO 4;
BA_ "VNECUAllNodes" BU_ EOCM_F_FO 4;
BA_ "ECU_Id" BU_ EOCM_F_FO 11;
BA_ "SourceId" BU_ EOCM_F_FO 108;
BA_ "Prio" BO_ 1401 0;
BA_ "GenMsgCycleTime" BO_ 1401 100;
BA_ "GenMsgSendType" BO_ 1401 0;
BA_ "Prio" BO_ 1400 0;
BA_ "GenMsgCycleTime" BO_ 1400 100;
BA_ "GenMsgSendType" BO_ 1400 0;
BA_ "Prio" BO_ 1399 0;
BA_ "GenMsgCycleTime" BO_ 1399 100;
BA_ "GenMsgSendType" BO_ 1399 0;
BA_ "Prio" BO_ 1398 0;
BA_ "GenMsgCycleTime" BO_ 1398 100;
BA_ "GenMsgSendType" BO_ 1398 0;
BA_ "Prio" BO_ 1397 0;
BA_ "GenMsgCycleTime" BO_ 1397 100;
BA_ "GenMsgSendType" BO_ 1397 0;
BA_ "Prio" BO_ 1396 0;
BA_ "GenMsgCycleTime" BO_ 1396 100;
BA_ "GenMsgSendType" BO_ 1396 0;
BA_ "Prio" BO_ 1395 0;
BA_ "GenMsgCycleTime" BO_ 1395 100;
BA_ "GenMsgSendType" BO_ 1395 0;
BA_ "Prio" BO_ 1394 0;
BA_ "GenMsgCycleTime" BO_ 1394 100;
BA_ "GenMsgSendType" BO_ 1394 0;
BA_ "Prio" BO_ 1407 0;
BA_ "GenMsgCycleTime" BO_ 1407 100;
BA_ "GenMsgSendType" BO_ 1407 0;
BA_ "Prio" BO_ 1406 0;
BA_ "GenMsgCycleTime" BO_ 1406 100;
BA_ "GenMsgSendType" BO_ 1406 0;
BA_ "Prio" BO_ 1405 0;
BA_ "GenMsgCycleTime" BO_ 1405 100;
BA_ "GenMsgSendType" BO_ 1405 0;
BA_ "Prio" BO_ 1404 0;
BA_ "GenMsgCycleTime" BO_ 1404 100;
BA_ "GenMsgSendType" BO_ 1404 0;
BA_ "Prio" BO_ 1403 0;
BA_ "GenMsgCycleTime" BO_ 1403 100;
BA_ "GenMsgSendType" BO_ 1403 0;
BA_ "Prio" BO_ 1402 0;
BA_ "GenMsgCycleTime" BO_ 1402 100;
BA_ "GenMsgSendType" BO_ 1402 0;
BA_ "Prio" BO_ 1393 0;
BA_ "GenMsgCycleTime" BO_ 1393 100;
BA_ "GenMsgSendType" BO_ 1393 0;
BA_ "Prio" BO_ 1385 0;
BA_ "GenMsgCycleTime" BO_ 1385 100;
BA_ "GenMsgSendType" BO_ 1385 0;
BA_ "Prio" BO_ 1384 0;
BA_ "GenMsgCycleTime" BO_ 1384 100;
BA_ "GenMsgSendType" BO_ 1384 0;
BA_ "Prio" BO_ 1362 0;
BA_ "GenMsgCycleTime" BO_ 1362 100;
BA_ "GenMsgSendType" BO_ 1362 0;
BA_ "Prio" BO_ 1413 0;
BA_ "GenMsgCycleTime" BO_ 1413 100;
BA_ "GenMsgSendType" BO_ 1413 0;
BA_ "Prio" BO_ 1412 0;
BA_ "GenMsgCycleTime" BO_ 1412 100;
BA_ "GenMsgSendType" BO_ 1412 0;
BA_ "Prio" BO_ 1409 0;
BA_ "GenMsgCycleTime" BO_ 1409 100;
BA_ "GenMsgSendType" BO_ 1409 0;
BA_ "Prio" BO_ 1408 0;
BA_ "GenMsgCycleTime" BO_ 1408 100;
BA_ "GenMsgSendType" BO_ 1408 0;
BA_ "Prio" BO_ 1344 0;
BA_ "GenMsgCycleTime" BO_ 1344 100;
BA_ "GenMsgSendType" BO_ 1344 0;
BA_ "Prio" BO_ 770 0;
BA_ "GenMsgCycleTime" BO_ 770 100;
BA_ "GenMsgSendType" BO_ 770 0;
BA_ "GenMsgILSupport" BO_ 1601 0;
BA_ "Prio" BO_ 1601 0;
BA_ "DiagResponse" BO_ 1601 1;
BA_ "GenMsgILSupport" BO_ 1606 0;
BA_ "Prio" BO_ 1606 0;
BA_ "DiagResponse" BO_ 1606 1;
BA_ "GenMsgILSupport" BO_ 1603 0;
BA_ "Prio" BO_ 1603 0;
BA_ "DiagResponse" BO_ 1603 1;
BA_ "GenMsgILSupport" BO_ 1602 0;
BA_ "Prio" BO_ 1602 0;
BA_ "DiagResponse" BO_ 1602 1;
BA_ "GenMsgILSupport" BO_ 1625 0;
BA_ "Prio" BO_ 1625 0;
BA_ "DiagResponse" BO_ 1625 1;
BA_ "GenMsgILSupport" BO_ 1611 0;
BA_ "Prio" BO_ 1611 0;
BA_ "DiagResponse" BO_ 1611 1;
BA_ "Prio" BO_ 1383 0;
BA_ "GenMsgCycleTime" BO_ 1383 100;
BA_ "GenMsgSendType" BO_ 1383 0;
BA_ "Prio" BO_ 1382 0;
BA_ "GenMsgCycleTime" BO_ 1382 100;
BA_ "GenMsgSendType" BO_ 1382 0;
BA_ "Prio" BO_ 1381 0;
BA_ "GenMsgCycleTime" BO_ 1381 100;
BA_ "GenMsgSendType" BO_ 1381 0;
BA_ "Prio" BO_ 768 0;
BA_ "GenMsgCycleTime" BO_ 768 50;
BA_ "GenMsgSendType" BO_ 768 0;
BA_ "GenMsgILSupport" BO_ 1350 0;
BA_ "TpApplType" BO_ 1350 "DiagUUDTResponse";
BA_ "Prio" BO_ 1350 0;
BA_ "GenMsgILSupport" BO_ 1369 0;
BA_ "TpApplType" BO_ 1369 "DiagUUDTResponse";
BA_ "Prio" BO_ 1369 0;
BA_ "GenMsgILSupport" BO_ 1347 0;
BA_ "TpApplType" BO_ 1347 "DiagUUDTResponse";
BA_ "Prio" BO_ 1347 0;
BA_ "GenMsgILSupport" BO_ 1346 0;
BA_ "TpApplType" BO_ 1346 "DiagUUDTResponse";
BA_ "Prio" BO_ 1346 0;
BA_ "GenMsgILSupport" BO_ 1345 0;
BA_ "TpApplType" BO_ 1345 "DiagUUDTResponse";
BA_ "Prio" BO_ 1345 0;
BA_ "GenMsgILSupport" BO_ 579 0;
BA_ "Prio" BO_ 579 0;
BA_ "DiagRequest" BO_ 579 1;
BA_ "GenMsgILSupport" BO_ 577 0;
BA_ "Prio" BO_ 577 0;
BA_ "DiagRequest" BO_ 577 1;
BA_ "GenMsgILSupport" BO_ 578 0;
BA_ "Prio" BO_ 578 0;
BA_ "DiagRequest" BO_ 578 1;
BA_ "GenMsgILSupport" BO_ 582 0;
BA_ "Prio" BO_ 582 0;
BA_ "DiagRequest" BO_ 582 1;
BA_ "GenMsgILSupport" BO_ 601 0;
BA_ "Prio" BO_ 601 0;
BA_ "DiagRequest" BO_ 601 1;
BA_ "GenMsgILSupport" BO_ 1355 0;
BA_ "TpApplType" BO_ 1355 "DiagUUDTResponse";
BA_ "Prio" BO_ 1355 0;
BA_ "GenMsgILSupport" BO_ 587 0;
BA_ "Prio" BO_ 587 0;
BA_ "DiagRequest" BO_ 587 1;
BA_ "Prio" BO_ 784 0;
BA_ "GenMsgDelayTime" BO_ 784 10;
BA_ "GenMsgCycleTime" BO_ 784 100;
BA_ "GenMsgSendType" BO_ 784 0;
BA_ "Prio" BO_ 1539 0;
BA_ "GenMsgDelayTime" BO_ 1539 10;
BA_ "Prio" BO_ 776 0;
BA_ "GenMsgCycleTime" BO_ 776 20;
BA_ "GenMsgSendType" BO_ 776 0;
BA_ "Prio" BO_ 161 0;
BA_ "GenMsgCycleTime" BO_ 161 100;
BA_ "GenMsgSendType" BO_ 161 0;
BA_ "Prio" BO_ 774 0;
BA_ "GenMsgCycleTime" BO_ 774 20;
BA_ "GenMsgSendType" BO_ 774 0;
BA_ "Prio" BO_ 848 0;
BA_ "GenMsgDelayTime" BO_ 848 55;
BA_ "SignalType" SG_ 1401 RwdFusTrkBAnlgRlLn9 "SNM";
BA_ "SignalLongName" SG_ 1401 RwdFusTrkBAnlgRlLn9 "Rwd Fusion Track B Analog relative Lane 9";
BA_ "VNSigAllNodes" SG_ 1401 RwdFusTrkBAnlgRlLn9 1;
BA_ "SignalType" SG_ 1401 RwdFusTrkB9RollingCnt "UNM";
BA_ "SignalLongName" SG_ 1401 RwdFusTrkB9RollingCnt "Rearward Fusion Track B9 Rolling Count";
BA_ "VNSigAllNodes" SG_ 1401 RwdFusTrkB9RollingCnt 1;
BA_ "SignalType" SG_ 1401 RwdFusTrkB9Width "UNM";
BA_ "SignalLongName" SG_ 1401 RwdFusTrkB9Width "Rearward Fusion Track B9 Width";
BA_ "GenSigStartValue" SG_ 1401 RwdFusTrkB9Width 1;
BA_ "VNSigAllNodes" SG_ 1401 RwdFusTrkB9Width 1;
BA_ "SignalType" SG_ 1401 RwdFusTrkB9MsgIndex "UNM";
BA_ "SignalLongName" SG_ 1401 RwdFusTrkB9MsgIndex "Rearward Fusion Track B9 Message Index";
BA_ "VNSigAllNodes" SG_ 1401 RwdFusTrkB9MsgIndex 1;
BA_ "SignalType" SG_ 1401 RwdFusTrkB9DynProp "ENM";
BA_ "SignalLongName" SG_ 1401 RwdFusTrkB9DynProp "Rearward Fusion Track B9 Dynamic Property";
BA_ "VNSigAllNodes" SG_ 1401 RwdFusTrkB9DynProp 1;
BA_ "SignalType" SG_ 1401 RwdFusTrkB9RelLnAccl "SNM";
BA_ "SignalLongName" SG_ 1401 RwdFusTrkB9RelLnAccl "Rearward Fusion Track B9 Relative Lane Acceleration";
BA_ "VNSigAllNodes" SG_ 1401 RwdFusTrkB9RelLnAccl 1;
BA_ "SignalType" SG_ 1401 RwdFusTrkB9RelLane "ENM";
BA_ "SignalLongName" SG_ 1401 RwdFusTrkB9RelLane "Rearward Fusion Track B9 Relative Lane";
BA_ "VNSigAllNodes" SG_ 1401 RwdFusTrkB9RelLane 1;
BA_ "SignalType" SG_ 1401 RwdFusTrkB9Height "UNM";
BA_ "SignalLongName" SG_ 1401 RwdFusTrkB9Height "Rearward Fusion Track B9 Height";
BA_ "GenSigStartValue" SG_ 1401 RwdFusTrkB9Height 1;
BA_ "VNSigAllNodes" SG_ 1401 RwdFusTrkB9Height 1;
BA_ "SignalType" SG_ 1401 RFusTrkB9ObjSrcLFSrr "ENM";
BA_ "SignalLongName" SG_ 1401 RFusTrkB9ObjSrcLFSrr "Rearward Fusion Track B9 Object Source LFSRR";
BA_ "VNSigAllNodes" SG_ 1401 RFusTrkB9ObjSrcLFSrr 1;
BA_ "SignalType" SG_ 1401 RFusTrkB9ObjSrcLCSrr "ENM";
BA_ "SignalLongName" SG_ 1401 RFusTrkB9ObjSrcLCSrr "Rearward Fusion Track B9 Object Source LCSRR";
BA_ "VNSigAllNodes" SG_ 1401 RFusTrkB9ObjSrcLCSrr 1;
BA_ "SignalType" SG_ 1401 RFusTrkB9ObjSrcRCSrr "ENM";
BA_ "SignalLongName" SG_ 1401 RFusTrkB9ObjSrcRCSrr "Rearward Fusion Track B9 Object Source RCSRR";
BA_ "VNSigAllNodes" SG_ 1401 RFusTrkB9ObjSrcRCSrr 1;
BA_ "SignalType" SG_ 1401 RFusTrkB9ObjSrcRFSrr "ENM";
BA_ "SignalLongName" SG_ 1401 RFusTrkB9ObjSrcRFSrr "Rearward Fusion Track B9 Object Source RFSRR";
BA_ "VNSigAllNodes" SG_ 1401 RFusTrkB9ObjSrcRFSrr 1;
BA_ "SignalType" SG_ 1401 RFusTrkB9ObjSrcVIs "ENM";
BA_ "SignalLongName" SG_ 1401 RFusTrkB9ObjSrcVIs "Rearward Fusion Track B9 Object Source VIS";
BA_ "VNSigAllNodes" SG_ 1401 RFusTrkB9ObjSrcVIs 1;
BA_ "SignalType" SG_ 1401 RwdFusTrkB9ObjSrcLrr "ENM";
BA_ "SignalLongName" SG_ 1401 RwdFusTrkB9ObjSrcLrr "Rearward Fusion Track B9 Object Source LRR";
BA_ "VNSigAllNodes" SG_ 1401 RwdFusTrkB9ObjSrcLrr 1;
BA_ "SignalType" SG_ 1401 RwdFusTrkB9NmCycTrkd "UNM";
BA_ "SignalLongName" SG_ 1401 RwdFusTrkB9NmCycTrkd "Rearward Fusion Track B9 Number of Cycles Tracked";
BA_ "VNSigAllNodes" SG_ 1401 RwdFusTrkB9NmCycTrkd 1;
BA_ "SignalType" SG_ 1401 RwdFusTrkB9LatPosDev "UNM";
BA_ "SignalLongName" SG_ 1401 RwdFusTrkB9LatPosDev "Rearward Fusion Track B9 Lateral Position Deviation";
BA_ "VNSigAllNodes" SG_ 1401 RwdFusTrkB9LatPosDev 1;
BA_ "SignalType" SG_ 1401 RwdFusTrkB9LngPosDev "UNM";
BA_ "SignalLongName" SG_ 1401 RwdFusTrkB9LngPosDev "Rearward Fusion Track B9 Longitudinal Positioin Deviation";
BA_ "VNSigAllNodes" SG_ 1401 RwdFusTrkB9LngPosDev 1;
BA_ "SignalType" SG_ 1400 RwdFusTrkBAnlgRlLn8 "SNM";
BA_ "SignalLongName" SG_ 1400 RwdFusTrkBAnlgRlLn8 "Rwd Fusion Track B Analog relative Lane 8";
BA_ "VNSigAllNodes" SG_ 1400 RwdFusTrkBAnlgRlLn8 1;
BA_ "SignalType" SG_ 1400 RwdFusTrkB8RollingCnt "UNM";
BA_ "SignalLongName" SG_ 1400 RwdFusTrkB8RollingCnt "Rearward Fusion Track B8 Rolling Count";
BA_ "VNSigAllNodes" SG_ 1400 RwdFusTrkB8RollingCnt 1;
BA_ "SignalType" SG_ 1400 RwdFusTrkB8Width "UNM";
BA_ "SignalLongName" SG_ 1400 RwdFusTrkB8Width "Rearward Fusion Track B8 Width";
BA_ "GenSigStartValue" SG_ 1400 RwdFusTrkB8Width 1;
BA_ "VNSigAllNodes" SG_ 1400 RwdFusTrkB8Width 1;
BA_ "SignalType" SG_ 1400 RwdFusTrkB8MsgIndex "UNM";
BA_ "SignalLongName" SG_ 1400 RwdFusTrkB8MsgIndex "Rearward Fusion Track B8 Message Index";
BA_ "VNSigAllNodes" SG_ 1400 RwdFusTrkB8MsgIndex 1;
BA_ "SignalType" SG_ 1400 RwdFusTrkB8DynProp "ENM";
BA_ "SignalLongName" SG_ 1400 RwdFusTrkB8DynProp "Rearward Fusion Track B8 Dynamic Property";
BA_ "VNSigAllNodes" SG_ 1400 RwdFusTrkB8DynProp 1;
BA_ "SignalType" SG_ 1400 RwdFusTrkB8RelLnAccl "SNM";
BA_ "SignalLongName" SG_ 1400 RwdFusTrkB8RelLnAccl "Rearward Fusion Track B8 Relative Lane Acceleration";
BA_ "VNSigAllNodes" SG_ 1400 RwdFusTrkB8RelLnAccl 1;
BA_ "SignalType" SG_ 1400 RwdFusTrkB8RelLane "ENM";
BA_ "SignalLongName" SG_ 1400 RwdFusTrkB8RelLane "Rearward Fusion Track B8 Relative Lane";
BA_ "VNSigAllNodes" SG_ 1400 RwdFusTrkB8RelLane 1;
BA_ "SignalType" SG_ 1400 RwdFusTrkB8Height "UNM";
BA_ "SignalLongName" SG_ 1400 RwdFusTrkB8Height "Rearward Fusion Track B8 Height";
BA_ "GenSigStartValue" SG_ 1400 RwdFusTrkB8Height 1;
BA_ "VNSigAllNodes" SG_ 1400 RwdFusTrkB8Height 1;
BA_ "SignalType" SG_ 1400 RFusTrkB8ObjSrcLFSrr "ENM";
BA_ "SignalLongName" SG_ 1400 RFusTrkB8ObjSrcLFSrr "Rearward Fusion Track B8 Object Source LFSRR";
BA_ "VNSigAllNodes" SG_ 1400 RFusTrkB8ObjSrcLFSrr 1;
BA_ "SignalType" SG_ 1400 RFusTrkB8ObjSrcLCSrr "ENM";
BA_ "SignalLongName" SG_ 1400 RFusTrkB8ObjSrcLCSrr "Rearward Fusion Track B8 Object Source LCSRR";
BA_ "VNSigAllNodes" SG_ 1400 RFusTrkB8ObjSrcLCSrr 1;
BA_ "SignalType" SG_ 1400 RFusTrkB8ObjSrcRCSrr "ENM";
BA_ "SignalLongName" SG_ 1400 RFusTrkB8ObjSrcRCSrr "Rearward Fusion Track B8 Object Source RCSRR";
BA_ "VNSigAllNodes" SG_ 1400 RFusTrkB8ObjSrcRCSrr 1;
BA_ "SignalType" SG_ 1400 RFusTrkB8ObjSrcRFSrr "ENM";
BA_ "SignalLongName" SG_ 1400 RFusTrkB8ObjSrcRFSrr "Rearward Fusion Track B8 Object Source RFSRR";
BA_ "VNSigAllNodes" SG_ 1400 RFusTrkB8ObjSrcRFSrr 1;
BA_ "SignalType" SG_ 1400 RFusTrkB8ObjSrcVIs "ENM";
BA_ "SignalLongName" SG_ 1400 RFusTrkB8ObjSrcVIs "Rearward Fusion Track B8 Object Source VIS";
BA_ "VNSigAllNodes" SG_ 1400 RFusTrkB8ObjSrcVIs 1;
BA_ "SignalType" SG_ 1400 RwdFusTrkB8ObjSrcLrr "ENM";
BA_ "SignalLongName" SG_ 1400 RwdFusTrkB8ObjSrcLrr "Rearward Fusion Track B8 Object Source LRR";
BA_ "VNSigAllNodes" SG_ 1400 RwdFusTrkB8ObjSrcLrr 1;
BA_ "SignalType" SG_ 1400 RwdFusTrkB8NmCycTrkd "UNM";
BA_ "SignalLongName" SG_ 1400 RwdFusTrkB8NmCycTrkd "Rearward Fusion Track B8 Number of Cycles Tracked";
BA_ "VNSigAllNodes" SG_ 1400 RwdFusTrkB8NmCycTrkd 1;
BA_ "SignalType" SG_ 1400 RwdFusTrkB8LatPosDev "UNM";
BA_ "SignalLongName" SG_ 1400 RwdFusTrkB8LatPosDev "Rearward Fusion Track B8 Lateral Position Deviation";
BA_ "VNSigAllNodes" SG_ 1400 RwdFusTrkB8LatPosDev 1;
BA_ "SignalType" SG_ 1400 RwdFusTrkB8LngPosDev "UNM";
BA_ "SignalLongName" SG_ 1400 RwdFusTrkB8LngPosDev "Rearward Fusion Track B8 Longitudinal Positioin Deviation";
BA_ "VNSigAllNodes" SG_ 1400 RwdFusTrkB8LngPosDev 1;
BA_ "SignalType" SG_ 1399 RwdFusTrkBAnlgRlLn7 "SNM";
BA_ "SignalLongName" SG_ 1399 RwdFusTrkBAnlgRlLn7 "Rwd Fusion Track B Analog relative Lane 7";
BA_ "VNSigAllNodes" SG_ 1399 RwdFusTrkBAnlgRlLn7 1;
BA_ "SignalType" SG_ 1399 RwdFusTrkB7RollingCnt "UNM";
BA_ "SignalLongName" SG_ 1399 RwdFusTrkB7RollingCnt "Rearward Fusion Track B7 Rolling Count";
BA_ "VNSigAllNodes" SG_ 1399 RwdFusTrkB7RollingCnt 1;
BA_ "SignalType" SG_ 1399 RwdFusTrkB7Width "UNM";
BA_ "SignalLongName" SG_ 1399 RwdFusTrkB7Width "Rearward Fusion Track B7 Width";
BA_ "GenSigStartValue" SG_ 1399 RwdFusTrkB7Width 1;
BA_ "VNSigAllNodes" SG_ 1399 RwdFusTrkB7Width 1;
BA_ "SignalType" SG_ 1399 RwdFusTrkB7MsgIndex "UNM";
BA_ "SignalLongName" SG_ 1399 RwdFusTrkB7MsgIndex "Rearward Fusion Track B7 Message Index";
BA_ "VNSigAllNodes" SG_ 1399 RwdFusTrkB7MsgIndex 1;
BA_ "SignalType" SG_ 1399 RwdFusTrkB7DynProp "ENM";
BA_ "SignalLongName" SG_ 1399 RwdFusTrkB7DynProp "Rearward Fusion Track B7 Dynamic Property";
BA_ "VNSigAllNodes" SG_ 1399 RwdFusTrkB7DynProp 1;
BA_ "SignalType" SG_ 1399 RwdFusTrkB7RelLnAccl "SNM";
BA_ "SignalLongName" SG_ 1399 RwdFusTrkB7RelLnAccl "Rearward Fusion Track B7 Relative Lane Acceleration";
BA_ "VNSigAllNodes" SG_ 1399 RwdFusTrkB7RelLnAccl 1;
BA_ "SignalType" SG_ 1399 RwdFusTrkB7RelLane "ENM";
BA_ "SignalLongName" SG_ 1399 RwdFusTrkB7RelLane "Rearward Fusion Track B7 Relative Lane";
BA_ "VNSigAllNodes" SG_ 1399 RwdFusTrkB7RelLane 1;
BA_ "SignalType" SG_ 1399 RwdFusTrkB7Height "UNM";
BA_ "SignalLongName" SG_ 1399 RwdFusTrkB7Height "Rearward Fusion Track B7 Height";
BA_ "GenSigStartValue" SG_ 1399 RwdFusTrkB7Height 1;
BA_ "VNSigAllNodes" SG_ 1399 RwdFusTrkB7Height 1;
BA_ "SignalType" SG_ 1399 RFusTrkB7ObjSrcLFSrr "ENM";
BA_ "SignalLongName" SG_ 1399 RFusTrkB7ObjSrcLFSrr "Rearward Fusion Track B7 Object Source LFSRR";
BA_ "VNSigAllNodes" SG_ 1399 RFusTrkB7ObjSrcLFSrr 1;
BA_ "SignalType" SG_ 1399 RFusTrkB7ObjSrcLCSrr "ENM";
BA_ "SignalLongName" SG_ 1399 RFusTrkB7ObjSrcLCSrr "Rearward Fusion Track B7 Object Source LCSRR";
BA_ "VNSigAllNodes" SG_ 1399 RFusTrkB7ObjSrcLCSrr 1;
BA_ "SignalType" SG_ 1399 RFusTrkB7ObjSrcRCSrr "ENM";
BA_ "SignalLongName" SG_ 1399 RFusTrkB7ObjSrcRCSrr "Rearward Fusion Track B7 Object Source RCSRR";
BA_ "VNSigAllNodes" SG_ 1399 RFusTrkB7ObjSrcRCSrr 1;
BA_ "SignalType" SG_ 1399 RFusTrkB7ObjSrcRFSrr "ENM";
BA_ "SignalLongName" SG_ 1399 RFusTrkB7ObjSrcRFSrr "Rearward Fusion Track B7 Object Source RFSRR";
BA_ "VNSigAllNodes" SG_ 1399 RFusTrkB7ObjSrcRFSrr 1;
BA_ "SignalType" SG_ 1399 RFusTrkB7ObjSrcVIs "ENM";
BA_ "SignalLongName" SG_ 1399 RFusTrkB7ObjSrcVIs "Rearward Fusion Track B7 Object Source VIS";
BA_ "VNSigAllNodes" SG_ 1399 RFusTrkB7ObjSrcVIs 1;
BA_ "SignalType" SG_ 1399 RwdFusTrkB7ObjSrcLrr "ENM";
BA_ "SignalLongName" SG_ 1399 RwdFusTrkB7ObjSrcLrr "Rearward Fusion Track B7 Object Source LRR";
BA_ "VNSigAllNodes" SG_ 1399 RwdFusTrkB7ObjSrcLrr 1;
BA_ "SignalType" SG_ 1399 RwdFusTrkB7NmCycTrkd "UNM";
BA_ "SignalLongName" SG_ 1399 RwdFusTrkB7NmCycTrkd "Rearward Fusion Track B7 Number of Cycles Tracked";
BA_ "VNSigAllNodes" SG_ 1399 RwdFusTrkB7NmCycTrkd 1;
BA_ "SignalType" SG_ 1399 RwdFusTrkB7LatPosDev "UNM";
BA_ "SignalLongName" SG_ 1399 RwdFusTrkB7LatPosDev "Rearward Fusion Track B7 Lateral Position Deviation";
BA_ "VNSigAllNodes" SG_ 1399 RwdFusTrkB7LatPosDev 1;
BA_ "SignalType" SG_ 1399 RwdFusTrkB7LngPosDev "UNM";
BA_ "SignalLongName" SG_ 1399 RwdFusTrkB7LngPosDev "Rearward Fusion Track B7 Longitudinal Positioin Deviation";
BA_ "VNSigAllNodes" SG_ 1399 RwdFusTrkB7LngPosDev 1;
BA_ "SignalType" SG_ 1398 RwdFusTrkB6LngPosDev "UNM";
BA_ "SignalLongName" SG_ 1398 RwdFusTrkB6LngPosDev "Rearward Fusion Track B6 Longitudinal Positioin Deviation";
BA_ "VNSigAllNodes" SG_ 1398 RwdFusTrkB6LngPosDev 1;
BA_ "SignalType" SG_ 1398 RwdFusTrkBAnlgRlLn6 "SNM";
BA_ "SignalLongName" SG_ 1398 RwdFusTrkBAnlgRlLn6 "Rwd Fusion Track B Analog relative Lane 6";
BA_ "VNSigAllNodes" SG_ 1398 RwdFusTrkBAnlgRlLn6 1;
BA_ "SignalType" SG_ 1398 RwdFusTrkB6RollingCnt "UNM";
BA_ "SignalLongName" SG_ 1398 RwdFusTrkB6RollingCnt "Rearward Fusion Track B6 Rolling Count";
BA_ "VNSigAllNodes" SG_ 1398 RwdFusTrkB6RollingCnt 1;
BA_ "SignalType" SG_ 1398 RwdFusTrkB6Width "UNM";
BA_ "SignalLongName" SG_ 1398 RwdFusTrkB6Width "Rearward Fusion Track B6 Width";
BA_ "GenSigStartValue" SG_ 1398 RwdFusTrkB6Width 1;
BA_ "VNSigAllNodes" SG_ 1398 RwdFusTrkB6Width 1;
BA_ "SignalType" SG_ 1398 RwdFusTrkB6MsgIndex "UNM";
BA_ "SignalLongName" SG_ 1398 RwdFusTrkB6MsgIndex "Rearward Fusion Track B6 Message Index";
BA_ "VNSigAllNodes" SG_ 1398 RwdFusTrkB6MsgIndex 1;
BA_ "SignalType" SG_ 1398 RwdFusTrkB6DynProp "ENM";
BA_ "SignalLongName" SG_ 1398 RwdFusTrkB6DynProp "Rearward Fusion Track B6 Dynamic Property";
BA_ "VNSigAllNodes" SG_ 1398 RwdFusTrkB6DynProp 1;
BA_ "SignalType" SG_ 1398 RwdFusTrkB6RelLnAccl "SNM";
BA_ "SignalLongName" SG_ 1398 RwdFusTrkB6RelLnAccl "Rearward Fusion Track B6 Relative Lane Acceleration";
BA_ "VNSigAllNodes" SG_ 1398 RwdFusTrkB6RelLnAccl 1;
BA_ "SignalType" SG_ 1398 RwdFusTrkB6RelLane "ENM";
BA_ "SignalLongName" SG_ 1398 RwdFusTrkB6RelLane "Rearward Fusion Track B6 Relative Lane";
BA_ "VNSigAllNodes" SG_ 1398 RwdFusTrkB6RelLane 1;
BA_ "SignalType" SG_ 1398 RwdFusTrkB6Height "UNM";
BA_ "SignalLongName" SG_ 1398 RwdFusTrkB6Height "Rearward Fusion Track B6 Height";
BA_ "GenSigStartValue" SG_ 1398 RwdFusTrkB6Height 1;
BA_ "VNSigAllNodes" SG_ 1398 RwdFusTrkB6Height 1;
BA_ "SignalType" SG_ 1398 RFusTrkB6ObjSrcLFSrr "ENM";
BA_ "SignalLongName" SG_ 1398 RFusTrkB6ObjSrcLFSrr "Rearward Fusion Track B6 Object Source LFSRR";
BA_ "VNSigAllNodes" SG_ 1398 RFusTrkB6ObjSrcLFSrr 1;
BA_ "SignalType" SG_ 1398 RFusTrkB6ObjSrcLCSrr "ENM";
BA_ "SignalLongName" SG_ 1398 RFusTrkB6ObjSrcLCSrr "Rearward Fusion Track B6 Object Source LCSRR";
BA_ "VNSigAllNodes" SG_ 1398 RFusTrkB6ObjSrcLCSrr 1;
BA_ "SignalType" SG_ 1398 RFusTrkB6ObjSrcRCSrr "ENM";
BA_ "SignalLongName" SG_ 1398 RFusTrkB6ObjSrcRCSrr "Rearward Fusion Track B6 Object Source RCSRR";
BA_ "VNSigAllNodes" SG_ 1398 RFusTrkB6ObjSrcRCSrr 1;
BA_ "SignalType" SG_ 1398 RFusTrkB6ObjSrcRFSrr "ENM";
BA_ "SignalLongName" SG_ 1398 RFusTrkB6ObjSrcRFSrr "Rearward Fusion Track B6 Object Source RFSRR";
BA_ "VNSigAllNodes" SG_ 1398 RFusTrkB6ObjSrcRFSrr 1;
BA_ "SignalType" SG_ 1398 RFusTrkB6ObjSrcVIs "ENM";
BA_ "SignalLongName" SG_ 1398 RFusTrkB6ObjSrcVIs "Rearward Fusion Track B6 Object Source VIS";
BA_ "VNSigAllNodes" SG_ 1398 RFusTrkB6ObjSrcVIs 1;
BA_ "SignalType" SG_ 1398 RwdFusTrkB6ObjSrcLrr "ENM";
BA_ "SignalLongName" SG_ 1398 RwdFusTrkB6ObjSrcLrr "Rearward Fusion Track B6 Object Source LRR";
BA_ "VNSigAllNodes" SG_ 1398 RwdFusTrkB6ObjSrcLrr 1;
BA_ "SignalType" SG_ 1398 RwdFusTrkB6NmCycTrkd "UNM";
BA_ "SignalLongName" SG_ 1398 RwdFusTrkB6NmCycTrkd "Rearward Fusion Track B6 Number of Cycles Tracked";
BA_ "VNSigAllNodes" SG_ 1398 RwdFusTrkB6NmCycTrkd 1;
BA_ "SignalType" SG_ 1398 RwdFusTrkB6LatPosDev "UNM";
BA_ "SignalLongName" SG_ 1398 RwdFusTrkB6LatPosDev "Rearward Fusion Track B6 Lateral Position Deviation";
BA_ "VNSigAllNodes" SG_ 1398 RwdFusTrkB6LatPosDev 1;
BA_ "SignalType" SG_ 1397 RwdFusTrkBAnlgRlLn5 "SNM";
BA_ "SignalLongName" SG_ 1397 RwdFusTrkBAnlgRlLn5 "Rwd Fusion Track B Analog relative Lane 5";
BA_ "VNSigAllNodes" SG_ 1397 RwdFusTrkBAnlgRlLn5 1;
BA_ "SignalType" SG_ 1397 RwdFusTrkB5RollingCnt "UNM";
BA_ "SignalLongName" SG_ 1397 RwdFusTrkB5RollingCnt "Rearward Fusion Track B5 Rolling Count";
BA_ "VNSigAllNodes" SG_ 1397 RwdFusTrkB5RollingCnt 1;
BA_ "SignalType" SG_ 1397 RwdFusTrkB5Width "UNM";
BA_ "SignalLongName" SG_ 1397 RwdFusTrkB5Width "Rearward Fusion Track B5 Width";
BA_ "GenSigStartValue" SG_ 1397 RwdFusTrkB5Width 1;
BA_ "VNSigAllNodes" SG_ 1397 RwdFusTrkB5Width 1;
BA_ "SignalType" SG_ 1397 RwdFusTrkB5MsgIndex "UNM";
BA_ "SignalLongName" SG_ 1397 RwdFusTrkB5MsgIndex "Rearward Fusion Track B5 Message Index";
BA_ "VNSigAllNodes" SG_ 1397 RwdFusTrkB5MsgIndex 1;
BA_ "SignalType" SG_ 1397 RwdFusTrkB5DynProp "ENM";
BA_ "SignalLongName" SG_ 1397 RwdFusTrkB5DynProp "Rearward Fusion Track B5 Dynamic Property";
BA_ "VNSigAllNodes" SG_ 1397 RwdFusTrkB5DynProp 1;
BA_ "SignalType" SG_ 1397 RwdFusTrkB5RelLnAccl "SNM";
BA_ "SignalLongName" SG_ 1397 RwdFusTrkB5RelLnAccl "Rearward Fusion Track B5 Relative Lane Acceleration";
BA_ "VNSigAllNodes" SG_ 1397 RwdFusTrkB5RelLnAccl 1;
BA_ "SignalType" SG_ 1397 RwdFusTrkB5RelLane "ENM";
BA_ "SignalLongName" SG_ 1397 RwdFusTrkB5RelLane "Rearward Fusion Track B5 Relative Lane";
BA_ "VNSigAllNodes" SG_ 1397 RwdFusTrkB5RelLane 1;
BA_ "SignalType" SG_ 1397 RwdFusTrkB5Height "UNM";
BA_ "SignalLongName" SG_ 1397 RwdFusTrkB5Height "Rearward Fusion Track B5 Height";
BA_ "GenSigStartValue" SG_ 1397 RwdFusTrkB5Height 1;
BA_ "VNSigAllNodes" SG_ 1397 RwdFusTrkB5Height 1;
BA_ "SignalType" SG_ 1397 RFusTrkB5ObjSrcLFSrr "ENM";
BA_ "SignalLongName" SG_ 1397 RFusTrkB5ObjSrcLFSrr "Rearward Fusion Track B5 Object Source LFSRR";
BA_ "VNSigAllNodes" SG_ 1397 RFusTrkB5ObjSrcLFSrr 1;
BA_ "SignalType" SG_ 1397 RFusTrkB5ObjSrcLCSrr "ENM";
BA_ "SignalLongName" SG_ 1397 RFusTrkB5ObjSrcLCSrr "Rearward Fusion Track B5 Object Source LCSRR";
BA_ "VNSigAllNodes" SG_ 1397 RFusTrkB5ObjSrcLCSrr 1;
BA_ "SignalType" SG_ 1397 RFusTrkB5ObjSrcRCSrr "ENM";
BA_ "SignalLongName" SG_ 1397 RFusTrkB5ObjSrcRCSrr "Rearward Fusion Track B5 Object Source RCSRR";
BA_ "VNSigAllNodes" SG_ 1397 RFusTrkB5ObjSrcRCSrr 1;
BA_ "SignalType" SG_ 1397 RFusTrkB5ObjSrcRFSrr "ENM";
BA_ "SignalLongName" SG_ 1397 RFusTrkB5ObjSrcRFSrr "Rearward Fusion Track B5 Object Source RFSRR";
BA_ "VNSigAllNodes" SG_ 1397 RFusTrkB5ObjSrcRFSrr 1;
BA_ "SignalType" SG_ 1397 RFusTrkB5ObjSrcVIs "ENM";
BA_ "SignalLongName" SG_ 1397 RFusTrkB5ObjSrcVIs "Rearward Fusion Track B5 Object Source VIS";
BA_ "VNSigAllNodes" SG_ 1397 RFusTrkB5ObjSrcVIs 1;
BA_ "SignalType" SG_ 1397 RwdFusTrkB5ObjSrcLrr "ENM";
BA_ "SignalLongName" SG_ 1397 RwdFusTrkB5ObjSrcLrr "Rearward Fusion Track B5 Object Source LRR";
BA_ "VNSigAllNodes" SG_ 1397 RwdFusTrkB5ObjSrcLrr 1;
BA_ "SignalType" SG_ 1397 RwdFusTrkB5NmCycTrkd "UNM";
BA_ "SignalLongName" SG_ 1397 RwdFusTrkB5NmCycTrkd "Rearward Fusion Track B5 Number of Cycles Tracked";
BA_ "VNSigAllNodes" SG_ 1397 RwdFusTrkB5NmCycTrkd 1;
BA_ "SignalType" SG_ 1397 RwdFusTrkB5LatPosDev "UNM";
BA_ "SignalLongName" SG_ 1397 RwdFusTrkB5LatPosDev "Rearward Fusion Track B5 Lateral Position Deviation";
BA_ "VNSigAllNodes" SG_ 1397 RwdFusTrkB5LatPosDev 1;
BA_ "SignalType" SG_ 1397 RwdFusTrkB5LngPosDev "UNM";
BA_ "SignalLongName" SG_ 1397 RwdFusTrkB5LngPosDev "Rearward Fusion Track B5 Longitudinal Positioin Deviation";
BA_ "VNSigAllNodes" SG_ 1397 RwdFusTrkB5LngPosDev 1;
BA_ "SignalType" SG_ 1396 RwdFusTrkBAnlgRlLn4 "SNM";
BA_ "SignalLongName" SG_ 1396 RwdFusTrkBAnlgRlLn4 "Rwd Fusion Track B Analog relative Lane 4";
BA_ "VNSigAllNodes" SG_ 1396 RwdFusTrkBAnlgRlLn4 1;
BA_ "SignalType" SG_ 1396 RwdFusTrkB4RollingCnt "UNM";
BA_ "SignalLongName" SG_ 1396 RwdFusTrkB4RollingCnt "Rearward Fusion Track B4 Rolling Count";
BA_ "VNSigAllNodes" SG_ 1396 RwdFusTrkB4RollingCnt 1;
BA_ "SignalType" SG_ 1396 RwdFusTrkB4Width "UNM";
BA_ "SignalLongName" SG_ 1396 RwdFusTrkB4Width "Rearward Fusion Track B4 Width";
BA_ "GenSigStartValue" SG_ 1396 RwdFusTrkB4Width 1;
BA_ "VNSigAllNodes" SG_ 1396 RwdFusTrkB4Width 1;
BA_ "SignalType" SG_ 1396 RwdFusTrkB4MsgIndex "UNM";
BA_ "SignalLongName" SG_ 1396 RwdFusTrkB4MsgIndex "Rearward Fusion Track B4 Message Index";
BA_ "VNSigAllNodes" SG_ 1396 RwdFusTrkB4MsgIndex 1;
BA_ "SignalType" SG_ 1396 RwdFusTrkB4DynProp "ENM";
BA_ "SignalLongName" SG_ 1396 RwdFusTrkB4DynProp "Rearward Fusion Track B4 Dynamic Property";
BA_ "VNSigAllNodes" SG_ 1396 RwdFusTrkB4DynProp 1;
BA_ "SignalType" SG_ 1396 RwdFusTrkB4RelLnAccl "SNM";
BA_ "SignalLongName" SG_ 1396 RwdFusTrkB4RelLnAccl "Rearward Fusion Track B4 Relative Lane Acceleration";
BA_ "VNSigAllNodes" SG_ 1396 RwdFusTrkB4RelLnAccl 1;
BA_ "SignalType" SG_ 1396 RwdFusTrkB4RelLane "ENM";
BA_ "SignalLongName" SG_ 1396 RwdFusTrkB4RelLane "Rearward Fusion Track B4 Relative Lane";
BA_ "VNSigAllNodes" SG_ 1396 RwdFusTrkB4RelLane 1;
BA_ "SignalType" SG_ 1396 RwdFusTrkB4Height "UNM";
BA_ "SignalLongName" SG_ 1396 RwdFusTrkB4Height "Rearward Fusion Track B4 Height";
BA_ "GenSigStartValue" SG_ 1396 RwdFusTrkB4Height 1;
BA_ "VNSigAllNodes" SG_ 1396 RwdFusTrkB4Height 1;
BA_ "SignalType" SG_ 1396 RFusTrkB4ObjSrcLFSrr "ENM";
BA_ "SignalLongName" SG_ 1396 RFusTrkB4ObjSrcLFSrr "Rearward Fusion Track B4 Object Source LFSRR";
BA_ "VNSigAllNodes" SG_ 1396 RFusTrkB4ObjSrcLFSrr 1;
BA_ "SignalType" SG_ 1396 RFusTrkB4ObjSrcLCSrr "ENM";
BA_ "SignalLongName" SG_ 1396 RFusTrkB4ObjSrcLCSrr "Rearward Fusion Track B4 Object Source LCSRR";
BA_ "VNSigAllNodes" SG_ 1396 RFusTrkB4ObjSrcLCSrr 1;
BA_ "SignalType" SG_ 1396 RFusTrkB4ObjSrcRCSrr "ENM";
BA_ "SignalLongName" SG_ 1396 RFusTrkB4ObjSrcRCSrr "Rearward Fusion Track B4 Object Source RCSRR";
BA_ "VNSigAllNodes" SG_ 1396 RFusTrkB4ObjSrcRCSrr 1;
BA_ "SignalType" SG_ 1396 RFusTrkB4ObjSrcRFSrr "ENM";
BA_ "SignalLongName" SG_ 1396 RFusTrkB4ObjSrcRFSrr "Rearward Fusion Track B4 Object Source RFSRR";
BA_ "VNSigAllNodes" SG_ 1396 RFusTrkB4ObjSrcRFSrr 1;
BA_ "SignalType" SG_ 1396 RFusTrkB4ObjSrcVIs "ENM";
BA_ "SignalLongName" SG_ 1396 RFusTrkB4ObjSrcVIs "Rearward Fusion Track B4 Object Source VIS";
BA_ "VNSigAllNodes" SG_ 1396 RFusTrkB4ObjSrcVIs 1;
BA_ "SignalType" SG_ 1396 RwdFusTrkB4ObjSrcLrr "ENM";
BA_ "SignalLongName" SG_ 1396 RwdFusTrkB4ObjSrcLrr "Rearward Fusion Track B4 Object Source LRR";
BA_ "VNSigAllNodes" SG_ 1396 RwdFusTrkB4ObjSrcLrr 1;
BA_ "SignalType" SG_ 1396 RwdFusTrkB4NmCycTrkd "UNM";
BA_ "SignalLongName" SG_ 1396 RwdFusTrkB4NmCycTrkd "Rearward Fusion Track B4 Number of Cycles Tracked";
BA_ "VNSigAllNodes" SG_ 1396 RwdFusTrkB4NmCycTrkd 1;
BA_ "SignalType" SG_ 1396 RwdFusTrkB4LatPosDev "UNM";
BA_ "SignalLongName" SG_ 1396 RwdFusTrkB4LatPosDev "Rearward Fusion Track B4 Lateral Position Deviation";
BA_ "VNSigAllNodes" SG_ 1396 RwdFusTrkB4LatPosDev 1;
BA_ "SignalType" SG_ 1396 RwdFusTrkB4LngPosDev "UNM";
BA_ "SignalLongName" SG_ 1396 RwdFusTrkB4LngPosDev "Rearward Fusion Track B4 Longitudinal Positioin Deviation";
BA_ "VNSigAllNodes" SG_ 1396 RwdFusTrkB4LngPosDev 1;
BA_ "SignalType" SG_ 1395 RwdFusTrkBAnlgRlLn3 "SNM";
BA_ "SignalLongName" SG_ 1395 RwdFusTrkBAnlgRlLn3 "Rwd Fusion Track B Analog relative Lane 3";
BA_ "VNSigAllNodes" SG_ 1395 RwdFusTrkBAnlgRlLn3 1;
BA_ "SignalType" SG_ 1395 RwdFusTrkB3RollingCnt "UNM";
BA_ "SignalLongName" SG_ 1395 RwdFusTrkB3RollingCnt "Rearward Fusion Track B3 Rolling Count";
BA_ "VNSigAllNodes" SG_ 1395 RwdFusTrkB3RollingCnt 1;
BA_ "SignalType" SG_ 1395 RwdFusTrkB3Width "UNM";
BA_ "SignalLongName" SG_ 1395 RwdFusTrkB3Width "Rearward Fusion Track B3 Width";
BA_ "GenSigStartValue" SG_ 1395 RwdFusTrkB3Width 1;
BA_ "VNSigAllNodes" SG_ 1395 RwdFusTrkB3Width 1;
BA_ "SignalType" SG_ 1395 RwdFusTrkB3MsgIndex "UNM";
BA_ "SignalLongName" SG_ 1395 RwdFusTrkB3MsgIndex "Rearward Fusion Track B3 Message Index";
BA_ "VNSigAllNodes" SG_ 1395 RwdFusTrkB3MsgIndex 1;
BA_ "SignalType" SG_ 1395 RwdFusTrkB3DynProp "ENM";
BA_ "SignalLongName" SG_ 1395 RwdFusTrkB3DynProp "Rearward Fusion Track B3 Dynamic Property";
BA_ "VNSigAllNodes" SG_ 1395 RwdFusTrkB3DynProp 1;
BA_ "SignalType" SG_ 1395 RwdFusTrkB3RelLnAccl "SNM";
BA_ "SignalLongName" SG_ 1395 RwdFusTrkB3RelLnAccl "Rearward Fusion Track B3 Relative Lane Acceleration";
BA_ "VNSigAllNodes" SG_ 1395 RwdFusTrkB3RelLnAccl 1;
BA_ "SignalType" SG_ 1395 RwdFusTrkB3RelLane "ENM";
BA_ "SignalLongName" SG_ 1395 RwdFusTrkB3RelLane "Rearward Fusion Track B3 Relative Lane";
BA_ "VNSigAllNodes" SG_ 1395 RwdFusTrkB3RelLane 1;
BA_ "SignalType" SG_ 1395 RwdFusTrkB3Height "UNM";
BA_ "SignalLongName" SG_ 1395 RwdFusTrkB3Height "Rearward Fusion Track B3 Height";
BA_ "GenSigStartValue" SG_ 1395 RwdFusTrkB3Height 1;
BA_ "VNSigAllNodes" SG_ 1395 RwdFusTrkB3Height 1;
BA_ "SignalType" SG_ 1395 RFusTrkB3ObjSrcLFSrr "ENM";
BA_ "SignalLongName" SG_ 1395 RFusTrkB3ObjSrcLFSrr "Rearward Fusion Track B3 Object Source LFSRR";
BA_ "VNSigAllNodes" SG_ 1395 RFusTrkB3ObjSrcLFSrr 1;
BA_ "SignalType" SG_ 1395 RFusTrkB3ObjSrcLCSrr "ENM";
BA_ "SignalLongName" SG_ 1395 RFusTrkB3ObjSrcLCSrr "Rearward Fusion Track B3 Object Source LCSRR";
BA_ "VNSigAllNodes" SG_ 1395 RFusTrkB3ObjSrcLCSrr 1;
BA_ "SignalType" SG_ 1395 RFusTrkB3ObjSrcRCSrr "ENM";
BA_ "SignalLongName" SG_ 1395 RFusTrkB3ObjSrcRCSrr "Rearward Fusion Track B3 Object Source RCSRR";
BA_ "VNSigAllNodes" SG_ 1395 RFusTrkB3ObjSrcRCSrr 1;
BA_ "SignalType" SG_ 1395 RFusTrkB3ObjSrcRFSrr "ENM";
BA_ "SignalLongName" SG_ 1395 RFusTrkB3ObjSrcRFSrr "Rearward Fusion Track B3 Object Source RFSRR";
BA_ "VNSigAllNodes" SG_ 1395 RFusTrkB3ObjSrcRFSrr 1;
BA_ "SignalType" SG_ 1395 RFusTrkB3ObjSrcVIs "ENM";
BA_ "SignalLongName" SG_ 1395 RFusTrkB3ObjSrcVIs "Rearward Fusion Track B3 Object Source VIS";
BA_ "VNSigAllNodes" SG_ 1395 RFusTrkB3ObjSrcVIs 1;
BA_ "SignalType" SG_ 1395 RwdFusTrkB3ObjSrcLrr "ENM";
BA_ "SignalLongName" SG_ 1395 RwdFusTrkB3ObjSrcLrr "Rearward Fusion Track B3 Object Source LRR";
BA_ "VNSigAllNodes" SG_ 1395 RwdFusTrkB3ObjSrcLrr 1;
BA_ "SignalType" SG_ 1395 RwdFusTrkB3NmCycTrkd "UNM";
BA_ "SignalLongName" SG_ 1395 RwdFusTrkB3NmCycTrkd "Rearward Fusion Track B3 Number of Cycles Tracked";
BA_ "VNSigAllNodes" SG_ 1395 RwdFusTrkB3NmCycTrkd 1;
BA_ "SignalType" SG_ 1395 RwdFusTrkB3LatPosDev "UNM";
BA_ "SignalLongName" SG_ 1395 RwdFusTrkB3LatPosDev "Rearward Fusion Track B3 Lateral Position Deviation";
BA_ "VNSigAllNodes" SG_ 1395 RwdFusTrkB3LatPosDev 1;
BA_ "SignalType" SG_ 1395 RwdFusTrkB3LngPosDev "UNM";
BA_ "SignalLongName" SG_ 1395 RwdFusTrkB3LngPosDev "Rearward Fusion Track B3 Longitudinal Positioin Deviation";
BA_ "VNSigAllNodes" SG_ 1395 RwdFusTrkB3LngPosDev 1;
BA_ "SignalType" SG_ 1394 RwdFusTrkBAnlgRlLn2 "SNM";
BA_ "SignalLongName" SG_ 1394 RwdFusTrkBAnlgRlLn2 "Rwd Fusion Track B Analog relative Lane 2";
BA_ "VNSigAllNodes" SG_ 1394 RwdFusTrkBAnlgRlLn2 1;
BA_ "SignalType" SG_ 1394 RwdFusTrkB2RollingCnt "UNM";
BA_ "SignalLongName" SG_ 1394 RwdFusTrkB2RollingCnt "Rearward Fusion Track B2 Rolling Count";
BA_ "VNSigAllNodes" SG_ 1394 RwdFusTrkB2RollingCnt 1;
BA_ "SignalType" SG_ 1394 RwdFusTrkB2Width "UNM";
BA_ "SignalLongName" SG_ 1394 RwdFusTrkB2Width "Rearward Fusion Track B2 Width";
BA_ "GenSigStartValue" SG_ 1394 RwdFusTrkB2Width 1;
BA_ "VNSigAllNodes" SG_ 1394 RwdFusTrkB2Width 1;
BA_ "SignalType" SG_ 1394 RwdFusTrkB2MsgIndex "UNM";
BA_ "SignalLongName" SG_ 1394 RwdFusTrkB2MsgIndex "Rearward Fusion Track B2 Message Index";
BA_ "VNSigAllNodes" SG_ 1394 RwdFusTrkB2MsgIndex 1;
BA_ "SignalType" SG_ 1394 RwdFusTrkB2DynProp "ENM";
BA_ "SignalLongName" SG_ 1394 RwdFusTrkB2DynProp "Rearward Fusion Track B2 Dynamic Property";
BA_ "VNSigAllNodes" SG_ 1394 RwdFusTrkB2DynProp 1;
BA_ "SignalType" SG_ 1394 RwdFusTrkB2RelLnAccl "SNM";
BA_ "SignalLongName" SG_ 1394 RwdFusTrkB2RelLnAccl "Rearward Fusion Track B2 Relative Lane Acceleration";
BA_ "VNSigAllNodes" SG_ 1394 RwdFusTrkB2RelLnAccl 1;
BA_ "SignalType" SG_ 1394 RwdFusTrkB2RelLane "ENM";
BA_ "SignalLongName" SG_ 1394 RwdFusTrkB2RelLane "Rearward Fusion Track B2 Relative Lane";
BA_ "VNSigAllNodes" SG_ 1394 RwdFusTrkB2RelLane 1;
BA_ "SignalType" SG_ 1394 RwdFusTrkB2Height "UNM";
BA_ "SignalLongName" SG_ 1394 RwdFusTrkB2Height "Rearward Fusion Track B2 Height";
BA_ "GenSigStartValue" SG_ 1394 RwdFusTrkB2Height 1;
BA_ "VNSigAllNodes" SG_ 1394 RwdFusTrkB2Height 1;
BA_ "SignalType" SG_ 1394 RFusTrkB2ObjSrcLFSrr "ENM";
BA_ "SignalLongName" SG_ 1394 RFusTrkB2ObjSrcLFSrr "Rearward Fusion Track B2 Object Source LFSRR";
BA_ "VNSigAllNodes" SG_ 1394 RFusTrkB2ObjSrcLFSrr 1;
BA_ "SignalType" SG_ 1394 RFusTrkB2ObjSrcLCSrr "ENM";
BA_ "SignalLongName" SG_ 1394 RFusTrkB2ObjSrcLCSrr "Rearward Fusion Track B2 Object Source LCSRR";
BA_ "VNSigAllNodes" SG_ 1394 RFusTrkB2ObjSrcLCSrr 1;
BA_ "SignalType" SG_ 1394 RFusTrkB2ObjSrcRCSrr "ENM";
BA_ "SignalLongName" SG_ 1394 RFusTrkB2ObjSrcRCSrr "Rearward Fusion Track B2 Object Source RCSRR";
BA_ "VNSigAllNodes" SG_ 1394 RFusTrkB2ObjSrcRCSrr 1;
BA_ "SignalType" SG_ 1394 RFusTrkB2ObjSrcRFSrr "ENM";
BA_ "SignalLongName" SG_ 1394 RFusTrkB2ObjSrcRFSrr "Rearward Fusion Track B2 Object Source RFSRR";
BA_ "VNSigAllNodes" SG_ 1394 RFusTrkB2ObjSrcRFSrr 1;
BA_ "SignalType" SG_ 1394 RFusTrkB2ObjSrcVIs "ENM";
BA_ "SignalLongName" SG_ 1394 RFusTrkB2ObjSrcVIs "Rearward Fusion Track B2 Object Source VIS";
BA_ "VNSigAllNodes" SG_ 1394 RFusTrkB2ObjSrcVIs 1;
BA_ "SignalType" SG_ 1394 RwdFusTrkB2ObjSrcLrr "ENM";
BA_ "SignalLongName" SG_ 1394 RwdFusTrkB2ObjSrcLrr "Rearward Fusion Track B2 Object Source LRR";
BA_ "VNSigAllNodes" SG_ 1394 RwdFusTrkB2ObjSrcLrr 1;
BA_ "SignalType" SG_ 1394 RwdFusTrkB2NmCycTrkd "UNM";
BA_ "SignalLongName" SG_ 1394 RwdFusTrkB2NmCycTrkd "Rearward Fusion Track B2 Number of Cycles Tracked";
BA_ "VNSigAllNodes" SG_ 1394 RwdFusTrkB2NmCycTrkd 1;
BA_ "SignalType" SG_ 1394 RwdFusTrkB2LatPosDev "UNM";
BA_ "SignalLongName" SG_ 1394 RwdFusTrkB2LatPosDev "Rearward Fusion Track B2 Lateral Position Deviation";
BA_ "VNSigAllNodes" SG_ 1394 RwdFusTrkB2LatPosDev 1;
BA_ "SignalType" SG_ 1394 RwdFusTrkB2LngPosDev "UNM";
BA_ "SignalLongName" SG_ 1394 RwdFusTrkB2LngPosDev "Rearward Fusion Track B2 Longitudinal Positioin Deviation";
BA_ "VNSigAllNodes" SG_ 1394 RwdFusTrkB2LngPosDev 1;
BA_ "SignalType" SG_ 1407 RwdFusTrkBAnlgRlLn15 "SNM";
BA_ "SignalLongName" SG_ 1407 RwdFusTrkBAnlgRlLn15 "Rwd Fusion Track B Analog relative Lane 15";
BA_ "VNSigAllNodes" SG_ 1407 RwdFusTrkBAnlgRlLn15 1;
BA_ "SignalType" SG_ 1407 RwdFusTrkB15RollingCnt "UNM";
BA_ "SignalLongName" SG_ 1407 RwdFusTrkB15RollingCnt "Rearward Fusion Track B15 Rolling Count";
BA_ "VNSigAllNodes" SG_ 1407 RwdFusTrkB15RollingCnt 1;
BA_ "SignalType" SG_ 1407 RwdFusTrkB15Width "UNM";
BA_ "SignalLongName" SG_ 1407 RwdFusTrkB15Width "Rearward Fusion Track B15 Width";
BA_ "GenSigStartValue" SG_ 1407 RwdFusTrkB15Width 1;
BA_ "VNSigAllNodes" SG_ 1407 RwdFusTrkB15Width 1;
BA_ "SignalType" SG_ 1407 RwdFusTrkB15MsgIndex "UNM";
BA_ "SignalLongName" SG_ 1407 RwdFusTrkB15MsgIndex "Rearward Fusion Track B15 Message Index";
BA_ "VNSigAllNodes" SG_ 1407 RwdFusTrkB15MsgIndex 1;
BA_ "SignalType" SG_ 1407 RwdFusTrkB15DynProp "ENM";
BA_ "SignalLongName" SG_ 1407 RwdFusTrkB15DynProp "Rearward Fusion Track B15 Dynamic Property";
BA_ "VNSigAllNodes" SG_ 1407 RwdFusTrkB15DynProp 1;
BA_ "SignalType" SG_ 1407 RwdFusTrkB15RelLnAccl "SNM";
BA_ "SignalLongName" SG_ 1407 RwdFusTrkB15RelLnAccl "Rearward Fusion Track B15 Relative Lane Acceleration";
BA_ "VNSigAllNodes" SG_ 1407 RwdFusTrkB15RelLnAccl 1;
BA_ "SignalType" SG_ 1407 RwdFusTrkB15RelLane "ENM";
BA_ "SignalLongName" SG_ 1407 RwdFusTrkB15RelLane "Rearward Fusion Track B15 Relative Lane";
BA_ "VNSigAllNodes" SG_ 1407 RwdFusTrkB15RelLane 1;
BA_ "SignalType" SG_ 1407 RwdFusTrkB15Height "UNM";
BA_ "SignalLongName" SG_ 1407 RwdFusTrkB15Height "Rearward Fusion Track B15 Height";
BA_ "GenSigStartValue" SG_ 1407 RwdFusTrkB15Height 1;
BA_ "VNSigAllNodes" SG_ 1407 RwdFusTrkB15Height 1;
BA_ "SignalType" SG_ 1407 RFusTrkB15ObjSrcLFSrr "ENM";
BA_ "SignalLongName" SG_ 1407 RFusTrkB15ObjSrcLFSrr "Rearward Fusion Track B15 Object Source LFSRR";
BA_ "VNSigAllNodes" SG_ 1407 RFusTrkB15ObjSrcLFSrr 1;
BA_ "SignalType" SG_ 1407 RFusTrkB15ObjSrcLCSrr "ENM";
BA_ "SignalLongName" SG_ 1407 RFusTrkB15ObjSrcLCSrr "Rearward Fusion Track B15 Object Source LCSRR";
BA_ "VNSigAllNodes" SG_ 1407 RFusTrkB15ObjSrcLCSrr 1;
BA_ "SignalType" SG_ 1407 RFusTrkB15ObjSrcRCSrr "ENM";
BA_ "SignalLongName" SG_ 1407 RFusTrkB15ObjSrcRCSrr "Rearward Fusion Track B15 Object Source RCSRR";
BA_ "VNSigAllNodes" SG_ 1407 RFusTrkB15ObjSrcRCSrr 1;
BA_ "SignalType" SG_ 1407 RFusTrkB15ObjSrcRFSrr "ENM";
BA_ "SignalLongName" SG_ 1407 RFusTrkB15ObjSrcRFSrr "Rearward Fusion Track B15 Object Source RFSRR";
BA_ "VNSigAllNodes" SG_ 1407 RFusTrkB15ObjSrcRFSrr 1;
BA_ "SignalType" SG_ 1407 RFusTkB15ObjSrcVIs "ENM";
BA_ "SignalLongName" SG_ 1407 RFusTkB15ObjSrcVIs "Rearward Fusion Track B15 Object Source VIS";
BA_ "VNSigAllNodes" SG_ 1407 RFusTkB15ObjSrcVIs 1;
BA_ "SignalType" SG_ 1407 RwdFusTrkB15ObjSrcLrr "ENM";
BA_ "SignalLongName" SG_ 1407 RwdFusTrkB15ObjSrcLrr "Rearward Fusion Track B15 Object Source LRR";
BA_ "VNSigAllNodes" SG_ 1407 RwdFusTrkB15ObjSrcLrr 1;
BA_ "SignalType" SG_ 1407 RwdFusTrkB15NmCycTrkd "UNM";
BA_ "SignalLongName" SG_ 1407 RwdFusTrkB15NmCycTrkd "Rearward Fusion Track B15 Number of Cycles Tracked";
BA_ "VNSigAllNodes" SG_ 1407 RwdFusTrkB15NmCycTrkd 1;
BA_ "SignalType" SG_ 1407 RwdFusTrkB15LatPosDev "UNM";
BA_ "SignalLongName" SG_ 1407 RwdFusTrkB15LatPosDev "Rearward Fusion Track B15 Lateral Position Deviation";
BA_ "VNSigAllNodes" SG_ 1407 RwdFusTrkB15LatPosDev 1;
BA_ "SignalType" SG_ 1407 RwdFusTrkB15LngPosDev "UNM";
BA_ "SignalLongName" SG_ 1407 RwdFusTrkB15LngPosDev "Rearward Fusion Track B15 Longitudinal Positioin Deviation";
BA_ "VNSigAllNodes" SG_ 1407 RwdFusTrkB15LngPosDev 1;
BA_ "SignalType" SG_ 1406 RwdFusTrkBAnlgRlLn14 "SNM";
BA_ "SignalLongName" SG_ 1406 RwdFusTrkBAnlgRlLn14 "Rwd Fusion Track B Analog relative Lane 14";
BA_ "VNSigAllNodes" SG_ 1406 RwdFusTrkBAnlgRlLn14 1;
BA_ "SignalType" SG_ 1406 RwdFusTrkB14RollingCnt "UNM";
BA_ "SignalLongName" SG_ 1406 RwdFusTrkB14RollingCnt "Rearward Fusion Track B14 Rolling Count";
BA_ "VNSigAllNodes" SG_ 1406 RwdFusTrkB14RollingCnt 1;
BA_ "SignalType" SG_ 1406 RwdFusTrkB14Width "UNM";
BA_ "SignalLongName" SG_ 1406 RwdFusTrkB14Width "Rearward Fusion Track B14 Width";
BA_ "GenSigStartValue" SG_ 1406 RwdFusTrkB14Width 1;
BA_ "VNSigAllNodes" SG_ 1406 RwdFusTrkB14Width 1;
BA_ "SignalType" SG_ 1406 RwdFusTrkB14MsgIndex "UNM";
BA_ "SignalLongName" SG_ 1406 RwdFusTrkB14MsgIndex "Rearward Fusion Track B14 Message Index";
BA_ "VNSigAllNodes" SG_ 1406 RwdFusTrkB14MsgIndex 1;
BA_ "SignalType" SG_ 1406 RwdFusTrkB14DynProp "ENM";
BA_ "SignalLongName" SG_ 1406 RwdFusTrkB14DynProp "Rearward Fusion Track B14 Dynamic Property";
BA_ "VNSigAllNodes" SG_ 1406 RwdFusTrkB14DynProp 1;
BA_ "SignalType" SG_ 1406 RwdFusTrkB14RelLnAccl "SNM";
BA_ "SignalLongName" SG_ 1406 RwdFusTrkB14RelLnAccl "Rearward Fusion Track B14 Relative Lane Acceleration";
BA_ "VNSigAllNodes" SG_ 1406 RwdFusTrkB14RelLnAccl 1;
BA_ "SignalType" SG_ 1406 RwdFusTrkB14RelLane "ENM";
BA_ "SignalLongName" SG_ 1406 RwdFusTrkB14RelLane "Rearward Fusion Track B14 Relative Lane";
BA_ "VNSigAllNodes" SG_ 1406 RwdFusTrkB14RelLane 1;
BA_ "SignalType" SG_ 1406 RwdFusTrkB14Height "UNM";
BA_ "SignalLongName" SG_ 1406 RwdFusTrkB14Height "Rearward Fusion Track B14 Height";
BA_ "GenSigStartValue" SG_ 1406 RwdFusTrkB14Height 1;
BA_ "VNSigAllNodes" SG_ 1406 RwdFusTrkB14Height 1;
BA_ "SignalType" SG_ 1406 RFusTrkB14ObjSrcLFSrr "ENM";
BA_ "SignalLongName" SG_ 1406 RFusTrkB14ObjSrcLFSrr "Rearward Fusion Track B14 Object Source LFSRR";
BA_ "VNSigAllNodes" SG_ 1406 RFusTrkB14ObjSrcLFSrr 1;
BA_ "SignalType" SG_ 1406 RFusTrkB14ObjSrcLCSrr "ENM";
BA_ "SignalLongName" SG_ 1406 RFusTrkB14ObjSrcLCSrr "Rearward Fusion Track B14 Object Source LCSRR";
BA_ "VNSigAllNodes" SG_ 1406 RFusTrkB14ObjSrcLCSrr 1;
BA_ "SignalType" SG_ 1406 RFusTrkB14ObjSrcRCSrr "ENM";
BA_ "SignalLongName" SG_ 1406 RFusTrkB14ObjSrcRCSrr "Rearward Fusion Track B14 Object Source RCSRR";
BA_ "VNSigAllNodes" SG_ 1406 RFusTrkB14ObjSrcRCSrr 1;
BA_ "SignalType" SG_ 1406 RFusTrkB14ObjSrcRFSrr "ENM";
BA_ "SignalLongName" SG_ 1406 RFusTrkB14ObjSrcRFSrr "Rearward Fusion Track B14 Object Source RFSRR";
BA_ "VNSigAllNodes" SG_ 1406 RFusTrkB14ObjSrcRFSrr 1;
BA_ "SignalType" SG_ 1406 RFusTrkB14ObjSrcVIs "ENM";
BA_ "SignalLongName" SG_ 1406 RFusTrkB14ObjSrcVIs "Rearward Fusion Track B14 Object Source VIS";
BA_ "VNSigAllNodes" SG_ 1406 RFusTrkB14ObjSrcVIs 1;
BA_ "SignalType" SG_ 1406 RwdFusTrkB14ObjSrcLrr "ENM";
BA_ "SignalLongName" SG_ 1406 RwdFusTrkB14ObjSrcLrr "Rearward Fusion Track B14 Object Source LRR";
BA_ "VNSigAllNodes" SG_ 1406 RwdFusTrkB14ObjSrcLrr 1;
BA_ "SignalType" SG_ 1406 RwdFusTrkB14NmCycTrkd "UNM";
BA_ "SignalLongName" SG_ 1406 RwdFusTrkB14NmCycTrkd "Rearward Fusion Track B14 Number of Cycles Tracked";
BA_ "VNSigAllNodes" SG_ 1406 RwdFusTrkB14NmCycTrkd 1;
BA_ "SignalType" SG_ 1406 RwdFusTrkB14LatPosDev "UNM";
BA_ "SignalLongName" SG_ 1406 RwdFusTrkB14LatPosDev "Rearward Fusion Track B14 Lateral Position Deviation";
BA_ "VNSigAllNodes" SG_ 1406 RwdFusTrkB14LatPosDev 1;
BA_ "SignalType" SG_ 1406 RwdFusTrkB14LngPosDev "UNM";
BA_ "SignalLongName" SG_ 1406 RwdFusTrkB14LngPosDev "Rearward Fusion Track B14 Longitudinal Positioin Deviation";
BA_ "VNSigAllNodes" SG_ 1406 RwdFusTrkB14LngPosDev 1;
BA_ "SignalType" SG_ 1405 RwdFusTrkBAnlgRlLn13 "SNM";
BA_ "SignalLongName" SG_ 1405 RwdFusTrkBAnlgRlLn13 "Rwd Fusion Track B Analog relative Lane 13";
BA_ "VNSigAllNodes" SG_ 1405 RwdFusTrkBAnlgRlLn13 1;
BA_ "SignalType" SG_ 1405 RwdFusTrkB13RollingCnt "UNM";
BA_ "SignalLongName" SG_ 1405 RwdFusTrkB13RollingCnt "Rearward Fusion Track B13 Rolling Count";
BA_ "VNSigAllNodes" SG_ 1405 RwdFusTrkB13RollingCnt 1;
BA_ "SignalType" SG_ 1405 RwdFusTrkB13Width "UNM";
BA_ "SignalLongName" SG_ 1405 RwdFusTrkB13Width "Rearward Fusion Track B13 Width";
BA_ "GenSigStartValue" SG_ 1405 RwdFusTrkB13Width 1;
BA_ "VNSigAllNodes" SG_ 1405 RwdFusTrkB13Width 1;
BA_ "SignalType" SG_ 1405 RwdFusTrkB13MsgIndex "UNM";
BA_ "SignalLongName" SG_ 1405 RwdFusTrkB13MsgIndex "Rearward Fusion Track B13 Message Index";
BA_ "VNSigAllNodes" SG_ 1405 RwdFusTrkB13MsgIndex 1;
BA_ "SignalType" SG_ 1405 RwdFusTrkB13DynProp "ENM";
BA_ "SignalLongName" SG_ 1405 RwdFusTrkB13DynProp "Rearward Fusion Track B13 Dynamic Property";
BA_ "VNSigAllNodes" SG_ 1405 RwdFusTrkB13DynProp 1;
BA_ "SignalType" SG_ 1405 RwdFusTrkB13RelLnAccl "SNM";
BA_ "SignalLongName" SG_ 1405 RwdFusTrkB13RelLnAccl "Rearward Fusion Track B13 Relative Lane Acceleration";
BA_ "VNSigAllNodes" SG_ 1405 RwdFusTrkB13RelLnAccl 1;
BA_ "SignalType" SG_ 1405 RwdFusTrkB13RelLane "ENM";
BA_ "SignalLongName" SG_ 1405 RwdFusTrkB13RelLane "Rearward Fusion Track B13 Relative Lane";
BA_ "VNSigAllNodes" SG_ 1405 RwdFusTrkB13RelLane 1;
BA_ "SignalType" SG_ 1405 RwdFusTrkB13Height "UNM";
BA_ "SignalLongName" SG_ 1405 RwdFusTrkB13Height "Rearward Fusion Track B13 Height";
BA_ "GenSigStartValue" SG_ 1405 RwdFusTrkB13Height 1;
BA_ "VNSigAllNodes" SG_ 1405 RwdFusTrkB13Height 1;
BA_ "SignalType" SG_ 1405 RFusTrkB13ObjSrcLFSrr "ENM";
BA_ "SignalLongName" SG_ 1405 RFusTrkB13ObjSrcLFSrr "Rearward Fusion Track B13 Object Source LFSRR";
BA_ "VNSigAllNodes" SG_ 1405 RFusTrkB13ObjSrcLFSrr 1;
BA_ "SignalType" SG_ 1405 RFusTrkB13ObjSrcLCSrr "ENM";
BA_ "SignalLongName" SG_ 1405 RFusTrkB13ObjSrcLCSrr "Rearward Fusion Track B13 Object Source LCSRR";
BA_ "VNSigAllNodes" SG_ 1405 RFusTrkB13ObjSrcLCSrr 1;
BA_ "SignalType" SG_ 1405 RFusTrkB13ObjSrcRCSrr "ENM";
BA_ "SignalLongName" SG_ 1405 RFusTrkB13ObjSrcRCSrr "Rearward Fusion Track B13 Object Source RCSRR";
BA_ "VNSigAllNodes" SG_ 1405 RFusTrkB13ObjSrcRCSrr 1;
BA_ "SignalType" SG_ 1405 RFusTrkB13ObjSrcRFSrr "ENM";
BA_ "SignalLongName" SG_ 1405 RFusTrkB13ObjSrcRFSrr "Rearward Fusion Track B13 Object Source RFSRR";
BA_ "VNSigAllNodes" SG_ 1405 RFusTrkB13ObjSrcRFSrr 1;
BA_ "SignalType" SG_ 1405 RFusTrkB13ObjSrcVIs "ENM";
BA_ "SignalLongName" SG_ 1405 RFusTrkB13ObjSrcVIs "Rearward Fusion Track B13 Object Source VIS";
BA_ "VNSigAllNodes" SG_ 1405 RFusTrkB13ObjSrcVIs 1;
BA_ "SignalType" SG_ 1405 RwdFusTrkB13ObjSrcLrr "ENM";
BA_ "SignalLongName" SG_ 1405 RwdFusTrkB13ObjSrcLrr "Rearward Fusion Track B13 Object Source LRR";
BA_ "VNSigAllNodes" SG_ 1405 RwdFusTrkB13ObjSrcLrr 1;
BA_ "SignalType" SG_ 1405 RwdFusTrkB13NmCycTrkd "UNM";
BA_ "SignalLongName" SG_ 1405 RwdFusTrkB13NmCycTrkd "Rearward Fusion Track B13 Number of Cycles Tracked";
BA_ "VNSigAllNodes" SG_ 1405 RwdFusTrkB13NmCycTrkd 1;
BA_ "SignalType" SG_ 1405 RwdFusTrkB13LatPosDev "UNM";
BA_ "SignalLongName" SG_ 1405 RwdFusTrkB13LatPosDev "Rearward Fusion Track B13 Lateral Position Deviation";
BA_ "VNSigAllNodes" SG_ 1405 RwdFusTrkB13LatPosDev 1;
BA_ "SignalType" SG_ 1405 RwdFusTrkB13LngPosDev "UNM";
BA_ "SignalLongName" SG_ 1405 RwdFusTrkB13LngPosDev "Rearward Fusion Track B13 Longitudinal Positioin Deviation";
BA_ "VNSigAllNodes" SG_ 1405 RwdFusTrkB13LngPosDev 1;
BA_ "SignalType" SG_ 1404 RwdFusTrkBAnlgRlLn12 "SNM";
BA_ "SignalLongName" SG_ 1404 RwdFusTrkBAnlgRlLn12 "Rwd Fusion Track B Analog relative Lane 12";
BA_ "VNSigAllNodes" SG_ 1404 RwdFusTrkBAnlgRlLn12 1;
BA_ "SignalType" SG_ 1404 RwdFusTrkB12RollingCnt "UNM";
BA_ "SignalLongName" SG_ 1404 RwdFusTrkB12RollingCnt "Rearward Fusion Track B12 Rolling Count";
BA_ "VNSigAllNodes" SG_ 1404 RwdFusTrkB12RollingCnt 1;
BA_ "SignalType" SG_ 1404 RwdFusTrkB12Width "UNM";
BA_ "SignalLongName" SG_ 1404 RwdFusTrkB12Width "Rearward Fusion Track B12 Width";
BA_ "GenSigStartValue" SG_ 1404 RwdFusTrkB12Width 1;
BA_ "VNSigAllNodes" SG_ 1404 RwdFusTrkB12Width 1;
BA_ "SignalType" SG_ 1404 RwdFusTrkB12MsgIndex "UNM";
BA_ "SignalLongName" SG_ 1404 RwdFusTrkB12MsgIndex "Rearward Fusion Track B12 Message Index";
BA_ "VNSigAllNodes" SG_ 1404 RwdFusTrkB12MsgIndex 1;
BA_ "SignalType" SG_ 1404 RwdFusTrkB12DynProp "ENM";
BA_ "SignalLongName" SG_ 1404 RwdFusTrkB12DynProp "Rearward Fusion Track B12 Dynamic Property";
BA_ "VNSigAllNodes" SG_ 1404 RwdFusTrkB12DynProp 1;
BA_ "SignalType" SG_ 1404 RwdFusTrkB12RelLnAccl "SNM";
BA_ "SignalLongName" SG_ 1404 RwdFusTrkB12RelLnAccl "Rearward Fusion Track B12 Relative Lane Acceleration";
BA_ "VNSigAllNodes" SG_ 1404 RwdFusTrkB12RelLnAccl 1;
BA_ "SignalType" SG_ 1404 RwdFusTrkB12RelLane "ENM";
BA_ "SignalLongName" SG_ 1404 RwdFusTrkB12RelLane "Rearward Fusion Track B12 Relative Lane";
BA_ "VNSigAllNodes" SG_ 1404 RwdFusTrkB12RelLane 1;
BA_ "SignalType" SG_ 1404 RwdFusTrkB12Height "UNM";
BA_ "SignalLongName" SG_ 1404 RwdFusTrkB12Height "Rearward Fusion Track B12 Height";
BA_ "GenSigStartValue" SG_ 1404 RwdFusTrkB12Height 1;
BA_ "VNSigAllNodes" SG_ 1404 RwdFusTrkB12Height 1;
BA_ "SignalType" SG_ 1404 RFusTrkB12ObjSrcLFSrr "ENM";
BA_ "SignalLongName" SG_ 1404 RFusTrkB12ObjSrcLFSrr "Rearward Fusion Track B12 Object Source LFSRR";
BA_ "VNSigAllNodes" SG_ 1404 RFusTrkB12ObjSrcLFSrr 1;
BA_ "SignalType" SG_ 1404 RFusTrkB12ObjSrcLCSrr "ENM";
BA_ "SignalLongName" SG_ 1404 RFusTrkB12ObjSrcLCSrr "Rearward Fusion Track B12 Object Source LCSRR";
BA_ "VNSigAllNodes" SG_ 1404 RFusTrkB12ObjSrcLCSrr 1;
BA_ "SignalType" SG_ 1404 RFusTrkB12ObjSrcRCSrr "ENM";
BA_ "SignalLongName" SG_ 1404 RFusTrkB12ObjSrcRCSrr "Rearward Fusion Track B12 Object Source RCSRR";
BA_ "VNSigAllNodes" SG_ 1404 RFusTrkB12ObjSrcRCSrr 1;
BA_ "SignalType" SG_ 1404 RFusTrkB12ObjSrcRFSrr "ENM";
BA_ "SignalLongName" SG_ 1404 RFusTrkB12ObjSrcRFSrr "Rearward Fusion Track B12 Object Source RFSRR";
BA_ "VNSigAllNodes" SG_ 1404 RFusTrkB12ObjSrcRFSrr 1;
BA_ "SignalType" SG_ 1404 RFusTrkB12ObjSrcVIs "ENM";
BA_ "SignalLongName" SG_ 1404 RFusTrkB12ObjSrcVIs "Rearward Fusion Track B12 Object Source VIS";
BA_ "VNSigAllNodes" SG_ 1404 RFusTrkB12ObjSrcVIs 1;
BA_ "SignalType" SG_ 1404 RwdFusTrkB12ObjSrcLrr "ENM";
BA_ "SignalLongName" SG_ 1404 RwdFusTrkB12ObjSrcLrr "Rearward Fusion Track B12 Object Source LRR";
BA_ "VNSigAllNodes" SG_ 1404 RwdFusTrkB12ObjSrcLrr 1;
BA_ "SignalType" SG_ 1404 RwdFusTrkB12NmCycTrkd "UNM";
BA_ "SignalLongName" SG_ 1404 RwdFusTrkB12NmCycTrkd "Rearward Fusion Track B12 Number of Cycles Tracked";
BA_ "VNSigAllNodes" SG_ 1404 RwdFusTrkB12NmCycTrkd 1;
BA_ "SignalType" SG_ 1404 RwdFusTrkB12LatPosDev "UNM";
BA_ "SignalLongName" SG_ 1404 RwdFusTrkB12LatPosDev "Rearward Fusion Track B12 Lateral Position Deviation";
BA_ "VNSigAllNodes" SG_ 1404 RwdFusTrkB12LatPosDev 1;
BA_ "SignalType" SG_ 1404 RwdFusTrkB12LngPosDev "UNM";
BA_ "SignalLongName" SG_ 1404 RwdFusTrkB12LngPosDev "Rearward Fusion Track B12 Longitudinal Positioin Deviation";
BA_ "VNSigAllNodes" SG_ 1404 RwdFusTrkB12LngPosDev 1;
BA_ "SignalType" SG_ 1403 RwdFusTrkBAnlgRlLn11 "SNM";
BA_ "SignalLongName" SG_ 1403 RwdFusTrkBAnlgRlLn11 "Rwd Fusion Track B Analog relative Lane 11";
BA_ "VNSigAllNodes" SG_ 1403 RwdFusTrkBAnlgRlLn11 1;
BA_ "SignalType" SG_ 1403 RwdFusTrkB11RollingCnt "UNM";
BA_ "SignalLongName" SG_ 1403 RwdFusTrkB11RollingCnt "Rearward Fusion Track B11 Rolling Count";
BA_ "VNSigAllNodes" SG_ 1403 RwdFusTrkB11RollingCnt 1;
BA_ "SignalType" SG_ 1403 RwdFusTrkB11Width "UNM";
BA_ "SignalLongName" SG_ 1403 RwdFusTrkB11Width "Rearward Fusion Track B11 Width";
BA_ "GenSigStartValue" SG_ 1403 RwdFusTrkB11Width 1;
BA_ "VNSigAllNodes" SG_ 1403 RwdFusTrkB11Width 1;
BA_ "SignalType" SG_ 1403 RwdFusTrkB11MsgIndex "UNM";
BA_ "SignalLongName" SG_ 1403 RwdFusTrkB11MsgIndex "Rearward Fusion Track B11 Message Index";
BA_ "VNSigAllNodes" SG_ 1403 RwdFusTrkB11MsgIndex 1;
BA_ "SignalType" SG_ 1403 RwdFusTrkB11DynProp "ENM";
BA_ "SignalLongName" SG_ 1403 RwdFusTrkB11DynProp "Rearward Fusion Track B11 Dynamic Property";
BA_ "VNSigAllNodes" SG_ 1403 RwdFusTrkB11DynProp 1;
BA_ "SignalType" SG_ 1403 RwdFusTrkB11RelLnAccl "SNM";
BA_ "SignalLongName" SG_ 1403 RwdFusTrkB11RelLnAccl "Rearward Fusion Track B11 Relative Lane Acceleration";
BA_ "VNSigAllNodes" SG_ 1403 RwdFusTrkB11RelLnAccl 1;
BA_ "SignalType" SG_ 1403 RwdFusTrkB11RelLane "ENM";
BA_ "SignalLongName" SG_ 1403 RwdFusTrkB11RelLane "Rearward Fusion Track B11 Relative Lane";
BA_ "VNSigAllNodes" SG_ 1403 RwdFusTrkB11RelLane 1;
BA_ "SignalType" SG_ 1403 RwdFusTrkB11Height "UNM";
BA_ "SignalLongName" SG_ 1403 RwdFusTrkB11Height "Rearward Fusion Track B11 Height";
BA_ "GenSigStartValue" SG_ 1403 RwdFusTrkB11Height 1;
BA_ "VNSigAllNodes" SG_ 1403 RwdFusTrkB11Height 1;
BA_ "SignalType" SG_ 1403 RFusTrkB11ObjSrcLFSrr "ENM";
BA_ "SignalLongName" SG_ 1403 RFusTrkB11ObjSrcLFSrr "Rearward Fusion Track B11 Object Source LFSRR";
BA_ "VNSigAllNodes" SG_ 1403 RFusTrkB11ObjSrcLFSrr 1;
BA_ "SignalType" SG_ 1403 RFusTrkB11ObjSrcLCSrr "ENM";
BA_ "SignalLongName" SG_ 1403 RFusTrkB11ObjSrcLCSrr "Rearward Fusion Track B11 Object Source LCSRR";
BA_ "VNSigAllNodes" SG_ 1403 RFusTrkB11ObjSrcLCSrr 1;
BA_ "SignalType" SG_ 1403 RFusTrkB11ObjSrcRCSrr "ENM";
BA_ "SignalLongName" SG_ 1403 RFusTrkB11ObjSrcRCSrr "Rearward Fusion Track B11 Object Source RCSRR";
BA_ "VNSigAllNodes" SG_ 1403 RFusTrkB11ObjSrcRCSrr 1;
BA_ "SignalType" SG_ 1403 RFusTrkB11ObjSrcRFSrr "ENM";
BA_ "SignalLongName" SG_ 1403 RFusTrkB11ObjSrcRFSrr "Rearward Fusion Track B11 Object Source RFSRR";
BA_ "VNSigAllNodes" SG_ 1403 RFusTrkB11ObjSrcRFSrr 1;
BA_ "SignalType" SG_ 1403 RFusTrkB11ObjSrcVIs "ENM";
BA_ "SignalLongName" SG_ 1403 RFusTrkB11ObjSrcVIs "Rearward Fusion Track B11 Object Source VIS";
BA_ "VNSigAllNodes" SG_ 1403 RFusTrkB11ObjSrcVIs 1;
BA_ "SignalType" SG_ 1403 RwdFusTrkB11ObjSrcLrr "ENM";
BA_ "SignalLongName" SG_ 1403 RwdFusTrkB11ObjSrcLrr "Rearward Fusion Track B11 Object Source LRR";
BA_ "VNSigAllNodes" SG_ 1403 RwdFusTrkB11ObjSrcLrr 1;
BA_ "SignalType" SG_ 1403 RwdFusTrkB11NmCycTrkd "UNM";
BA_ "SignalLongName" SG_ 1403 RwdFusTrkB11NmCycTrkd "Rearward Fusion Track B11 Number of Cycles Tracked";
BA_ "VNSigAllNodes" SG_ 1403 RwdFusTrkB11NmCycTrkd 1;
BA_ "SignalType" SG_ 1403 RwdFusTrkB11LatPosDev "UNM";
BA_ "SignalLongName" SG_ 1403 RwdFusTrkB11LatPosDev "Rearward Fusion Track B11 Lateral Position Deviation";
BA_ "VNSigAllNodes" SG_ 1403 RwdFusTrkB11LatPosDev 1;
BA_ "SignalType" SG_ 1403 RwdFusTrkB11LngPosDev "UNM";
BA_ "SignalLongName" SG_ 1403 RwdFusTrkB11LngPosDev "Rearward Fusion Track B11 Longitudinal Positioin Deviation";
BA_ "VNSigAllNodes" SG_ 1403 RwdFusTrkB11LngPosDev 1;
BA_ "SignalType" SG_ 1402 RwdFusTrkB10NmCycTrkd "UNM";
BA_ "SignalLongName" SG_ 1402 RwdFusTrkB10NmCycTrkd "Rearward Fusion Track B10 Number of Cycles Tracked";
BA_ "VNSigAllNodes" SG_ 1402 RwdFusTrkB10NmCycTrkd 1;
BA_ "SignalType" SG_ 1402 RwdFusTrkB10LatPosDev "UNM";
BA_ "SignalLongName" SG_ 1402 RwdFusTrkB10LatPosDev "Rearward Fusion Track B10 Lateral Position Deviation";
BA_ "VNSigAllNodes" SG_ 1402 RwdFusTrkB10LatPosDev 1;
BA_ "SignalType" SG_ 1402 RwdFusTrkB10LngPosDev "UNM";
BA_ "SignalLongName" SG_ 1402 RwdFusTrkB10LngPosDev "Rearward Fusion Track B10 Longitudinal Positioin Deviation";
BA_ "VNSigAllNodes" SG_ 1402 RwdFusTrkB10LngPosDev 1;
BA_ "SignalType" SG_ 1402 RwdFusTrkBAnlgRlLn10 "SNM";
BA_ "SignalLongName" SG_ 1402 RwdFusTrkBAnlgRlLn10 "Rwd Fusion Track B Analog relative Lane 10";
BA_ "VNSigAllNodes" SG_ 1402 RwdFusTrkBAnlgRlLn10 1;
BA_ "SignalType" SG_ 1402 RwdFusTrkB10RollingCnt "UNM";
BA_ "SignalLongName" SG_ 1402 RwdFusTrkB10RollingCnt "Rearward Fusion Track B10 Rolling Count";
BA_ "VNSigAllNodes" SG_ 1402 RwdFusTrkB10RollingCnt 1;
BA_ "SignalType" SG_ 1402 RwdFusTrkB10Width "UNM";
BA_ "SignalLongName" SG_ 1402 RwdFusTrkB10Width "Rearward Fusion Track B10 Width";
BA_ "GenSigStartValue" SG_ 1402 RwdFusTrkB10Width 1;
BA_ "VNSigAllNodes" SG_ 1402 RwdFusTrkB10Width 1;
BA_ "SignalType" SG_ 1402 RwdFusTrkB10MsgIndex "UNM";
BA_ "SignalLongName" SG_ 1402 RwdFusTrkB10MsgIndex "Rearward Fusion Track B10 Message Index";
BA_ "VNSigAllNodes" SG_ 1402 RwdFusTrkB10MsgIndex 1;
BA_ "SignalType" SG_ 1402 RwdFusTrkB10DynProp "ENM";
BA_ "SignalLongName" SG_ 1402 RwdFusTrkB10DynProp "Rearward Fusion Track B10 Dynamic Property";
BA_ "VNSigAllNodes" SG_ 1402 RwdFusTrkB10DynProp 1;
BA_ "SignalType" SG_ 1402 RwdFusTrkB10RelLnAccl "SNM";
BA_ "SignalLongName" SG_ 1402 RwdFusTrkB10RelLnAccl "Rearward Fusion Track B10 Relative Lane Acceleration";
BA_ "VNSigAllNodes" SG_ 1402 RwdFusTrkB10RelLnAccl 1;
BA_ "SignalType" SG_ 1402 RwdFusTrkB10RelLane "ENM";
BA_ "SignalLongName" SG_ 1402 RwdFusTrkB10RelLane "Rearward Fusion Track B10 Relative Lane";
BA_ "VNSigAllNodes" SG_ 1402 RwdFusTrkB10RelLane 1;
BA_ "SignalType" SG_ 1402 RwdFusTrkB10Height "UNM";
BA_ "SignalLongName" SG_ 1402 RwdFusTrkB10Height "Rearward Fusion Track B10 Height";
BA_ "GenSigStartValue" SG_ 1402 RwdFusTrkB10Height 1;
BA_ "VNSigAllNodes" SG_ 1402 RwdFusTrkB10Height 1;
BA_ "SignalType" SG_ 1402 RFusTrkB10ObjSrcLFSrr "ENM";
BA_ "SignalLongName" SG_ 1402 RFusTrkB10ObjSrcLFSrr "Rearward Fusion Track B10 Object Source LFSRR";
BA_ "VNSigAllNodes" SG_ 1402 RFusTrkB10ObjSrcLFSrr 1;
BA_ "SignalType" SG_ 1402 RFusTrkB10ObjSrcLCSrr "ENM";
BA_ "SignalLongName" SG_ 1402 RFusTrkB10ObjSrcLCSrr "Rearward Fusion Track B10 Object Source LCSRR";
BA_ "VNSigAllNodes" SG_ 1402 RFusTrkB10ObjSrcLCSrr 1;
BA_ "SignalType" SG_ 1402 RFusTrkB10ObjSrcRCSrr "ENM";
BA_ "SignalLongName" SG_ 1402 RFusTrkB10ObjSrcRCSrr "Rearward Fusion Track B10 Object Source RCSRR";
BA_ "VNSigAllNodes" SG_ 1402 RFusTrkB10ObjSrcRCSrr 1;
BA_ "SignalType" SG_ 1402 RFusTrkB10ObjSrcRFSrr "ENM";
BA_ "SignalLongName" SG_ 1402 RFusTrkB10ObjSrcRFSrr "Rearward Fusion Track B10 Object Source RFSRR";
BA_ "VNSigAllNodes" SG_ 1402 RFusTrkB10ObjSrcRFSrr 1;
BA_ "SignalType" SG_ 1402 RFusTrkB10ObjSrcVIs "ENM";
BA_ "SignalLongName" SG_ 1402 RFusTrkB10ObjSrcVIs "Rearward Fusion Track B10 Object Source VIS";
BA_ "VNSigAllNodes" SG_ 1402 RFusTrkB10ObjSrcVIs 1;
BA_ "SignalType" SG_ 1402 RwdFusTrkB10ObjSrcLrr "ENM";
BA_ "SignalLongName" SG_ 1402 RwdFusTrkB10ObjSrcLrr "Rearward Fusion Track B10 Object Source LRR";
BA_ "VNSigAllNodes" SG_ 1402 RwdFusTrkB10ObjSrcLrr 1;
BA_ "SignalType" SG_ 1393 RwdFusTrkBAnlgRlLn1 "SNM";
BA_ "SignalLongName" SG_ 1393 RwdFusTrkBAnlgRlLn1 "Rwd Fusion Track B Analog relative Lane 1";
BA_ "VNSigAllNodes" SG_ 1393 RwdFusTrkBAnlgRlLn1 1;
BA_ "SignalType" SG_ 1393 RwdFusTrkB1RollingCnt "UNM";
BA_ "SignalLongName" SG_ 1393 RwdFusTrkB1RollingCnt "Rearward Fusion Track B1 Rolling Count";
BA_ "VNSigAllNodes" SG_ 1393 RwdFusTrkB1RollingCnt 1;
BA_ "SignalType" SG_ 1393 RwdFusTrkB1Width "UNM";
BA_ "SignalLongName" SG_ 1393 RwdFusTrkB1Width "Rearward Fusion Track B1 Width";
BA_ "GenSigStartValue" SG_ 1393 RwdFusTrkB1Width 1;
BA_ "VNSigAllNodes" SG_ 1393 RwdFusTrkB1Width 1;
BA_ "SignalType" SG_ 1393 RwdFusTrkB1MsgIndex "UNM";
BA_ "SignalLongName" SG_ 1393 RwdFusTrkB1MsgIndex "Rearward Fusion Track B1 Message Index";
BA_ "VNSigAllNodes" SG_ 1393 RwdFusTrkB1MsgIndex 1;
BA_ "SignalType" SG_ 1393 RwdFusTrkB1DynProp "ENM";
BA_ "SignalLongName" SG_ 1393 RwdFusTrkB1DynProp "Rearward Fusion Track B1 Dynamic Property";
BA_ "VNSigAllNodes" SG_ 1393 RwdFusTrkB1DynProp 1;
BA_ "SignalType" SG_ 1393 RwdFusTrkB1RelLnAccl "SNM";
BA_ "SignalLongName" SG_ 1393 RwdFusTrkB1RelLnAccl "Rearward Fusion Track B1 Relative Lane Acceleration";
BA_ "VNSigAllNodes" SG_ 1393 RwdFusTrkB1RelLnAccl 1;
BA_ "SignalType" SG_ 1393 RwdFusTrkB1RelLane "ENM";
BA_ "SignalLongName" SG_ 1393 RwdFusTrkB1RelLane "Rearward Fusion Track B1 Relative Lane";
BA_ "VNSigAllNodes" SG_ 1393 RwdFusTrkB1RelLane 1;
BA_ "SignalType" SG_ 1393 RwdFusTrkB1Height "UNM";
BA_ "SignalLongName" SG_ 1393 RwdFusTrkB1Height "Rearward Fusion Track B1 Height";
BA_ "GenSigStartValue" SG_ 1393 RwdFusTrkB1Height 1;
BA_ "VNSigAllNodes" SG_ 1393 RwdFusTrkB1Height 1;
BA_ "SignalType" SG_ 1393 RFusTrkB1ObjSrcLFSrr "ENM";
BA_ "SignalLongName" SG_ 1393 RFusTrkB1ObjSrcLFSrr "Rearward Fusion Track B1 Object Source LFSRR";
BA_ "VNSigAllNodes" SG_ 1393 RFusTrkB1ObjSrcLFSrr 1;
BA_ "SignalType" SG_ 1393 RFusTrkB1ObjSrcLCSrr "ENM";
BA_ "SignalLongName" SG_ 1393 RFusTrkB1ObjSrcLCSrr "Rearward Fusion Track B1 Object Source LCSRR";
BA_ "VNSigAllNodes" SG_ 1393 RFusTrkB1ObjSrcLCSrr 1;
BA_ "SignalType" SG_ 1393 RFusTrkB1ObjSrcRCSrr "ENM";
BA_ "SignalLongName" SG_ 1393 RFusTrkB1ObjSrcRCSrr "Rearward Fusion Track B1 Object Source RCSRR";
BA_ "VNSigAllNodes" SG_ 1393 RFusTrkB1ObjSrcRCSrr 1;
BA_ "SignalType" SG_ 1393 RFusTrkB1ObjSrcRFSrr "ENM";
BA_ "SignalLongName" SG_ 1393 RFusTrkB1ObjSrcRFSrr "Rearward Fusion Track B1 Object Source RFSRR";
BA_ "VNSigAllNodes" SG_ 1393 RFusTrkB1ObjSrcRFSrr 1;
BA_ "SignalType" SG_ 1393 RFusTrkB1ObjSrcVIs "ENM";
BA_ "SignalLongName" SG_ 1393 RFusTrkB1ObjSrcVIs "Rearward Fusion Track B1 Object Source VIS";
BA_ "VNSigAllNodes" SG_ 1393 RFusTrkB1ObjSrcVIs 1;
BA_ "SignalType" SG_ 1393 RwdFusTrkB1ObjSrcLrr "ENM";
BA_ "SignalLongName" SG_ 1393 RwdFusTrkB1ObjSrcLrr "Rearward Fusion Track B1 Object Source LRR";
BA_ "VNSigAllNodes" SG_ 1393 RwdFusTrkB1ObjSrcLrr 1;
BA_ "SignalType" SG_ 1393 RwdFusTrkB1NmCycTrkd "UNM";
BA_ "SignalLongName" SG_ 1393 RwdFusTrkB1NmCycTrkd "Rearward Fusion Track B1 Number of Cycles Tracked";
BA_ "VNSigAllNodes" SG_ 1393 RwdFusTrkB1NmCycTrkd 1;
BA_ "SignalType" SG_ 1393 RwdFusTrkB1LatPosDev "UNM";
BA_ "SignalLongName" SG_ 1393 RwdFusTrkB1LatPosDev "Rearward Fusion Track B1 Lateral Position Deviation";
BA_ "VNSigAllNodes" SG_ 1393 RwdFusTrkB1LatPosDev 1;
BA_ "SignalType" SG_ 1393 RwdFusTrkB1LngPosDev "UNM";
BA_ "SignalLongName" SG_ 1393 RwdFusTrkB1LngPosDev "Rearward Fusion Track B1 Longitudinal Positioin Deviation";
BA_ "VNSigAllNodes" SG_ 1393 RwdFusTrkB1LngPosDev 1;
BA_ "SignalType" SG_ 1385 RwdFusTrkA9RollingCnt "UNM";
BA_ "SignalLongName" SG_ 1385 RwdFusTrkA9RollingCnt "Rearward Fusion Track A9 Rolling Count";
BA_ "VNSigAllNodes" SG_ 1385 RwdFusTrkA9RollingCnt 1;
BA_ "SignalType" SG_ 1385 RwdFusTrkA9ObjectID "UNM";
BA_ "SignalLongName" SG_ 1385 RwdFusTrkA9ObjectID "Rearward Fusion Track A9 Object ID";
BA_ "VNSigAllNodes" SG_ 1385 RwdFusTrkA9ObjectID 1;
BA_ "SignalType" SG_ 1385 RwdFusTrkA9MsgIndex "UNM";
BA_ "SignalLongName" SG_ 1385 RwdFusTrkA9MsgIndex "Rearward Fusion Track A9 Message Index";
BA_ "VNSigAllNodes" SG_ 1385 RwdFusTrkA9MsgIndex 1;
BA_ "SignalType" SG_ 1385 RwdFusTrkA9LongPos "SNM";
BA_ "SignalLongName" SG_ 1385 RwdFusTrkA9LongPos "Rearward Fusion Track A9 Longitudinal Position";
BA_ "VNSigAllNodes" SG_ 1385 RwdFusTrkA9LongPos 1;
BA_ "SignalType" SG_ 1385 RwdFusTrkA9RelLongVel "SNM";
BA_ "SignalLongName" SG_ 1385 RwdFusTrkA9RelLongVel "Rearward Fusion Track A9 Relative Longitudinal Velocity";
BA_ "VNSigAllNodes" SG_ 1385 RwdFusTrkA9RelLongVel 1;
BA_ "SignalType" SG_ 1385 RwdFusTrkA9Confidence "ENM";
BA_ "SignalLongName" SG_ 1385 RwdFusTrkA9Confidence "Rearward Fusion Track A9 Confidence";
BA_ "VNSigAllNodes" SG_ 1385 RwdFusTrkA9Confidence 1;
BA_ "SignalType" SG_ 1385 RwdFusTrkA9LatPos "SNM";
BA_ "SignalLongName" SG_ 1385 RwdFusTrkA9LatPos "Rearward Fusion Track A9 Lateral Position";
BA_ "VNSigAllNodes" SG_ 1385 RwdFusTrkA9LatPos 1;
BA_ "SignalType" SG_ 1385 RwdFusTrkA9RelLatVel "SNM";
BA_ "SignalLongName" SG_ 1385 RwdFusTrkA9RelLatVel "Rearward Fusion Track A9 Relative Lateral Velocity";
BA_ "VNSigAllNodes" SG_ 1385 RwdFusTrkA9RelLatVel 1;
BA_ "SignalType" SG_ 1385 RwdFusTrkA9MeasStatus "ENM";
BA_ "SignalLongName" SG_ 1385 RwdFusTrkA9MeasStatus "Rearward Fusion Track A9 Measurement Status";
BA_ "VNSigAllNodes" SG_ 1385 RwdFusTrkA9MeasStatus 1;
BA_ "SignalType" SG_ 1385 RwdFusTrkA9ObjType "ENM";
BA_ "SignalLongName" SG_ 1385 RwdFusTrkA9ObjType "Rearward Fusion Track A9 Object Type";
BA_ "VNSigAllNodes" SG_ 1385 RwdFusTrkA9ObjType 1;
BA_ "SignalType" SG_ 1384 RwdFusTrkA8RollingCnt "UNM";
BA_ "SignalLongName" SG_ 1384 RwdFusTrkA8RollingCnt "Rearward Fusion Track A8 Rolling Count";
BA_ "VNSigAllNodes" SG_ 1384 RwdFusTrkA8RollingCnt 1;
BA_ "SignalType" SG_ 1384 RwdFusTrkA8ObjectID "UNM";
BA_ "SignalLongName" SG_ 1384 RwdFusTrkA8ObjectID "Rearward Fusion Track A8 Object ID";
BA_ "VNSigAllNodes" SG_ 1384 RwdFusTrkA8ObjectID 1;
BA_ "SignalType" SG_ 1384 RwdFusTrkA8MsgIndex "UNM";
BA_ "SignalLongName" SG_ 1384 RwdFusTrkA8MsgIndex "Rearward Fusion Track A8 Message Index";
BA_ "VNSigAllNodes" SG_ 1384 RwdFusTrkA8MsgIndex 1;
BA_ "SignalType" SG_ 1384 RwdFusTrkA8LongPos "SNM";
BA_ "SignalLongName" SG_ 1384 RwdFusTrkA8LongPos "Rearward Fusion Track A8 Longitudinal Position";
BA_ "VNSigAllNodes" SG_ 1384 RwdFusTrkA8LongPos 1;
BA_ "SignalType" SG_ 1384 RwdFusTrkA8RelLongVel "SNM";
BA_ "SignalLongName" SG_ 1384 RwdFusTrkA8RelLongVel "Rearward Fusion Track A8 Relative Longitudinal Velocity";
BA_ "VNSigAllNodes" SG_ 1384 RwdFusTrkA8RelLongVel 1;
BA_ "SignalType" SG_ 1384 RwdFusTrkA8Confidence "ENM";
BA_ "SignalLongName" SG_ 1384 RwdFusTrkA8Confidence "Rearward Fusion Track A8 Confidence";
BA_ "VNSigAllNodes" SG_ 1384 RwdFusTrkA8Confidence 1;
BA_ "SignalType" SG_ 1384 RwdFusTrkA8LatPos "SNM";
BA_ "SignalLongName" SG_ 1384 RwdFusTrkA8LatPos "Rearward Fusion Track A8 Lateral Position";
BA_ "VNSigAllNodes" SG_ 1384 RwdFusTrkA8LatPos 1;
BA_ "SignalType" SG_ 1384 RwdFusTrkA8RelLatVel "SNM";
BA_ "SignalLongName" SG_ 1384 RwdFusTrkA8RelLatVel "Rearward Fusion Track A8 Relative Lateral Velocity";
BA_ "VNSigAllNodes" SG_ 1384 RwdFusTrkA8RelLatVel 1;
BA_ "SignalType" SG_ 1384 RwdFusTrkA8MeasStatus "ENM";
BA_ "SignalLongName" SG_ 1384 RwdFusTrkA8MeasStatus "Rearward Fusion Track A8 Measurement Status";
BA_ "VNSigAllNodes" SG_ 1384 RwdFusTrkA8MeasStatus 1;
BA_ "SignalType" SG_ 1384 RwdFusTrkA8ObjType "ENM";
BA_ "SignalLongName" SG_ 1384 RwdFusTrkA8ObjType "Rearward Fusion Track A8 Object Type";
BA_ "VNSigAllNodes" SG_ 1384 RwdFusTrkA8ObjType 1;
BA_ "SignalType" SG_ 1362 FObjConfCPSTrkObjectIDB "UNM";
BA_ "SignalLongName" SG_ 1362 FObjConfCPSTrkObjectIDB "Forward Object Confirmation Collision Preparation System Track Object ID B";
BA_ "VNSigAllNodes" SG_ 1362 FObjConfCPSTrkObjectIDB 1;
BA_ "SignalType" SG_ 1362 CPSVisConfLonPos1 "SNM";
BA_ "SignalLongName" SG_ 1362 CPSVisConfLonPos1 "CPS Vision Confirmation Longitudinal Position 1";
BA_ "VNSigAllNodes" SG_ 1362 CPSVisConfLonPos1 1;
BA_ "SignalType" SG_ 1362 CPSVisConfLatPos1 "SNM";
BA_ "SignalLongName" SG_ 1362 CPSVisConfLatPos1 "CPS Vision Confirmation Lateral Position 1";
BA_ "VNSigAllNodes" SG_ 1362 CPSVisConfLatPos1 1;
BA_ "SignalType" SG_ 1362 CPSVisConfChecksum "UNM";
BA_ "SignalLongName" SG_ 1362 CPSVisConfChecksum "CPS Vision Confirmation Checksum";
BA_ "VNSigAllNodes" SG_ 1362 CPSVisConfChecksum 1;
BA_ "SignalType" SG_ 1362 FObjConfCPSTrkRangeRate "SNM";
BA_ "SignalLongName" SG_ 1362 FObjConfCPSTrkRangeRate "Forward Object Confirmation Collision Preparation System Track Range Rate";
BA_ "VNSigAllNodes" SG_ 1362 FObjConfCPSTrkRangeRate 1;
BA_ "SignalType" SG_ 1362 CPSConfTimeStamp "UNM";
BA_ "SignalLongName" SG_ 1362 CPSConfTimeStamp "CPS Confirmation Time Stamp";
BA_ "VNSigAllNodes" SG_ 1362 CPSConfTimeStamp 1;
BA_ "SignalType" SG_ 1362 CPSConfTimeStampV "ENM";
BA_ "SignalLongName" SG_ 1362 CPSConfTimeStampV "CPS Confirmation Time Stamp Validity";
BA_ "VNSigAllNodes" SG_ 1362 CPSConfTimeStampV 1;
BA_ "SignalType" SG_ 1362 FObjConfCPSRollingTrkCnt "UNM";
BA_ "SignalLongName" SG_ 1362 FObjConfCPSRollingTrkCnt "Forward Object Confirmation Collision Preparation System Track Rolling Count";
BA_ "VNSigAllNodes" SG_ 1362 FObjConfCPSRollingTrkCnt 1;
BA_ "SignalType" SG_ 1413 TOS_ACC_IDSRollCnt "UNM";
BA_ "SignalLongName" SG_ 1413 TOS_ACC_IDSRollCnt "TOS ACC IDS Rolling Count";
BA_ "VNSigAllNodes" SG_ 1413 TOS_ACC_IDSRollCnt 1;
BA_ "SignalType" SG_ 1413 TOS_ACC_IDSFuncState "UNM";
BA_ "SignalLongName" SG_ 1413 TOS_ACC_IDSFuncState "TOS ACC IDS Functional State";
BA_ "VNSigAllNodes" SG_ 1413 TOS_ACC_IDSFuncState 1;
BA_ "SignalType" SG_ 1413 TOS_ACC_ID1 "UNM";
BA_ "SignalLongName" SG_ 1413 TOS_ACC_ID1 "TOS ACC ID1";
BA_ "VNSigAllNodes" SG_ 1413 TOS_ACC_ID1 1;
BA_ "SignalType" SG_ 1413 TOS_ACC_ID2 "UNM";
BA_ "SignalLongName" SG_ 1413 TOS_ACC_ID2 "TOS ACC ID2";
BA_ "VNSigAllNodes" SG_ 1413 TOS_ACC_ID2 1;
BA_ "SignalType" SG_ 1413 TOS_ACC_ID3 "UNM";
BA_ "SignalLongName" SG_ 1413 TOS_ACC_ID3 "TOS ACC ID3";
BA_ "VNSigAllNodes" SG_ 1413 TOS_ACC_ID3 1;
BA_ "SignalType" SG_ 1413 TOS_ACC_ID4 "UNM";
BA_ "SignalLongName" SG_ 1413 TOS_ACC_ID4 "TOS ACC ID4";
BA_ "VNSigAllNodes" SG_ 1413 TOS_ACC_ID4 1;
BA_ "SignalType" SG_ 1413 TOS_ACC_ID5 "UNM";
BA_ "SignalLongName" SG_ 1413 TOS_ACC_ID5 "TOS ACC ID5";
BA_ "VNSigAllNodes" SG_ 1413 TOS_ACC_ID5 1;
BA_ "SignalType" SG_ 1413 TOS_ACC_ID6 "UNM";
BA_ "SignalLongName" SG_ 1413 TOS_ACC_ID6 "TOS ACC ID6";
BA_ "VNSigAllNodes" SG_ 1413 TOS_ACC_ID6 1;
BA_ "SignalType" SG_ 1412 FACCTOSRollCnt "UNM";
BA_ "SignalLongName" SG_ 1412 FACCTOSRollCnt "FACCTOS Rolling Count";
BA_ "VNSigAllNodes" SG_ 1412 FACCTOSRollCnt 1;
BA_ "SignalType" SG_ 1412 FACCTOSFuncState "UNM";
BA_ "SignalLongName" SG_ 1412 FACCTOSFuncState "FACCTOS Functional State";
BA_ "VNSigAllNodes" SG_ 1412 FACCTOSFuncState 1;
BA_ "SignalType" SG_ 1412 FACCTOSLongPos "SNM";
BA_ "SignalLongName" SG_ 1412 FACCTOSLongPos "FACCTOS Longitudinal Position";
BA_ "VNSigAllNodes" SG_ 1412 FACCTOSLongPos 1;
BA_ "SignalType" SG_ 1412 FACCTOSLatPos "SNM";
BA_ "SignalLongName" SG_ 1412 FACCTOSLatPos "FACCTOS Lateral Position";
BA_ "VNSigAllNodes" SG_ 1412 FACCTOSLatPos 1;
BA_ "SignalType" SG_ 1412 FACCTOSMeasStat "UNM";
BA_ "SignalLongName" SG_ 1412 FACCTOSMeasStat "FACCTOS Measurement Status";
BA_ "VNSigAllNodes" SG_ 1412 FACCTOSMeasStat 1;
BA_ "SignalType" SG_ 1412 FACCTOSLongVel "SNM";
BA_ "SignalLongName" SG_ 1412 FACCTOSLongVel "FACCTOS Longitudinal Velocity";
BA_ "VNSigAllNodes" SG_ 1412 FACCTOSLongVel 1;
BA_ "SignalType" SG_ 1412 FACCTOSTrgtDecelFlg "UNM";
BA_ "SignalLongName" SG_ 1412 FACCTOSTrgtDecelFlg "FACCTOS Target Decelerating Flag";
BA_ "VNSigAllNodes" SG_ 1412 FACCTOSTrgtDecelFlg 1;
BA_ "SignalType" SG_ 1412 FACCTOSDynProp "ENM";
BA_ "SignalLongName" SG_ 1412 FACCTOSDynProp "FACCTOS Dynamic Property";
BA_ "VNSigAllNodes" SG_ 1412 FACCTOSDynProp 1;
BA_ "SignalType" SG_ 1412 FACCTOSLatVel "SNM";
BA_ "SignalLongName" SG_ 1412 FACCTOSLatVel "FACCTOS Lateral Velocity";
BA_ "VNSigAllNodes" SG_ 1412 FACCTOSLatVel 1;
BA_ "SignalType" SG_ 1412 FACCTOSRelLane "UNM";
BA_ "SignalLongName" SG_ 1412 FACCTOSRelLane "FACCTOS Relative Lane";
BA_ "VNSigAllNodes" SG_ 1412 FACCTOSRelLane 1;
BA_ "SignalType" SG_ 1412 FACCTOSHiThrtID "UNM";
BA_ "SignalLongName" SG_ 1412 FACCTOSHiThrtID "FACCTOS Highest Threat Object ID";
BA_ "VNSigAllNodes" SG_ 1412 FACCTOSHiThrtID 1;
BA_ "SignalType" SG_ 1409 CPSTOSObjType "UNM";
BA_ "SignalLongName" SG_ 1409 CPSTOSObjType "CPSTOS Highest Threat object Type";
BA_ "VNSigAllNodes" SG_ 1409 CPSTOSObjType 1;
BA_ "SignalType" SG_ 1409 CPSTOSHiThrtPriNo "UNM";
BA_ "SignalLongName" SG_ 1409 CPSTOSHiThrtPriNo "CPSTOS Highest threat Object Priority Number";
BA_ "VNSigAllNodes" SG_ 1409 CPSTOSHiThrtPriNo 1;
BA_ "SignalType" SG_ 1409 CPSTOSRelLongAcc "SNM";
BA_ "SignalLongName" SG_ 1409 CPSTOSRelLongAcc "CPSTOS Highest Threat Object RelativeLongitudinal Acceleration";
BA_ "VNSigAllNodes" SG_ 1409 CPSTOSRelLongAcc 1;
BA_ "SignalType" SG_ 1409 CPSTOSConfAsmt "UNM";
BA_ "SignalLongName" SG_ 1409 CPSTOSConfAsmt "CPSTOS Confidence Assessment";
BA_ "VNSigAllNodes" SG_ 1409 CPSTOSConfAsmt 1;
BA_ "SignalType" SG_ 1409 CPSTOSNumCycTrkd "UNM";
BA_ "SignalLongName" SG_ 1409 CPSTOSNumCycTrkd "CPSTOS Highest Threat Object Number of Cycles Tracked";
BA_ "VNSigAllNodes" SG_ 1409 CPSTOSNumCycTrkd 1;
BA_ "SignalType" SG_ 1409 CPSTOSTimeToColl "UNM";
BA_ "SignalLongName" SG_ 1409 CPSTOSTimeToColl "CPSTOS Highest Threat Object Time To Collision";
BA_ "VNSigAllNodes" SG_ 1409 CPSTOSTimeToColl 1;
BA_ "SignalType" SG_ 1409 CPSTOSClosestInPthVehRng "UNM";
BA_ "SignalLongName" SG_ 1409 CPSTOSClosestInPthVehRng "CPSTOS Closest In path vehicle range";
BA_ "VNSigAllNodes" SG_ 1409 CPSTOSClosestInPthVehRng 1;
BA_ "SignalType" SG_ 1409 CPSTOSClosestInPthObID "UNM";
BA_ "SignalLongName" SG_ 1409 CPSTOSClosestInPthObID "CPSTOS Closest In Path Vehicle Object ID";
BA_ "GenSigStartValue" SG_ 1409 CPSTOSClosestInPthObID 0.25;
BA_ "VNSigAllNodes" SG_ 1409 CPSTOSClosestInPthObID 1;
BA_ "SignalType" SG_ 1409 CPSTOSMeasStat "UNM";
BA_ "SignalLongName" SG_ 1409 CPSTOSMeasStat "CPSTOS Highest Threat Object Measurement Status";
BA_ "VNSigAllNodes" SG_ 1409 CPSTOSMeasStat 1;
BA_ "SignalType" SG_ 1409 CPSTOSFuncState "UNM";
BA_ "SignalLongName" SG_ 1409 CPSTOSFuncState "CPSTOS Functional State";
BA_ "VNSigAllNodes" SG_ 1409 CPSTOSFuncState 1;
BA_ "SignalType" SG_ 1408 CPSTOSLongPos "SNM";
BA_ "SignalLongName" SG_ 1408 CPSTOSLongPos "CPSTOS Highest Threat Object Longitudinal Position";
BA_ "VNSigAllNodes" SG_ 1408 CPSTOSLongPos 1;
BA_ "SignalType" SG_ 1408 CPSTOSLatPos "SNM";
BA_ "SignalLongName" SG_ 1408 CPSTOSLatPos "CPSTOS Highest threat object Lateral Position";
BA_ "VNSigAllNodes" SG_ 1408 CPSTOSLatPos 1;
BA_ "SignalType" SG_ 1408 CPSTOSLongVel "SNM";
BA_ "SignalLongName" SG_ 1408 CPSTOSLongVel "CPSTOS Highest Threat Object RelativeLongitudinal Velocity";
BA_ "VNSigAllNodes" SG_ 1408 CPSTOSLongVel 1;
BA_ "SignalType" SG_ 1408 CPSTOSDynProp "ENM";
BA_ "SignalLongName" SG_ 1408 CPSTOSDynProp "CPSTOS Highest threat object Dynamic Property";
BA_ "VNSigAllNodes" SG_ 1408 CPSTOSDynProp 1;
BA_ "SignalType" SG_ 1408 CPSTOSLatVel "SNM";
BA_ "SignalLongName" SG_ 1408 CPSTOSLatVel "CPSTOS Highest Threat Object Lateral Velocity";
BA_ "VNSigAllNodes" SG_ 1408 CPSTOSLatVel 1;
BA_ "SignalType" SG_ 1408 CPSTOSARelLane "UNM";
BA_ "SignalLongName" SG_ 1408 CPSTOSARelLane "CPSTOS A Highest Threat Object Relative Lane";
BA_ "VNSigAllNodes" SG_ 1408 CPSTOSARelLane 1;
BA_ "SignalType" SG_ 1408 CPSTOSHiThrtID "UNM";
BA_ "SignalLongName" SG_ 1408 CPSTOSHiThrtID "CPSTOS Highest Threat object ID";
BA_ "VNSigAllNodes" SG_ 1408 CPSTOSHiThrtID 1;
BA_ "SignalType" SG_ 1408 CPSTOSHighestThreatObAsmt "UNM";
BA_ "SignalLongName" SG_ 1408 CPSTOSHighestThreatObAsmt "CPSTOS Highest threat Object Assessment";
BA_ "VNSigAllNodes" SG_ 1408 CPSTOSHighestThreatObAsmt 1;
BA_ "SignalType" SG_ 1344 FLPRollCount "UNM";
BA_ "SignalLongName" SG_ 1344 FLPRollCount "Forward Lane Path Rolling Count";
BA_ "VNSigAllNodes" SG_ 1344 FLPRollCount 1;
BA_ "SignalType" SG_ 1344 NewLaneIndex "UNM";
BA_ "SignalLongName" SG_ 1344 NewLaneIndex "New Lane Index";
BA_ "VNSigAllNodes" SG_ 1344 NewLaneIndex 1;
BA_ "SignalType" SG_ 1344 VehPathInOK "UNM";
BA_ "SignalLongName" SG_ 1344 VehPathInOK "Vehicle Path Input OK";
BA_ "VNSigAllNodes" SG_ 1344 VehPathInOK 1;
BA_ "SignalType" SG_ 1344 LaneSnsInOK "UNM";
BA_ "SignalLongName" SG_ 1344 LaneSnsInOK "Lane Sense Input OK";
BA_ "VNSigAllNodes" SG_ 1344 LaneSnsInOK 1;
BA_ "SignalType" SG_ 1344 MapInOK "UNM";
BA_ "SignalLongName" SG_ 1344 MapInOK "Map Input OK";
BA_ "VNSigAllNodes" SG_ 1344 MapInOK 1;
BA_ "SignalType" SG_ 1344 FWDObjFusInOK "UNM";
BA_ "SignalLongName" SG_ 1344 FWDObjFusInOK "Forward Object Fusion Input OK";
BA_ "VNSigAllNodes" SG_ 1344 FWDObjFusInOK 1;
BA_ "SignalType" SG_ 1344 LngthFrstSeg "UNM";
BA_ "SignalLongName" SG_ 1344 LngthFrstSeg "Length of First Segment";
BA_ "VNSigAllNodes" SG_ 1344 LngthFrstSeg 1;
BA_ "SignalType" SG_ 1344 LngthScndSeg "UNM";
BA_ "SignalLongName" SG_ 1344 LngthScndSeg "Length of Second Segment";
BA_ "VNSigAllNodes" SG_ 1344 LngthScndSeg 1;
BA_ "SignalType" SG_ 1344 CurvFrstSeg "SNM";
BA_ "SignalLongName" SG_ 1344 CurvFrstSeg "Curvature First Segment";
BA_ "VNSigAllNodes" SG_ 1344 CurvFrstSeg 1;
BA_ "SignalType" SG_ 1344 CurvScndSeg "SNM";
BA_ "SignalLongName" SG_ 1344 CurvScndSeg "Curvature Second Segment";
BA_ "VNSigAllNodes" SG_ 1344 CurvScndSeg 1;
BA_ "SignalType" SG_ 1344 OffstLaneCntr "SNM";
BA_ "SignalLongName" SG_ 1344 OffstLaneCntr "Offset Lane Center";
BA_ "VNSigAllNodes" SG_ 1344 OffstLaneCntr 1;
BA_ "SignalType" SG_ 1344 TngntLaneHead "SNM";
BA_ "SignalLongName" SG_ 1344 TngntLaneHead "Tangent Lane Heading";
BA_ "VNSigAllNodes" SG_ 1344 TngntLaneHead 1;
BA_ "SignalType" SG_ 1344 LaneWidth "UNM";
BA_ "SignalLongName" SG_ 1344 LaneWidth "Lane Width";
BA_ "GenSigStartValue" SG_ 1344 LaneWidth 1;
BA_ "VNSigAllNodes" SG_ 1344 LaneWidth 1;
BA_ "SignalType" SG_ 1344 FLPDataTimeStampV "UNM";
BA_ "SignalLongName" SG_ 1344 FLPDataTimeStampV "Forward Lane Path Data Time Stamp Validity";
BA_ "VNSigAllNodes" SG_ 1344 FLPDataTimeStampV 1;
BA_ "SignalType" SG_ 1344 FLPDataTimeStamp "UNM";
BA_ "SignalLongName" SG_ 1344 FLPDataTimeStamp "Forward Lane Path Data Time Stamp";
BA_ "VNSigAllNodes" SG_ 1344 FLPDataTimeStamp 1;
BA_ "SignalType" SG_ 770 Vpath_Accel "SNM";
BA_ "SignalLongName" SG_ 770 Vpath_Accel "Vehicle Path Acceleration";
BA_ "VNSigAllNodes" SG_ 770 Vpath_Accel 1;
BA_ "SignalType" SG_ 770 FCA_Ra "SNM";
BA_ "SignalLongName" SG_ 770 FCA_Ra "FCA Ra";
BA_ "VNSigAllNodes" SG_ 770 FCA_Ra 1;
BA_ "SignalType" SG_ 770 FCA_Range "SNM";
BA_ "SignalLongName" SG_ 770 FCA_Range "FCA Range";
BA_ "VNSigAllNodes" SG_ 770 FCA_Range 1;
BA_ "SignalType" SG_ 770 FCA_AlertLevel "UNM";
BA_ "SignalLongName" SG_ 770 FCA_AlertLevel "FCA Alert level";
BA_ "VNSigAllNodes" SG_ 770 FCA_AlertLevel 1;
BA_ "SignalType" SG_ 770 FCA_Alert_Sup "UNM";
BA_ "SignalLongName" SG_ 770 FCA_Alert_Sup "FCA Alert Suppresion";
BA_ "VNSigAllNodes" SG_ 770 FCA_Alert_Sup 1;
BA_ "SignalType" SG_ 770 FCAStatus "UNM";
BA_ "SignalLongName" SG_ 770 FCAStatus "FCA Status";
BA_ "VNSigAllNodes" SG_ 770 FCAStatus 1;
BA_ "SignalType" SG_ 770 FCA_VehAhead "UNM";
BA_ "SignalLongName" SG_ 770 FCA_VehAhead "FCA Vehicle Ahead";
BA_ "VNSigAllNodes" SG_ 770 FCA_VehAhead 1;
BA_ "SignalType" SG_ 770 FCA_CPS_Alert "UNM";
BA_ "SignalLongName" SG_ 770 FCA_CPS_Alert "FCA CPS Alert";
BA_ "VNSigAllNodes" SG_ 770 FCA_CPS_Alert 1;
BA_ "SignalType" SG_ 770 FCAChime "UNM";
BA_ "SignalLongName" SG_ 770 FCAChime "FCA Chime";
BA_ "VNSigAllNodes" SG_ 770 FCAChime 1;
BA_ "SignalType" SG_ 770 FCADiagOK "UNM";
BA_ "SignalLongName" SG_ 770 FCADiagOK "FCA Diagnostics OK";
BA_ "VNSigAllNodes" SG_ 770 FCADiagOK 1;
BA_ "SignalType" SG_ 770 NBSMS_Alert "UNM";
BA_ "SignalLongName" SG_ 770 NBSMS_Alert "NBMS Alert";
BA_ "VNSigAllNodes" SG_ 770 NBSMS_Alert 1;
BA_ "VNSigSLHSSharedDiagnostic" SG_ 1601 DgnInf_OBJ641 1;
BA_ "SignalType" SG_ 1601 DgnInf_OBJ641 "UNM";
BA_ "SignalLongName" SG_ 1601 DgnInf_OBJ641 "Diagnostic Information OBJ641";
BA_ "VNSigAllNodes" SG_ 1601 DgnInf_OBJ641 1;
BA_ "VNSigSLHSSharedDiagnostic" SG_ 1606 DgnInf_OBJ646 1;
BA_ "SignalType" SG_ 1606 DgnInf_OBJ646 "UNM";
BA_ "SignalLongName" SG_ 1606 DgnInf_OBJ646 "Diagnostic Information OBJ646";
BA_ "VNSigAllNodes" SG_ 1606 DgnInf_OBJ646 1;
BA_ "VNSigSLHSSharedDiagnostic" SG_ 1603 DgnInf_OBJ643 1;
BA_ "SignalType" SG_ 1603 DgnInf_OBJ643 "UNM";
BA_ "SignalLongName" SG_ 1603 DgnInf_OBJ643 "Diagnostic Information OBJ643";
BA_ "VNSigAllNodes" SG_ 1603 DgnInf_OBJ643 1;
BA_ "VNSigSLHSSharedDiagnostic" SG_ 1602 DgnInf_OBJ642 1;
BA_ "SignalType" SG_ 1602 DgnInf_OBJ642 "UNM";
BA_ "SignalLongName" SG_ 1602 DgnInf_OBJ642 "Diagnostic Information OBJ642";
BA_ "VNSigAllNodes" SG_ 1602 DgnInf_OBJ642 1;
BA_ "VNSigSLHSSharedDiagnostic" SG_ 1625 DgnInf_OBJ644 1;
BA_ "SignalType" SG_ 1625 DgnInf_OBJ644 "UNM";
BA_ "SignalLongName" SG_ 1625 DgnInf_OBJ644 "Diagnostic Information OBJ644";
BA_ "VNSigAllNodes" SG_ 1625 DgnInf_OBJ644 1;
BA_ "VNSigSLHSSharedDiagnostic" SG_ 1611 DgnInf_OBJ64B 1;
BA_ "SignalType" SG_ 1611 DgnInf_OBJ64B "UNM";
BA_ "SignalLongName" SG_ 1611 DgnInf_OBJ64B "Diagnostic Information OBJ64B";
BA_ "VNSigAllNodes" SG_ 1611 DgnInf_OBJ64B 1;
BA_ "SignalType" SG_ 1383 RwdFusTrkA7RollingCnt "UNM";
BA_ "SignalLongName" SG_ 1383 RwdFusTrkA7RollingCnt "Rearward Fusion Track A7 Rolling Count";
BA_ "VNSigAllNodes" SG_ 1383 RwdFusTrkA7RollingCnt 1;
BA_ "SignalType" SG_ 1383 RwdFusTrkA7ObjectID "UNM";
BA_ "SignalLongName" SG_ 1383 RwdFusTrkA7ObjectID "Rearward Fusion Track A7 Object ID";
BA_ "VNSigAllNodes" SG_ 1383 RwdFusTrkA7ObjectID 1;
BA_ "SignalType" SG_ 1383 RwdFusTrkA7MsgIndex "UNM";
BA_ "SignalLongName" SG_ 1383 RwdFusTrkA7MsgIndex "Rearward Fusion Track A7 Message Index";
BA_ "VNSigAllNodes" SG_ 1383 RwdFusTrkA7MsgIndex 1;
BA_ "SignalType" SG_ 1383 RwdFusTrkA7LongPos "SNM";
BA_ "SignalLongName" SG_ 1383 RwdFusTrkA7LongPos "Rearward Fusion Track A7 Longitudinal Position";
BA_ "VNSigAllNodes" SG_ 1383 RwdFusTrkA7LongPos 1;
BA_ "SignalType" SG_ 1383 RwdFusTrkA7RelLongVel "SNM";
BA_ "SignalLongName" SG_ 1383 RwdFusTrkA7RelLongVel "Rearward Fusion Track A7 Relative Longitudinal Velocity";
BA_ "VNSigAllNodes" SG_ 1383 RwdFusTrkA7RelLongVel 1;
BA_ "SignalType" SG_ 1383 RwdFusTrkA7Confidence "ENM";
BA_ "SignalLongName" SG_ 1383 RwdFusTrkA7Confidence "Rearward Fusion Track A7 Confidence";
BA_ "VNSigAllNodes" SG_ 1383 RwdFusTrkA7Confidence 1;
BA_ "SignalType" SG_ 1383 RwdFusTrkA7LatPos "SNM";
BA_ "SignalLongName" SG_ 1383 RwdFusTrkA7LatPos "Rearward Fusion Track A7 Lateral Position";
BA_ "VNSigAllNodes" SG_ 1383 RwdFusTrkA7LatPos 1;
BA_ "SignalType" SG_ 1383 RwdFusTrkA7RelLatVel "SNM";
BA_ "SignalLongName" SG_ 1383 RwdFusTrkA7RelLatVel "Rearward Fusion Track A7 Relative Lateral Velocity";
BA_ "VNSigAllNodes" SG_ 1383 RwdFusTrkA7RelLatVel 1;
BA_ "SignalType" SG_ 1383 RwdFusTrkA7MeasStatus "ENM";
BA_ "SignalLongName" SG_ 1383 RwdFusTrkA7MeasStatus "Rearward Fusion Track A7 Measurement Status";
BA_ "VNSigAllNodes" SG_ 1383 RwdFusTrkA7MeasStatus 1;
BA_ "SignalType" SG_ 1383 RwdFusTrkA7ObjType "ENM";
BA_ "SignalLongName" SG_ 1383 RwdFusTrkA7ObjType "Rearward Fusion Track A7 Object Type";
BA_ "VNSigAllNodes" SG_ 1383 RwdFusTrkA7ObjType 1;
BA_ "SignalType" SG_ 1382 RwdFusTrkA6RollingCnt "UNM";
BA_ "SignalLongName" SG_ 1382 RwdFusTrkA6RollingCnt "Rearward Fusion Track A6 Rolling Count";
BA_ "VNSigAllNodes" SG_ 1382 RwdFusTrkA6RollingCnt 1;
BA_ "SignalType" SG_ 1382 RwdFusTrkA6ObjectID "UNM";
BA_ "SignalLongName" SG_ 1382 RwdFusTrkA6ObjectID "Rearward Fusion Track A6 Object ID";
BA_ "VNSigAllNodes" SG_ 1382 RwdFusTrkA6ObjectID 1;
BA_ "SignalType" SG_ 1382 RwdFusTrkA6MsgIndex "UNM";
BA_ "SignalLongName" SG_ 1382 RwdFusTrkA6MsgIndex "Rearward Fusion Track A6 Message Index";
BA_ "VNSigAllNodes" SG_ 1382 RwdFusTrkA6MsgIndex 1;
BA_ "SignalType" SG_ 1382 RwdFusTrkA6LongPos "SNM";
BA_ "SignalLongName" SG_ 1382 RwdFusTrkA6LongPos "Rearward Fusion Track A6 Longitudinal Position";
BA_ "VNSigAllNodes" SG_ 1382 RwdFusTrkA6LongPos 1;
BA_ "SignalType" SG_ 1382 RwdFusTrkA6RelLongVel "SNM";
BA_ "SignalLongName" SG_ 1382 RwdFusTrkA6RelLongVel "Rearward Fusion Track A6 Relative Longitudinal Velocity";
BA_ "VNSigAllNodes" SG_ 1382 RwdFusTrkA6RelLongVel 1;
BA_ "SignalType" SG_ 1382 RwdFusTrkA6Confidence "ENM";
BA_ "SignalLongName" SG_ 1382 RwdFusTrkA6Confidence "Rearward Fusion Track A6 Confidence";
BA_ "VNSigAllNodes" SG_ 1382 RwdFusTrkA6Confidence 1;
BA_ "SignalType" SG_ 1382 RwdFusTrkA6LatPos "SNM";
BA_ "SignalLongName" SG_ 1382 RwdFusTrkA6LatPos "Rearward Fusion Track A6 Lateral Position";
BA_ "VNSigAllNodes" SG_ 1382 RwdFusTrkA6LatPos 1;
BA_ "SignalType" SG_ 1382 RwdFusTrkA6RelLatVel "SNM";
BA_ "SignalLongName" SG_ 1382 RwdFusTrkA6RelLatVel "Rearward Fusion Track A6 Relative Lateral Velocity";
BA_ "VNSigAllNodes" SG_ 1382 RwdFusTrkA6RelLatVel 1;
BA_ "SignalType" SG_ 1382 RwdFusTrkA6MeasStatus "ENM";
BA_ "SignalLongName" SG_ 1382 RwdFusTrkA6MeasStatus "Rearward Fusion Track A6 Measurement Status";
BA_ "VNSigAllNodes" SG_ 1382 RwdFusTrkA6MeasStatus 1;
BA_ "SignalType" SG_ 1382 RwdFusTrkA6ObjType "ENM";
BA_ "SignalLongName" SG_ 1382 RwdFusTrkA6ObjType "Rearward Fusion Track A6 Object Type";
BA_ "VNSigAllNodes" SG_ 1382 RwdFusTrkA6ObjType 1;
BA_ "SignalType" SG_ 1381 RwdFusTrkA5RollingCnt "UNM";
BA_ "SignalLongName" SG_ 1381 RwdFusTrkA5RollingCnt "Rearward Fusion Track A5 Rolling Count";
BA_ "VNSigAllNodes" SG_ 1381 RwdFusTrkA5RollingCnt 1;
BA_ "SignalType" SG_ 1381 RwdFusTrkA5ObjectID "UNM";
BA_ "SignalLongName" SG_ 1381 RwdFusTrkA5ObjectID "Rearward Fusion Track A5 Object ID";
BA_ "VNSigAllNodes" SG_ 1381 RwdFusTrkA5ObjectID 1;
BA_ "SignalType" SG_ 1381 RwdFusTrkA5MsgIndex "UNM";
BA_ "SignalLongName" SG_ 1381 RwdFusTrkA5MsgIndex "Rearward Fusion Track A5 Message Index";
BA_ "VNSigAllNodes" SG_ 1381 RwdFusTrkA5MsgIndex 1;
BA_ "SignalType" SG_ 1381 RwdFusTrkA5LongPos "SNM";
BA_ "SignalLongName" SG_ 1381 RwdFusTrkA5LongPos "Rearward Fusion Track A5 Longitudinal Position";
BA_ "VNSigAllNodes" SG_ 1381 RwdFusTrkA5LongPos 1;
BA_ "SignalType" SG_ 1381 RwdFusTrkA5RelLongVel "SNM";
BA_ "SignalLongName" SG_ 1381 RwdFusTrkA5RelLongVel "Rearward Fusion Track A5 Relative Longitudinal Velocity";
BA_ "VNSigAllNodes" SG_ 1381 RwdFusTrkA5RelLongVel 1;
BA_ "SignalType" SG_ 1381 RwdFusTrkA5Confidence "ENM";
BA_ "SignalLongName" SG_ 1381 RwdFusTrkA5Confidence "Rearward Fusion Track A5 Confidence";
BA_ "VNSigAllNodes" SG_ 1381 RwdFusTrkA5Confidence 1;
BA_ "SignalType" SG_ 1381 RwdFusTrkA5LatPos "SNM";
BA_ "SignalLongName" SG_ 1381 RwdFusTrkA5LatPos "Rearward Fusion Track A5 Lateral Position";
BA_ "VNSigAllNodes" SG_ 1381 RwdFusTrkA5LatPos 1;
BA_ "SignalType" SG_ 1381 RwdFusTrkA5RelLatVel "SNM";
BA_ "SignalLongName" SG_ 1381 RwdFusTrkA5RelLatVel "Rearward Fusion Track A5 Relative Lateral Velocity";
BA_ "VNSigAllNodes" SG_ 1381 RwdFusTrkA5RelLatVel 1;
BA_ "SignalType" SG_ 1381 RwdFusTrkA5MeasStatus "ENM";
BA_ "SignalLongName" SG_ 1381 RwdFusTrkA5MeasStatus "Rearward Fusion Track A5 Measurement Status";
BA_ "VNSigAllNodes" SG_ 1381 RwdFusTrkA5MeasStatus 1;
BA_ "SignalType" SG_ 1381 RwdFusTrkA5ObjType "ENM";
BA_ "SignalLongName" SG_ 1381 RwdFusTrkA5ObjType "Rearward Fusion Track A5 Object Type";
BA_ "VNSigAllNodes" SG_ 1381 RwdFusTrkA5ObjType 1;
BA_ "SignalType" SG_ 768 SmgrMotRollAngle "SNM";
BA_ "SignalLongName" SG_ 768 SmgrMotRollAngle "Sensor Manager Motion Roll Angle";
BA_ "VNSigAllNodes" SG_ 768 SmgrMotRollAngle 1;
BA_ "SignalType" SG_ 768 SmgrMotRollAngleV "ENM";
BA_ "SignalLongName" SG_ 768 SmgrMotRollAngleV "Sensor Manager Motion Roll Angle Validity";
BA_ "VNSigAllNodes" SG_ 768 SmgrMotRollAngleV 1;
BA_ "SignalType" SG_ 768 SmgrMotChecksum "UNM";
BA_ "SignalLongName" SG_ 768 SmgrMotChecksum "Sensor Manager Motion Checksum";
BA_ "VNSigAllNodes" SG_ 768 SmgrMotChecksum 1;
BA_ "SignalType" SG_ 768 SmgrMotPitchAngle "SNM";
BA_ "SignalLongName" SG_ 768 SmgrMotPitchAngle "Sensor Manager Motion Pitch Angle";
BA_ "VNSigAllNodes" SG_ 768 SmgrMotPitchAngle 1;
BA_ "SignalType" SG_ 768 SmgrMotPitchAngleV "ENM";
BA_ "SignalLongName" SG_ 768 SmgrMotPitchAngleV "Sensor Manager Motion Pitch Angle Validity";
BA_ "VNSigAllNodes" SG_ 768 SmgrMotPitchAngleV 1;
BA_ "SignalType" SG_ 768 SmgrMotLongSpeedV "ENM";
BA_ "SignalLongName" SG_ 768 SmgrMotLongSpeedV "Sensor Manager Motion Longitudinal Speed Validity";
BA_ "VNSigAllNodes" SG_ 768 SmgrMotLongSpeedV 1;
BA_ "SignalType" SG_ 768 SmgrMotLongSpeed "SNM";
BA_ "SignalLongName" SG_ 768 SmgrMotLongSpeed "SensorManager Motion Longitudinal Speed";
BA_ "VNSigAllNodes" SG_ 768 SmgrMotLongSpeed 1;
BA_ "SignalType" SG_ 768 SmgrMotYawRate "SNM";
BA_ "SignalLongName" SG_ 768 SmgrMotYawRate "Sensor Manager Motion Yaw Rate";
BA_ "VNSigAllNodes" SG_ 768 SmgrMotYawRate 1;
BA_ "SignalType" SG_ 768 SmgrMotYawRateV "ENM";
BA_ "SignalLongName" SG_ 768 SmgrMotYawRateV "Sensor Manager Motion Yaw Rate Validity";
BA_ "VNSigAllNodes" SG_ 768 SmgrMotYawRateV 1;
BA_ "SignalType" SG_ 768 SmgrMotRollingCnt "UNM";
BA_ "SignalLongName" SG_ 768 SmgrMotRollingCnt "Sensor Manager Motion Rolling Count";
BA_ "VNSigAllNodes" SG_ 768 SmgrMotRollingCnt 1;
BA_ "VNSigSLHSSharedDiagnostic" SG_ 1350 DgnInf_OBJ546 1;
BA_ "SignalType" SG_ 1350 DgnInf_OBJ546 "UNM";
BA_ "SignalLongName" SG_ 1350 DgnInf_OBJ546 "Diagnostic Information OBJ546";
BA_ "VNSigAllNodes" SG_ 1350 DgnInf_OBJ546 1;
BA_ "VNSigSLHSSharedDiagnostic" SG_ 1369 DgnInf_OBJ544 1;
BA_ "SignalType" SG_ 1369 DgnInf_OBJ544 "UNM";
BA_ "SignalLongName" SG_ 1369 DgnInf_OBJ544 "Diagnostic Information OBJ544";
BA_ "VNSigAllNodes" SG_ 1369 DgnInf_OBJ544 1;
BA_ "VNSigSLHSSharedDiagnostic" SG_ 1347 DgnInf_OBJ543 1;
BA_ "SignalType" SG_ 1347 DgnInf_OBJ543 "UNM";
BA_ "SignalLongName" SG_ 1347 DgnInf_OBJ543 "Diagnostic Information OBJ543";
BA_ "VNSigAllNodes" SG_ 1347 DgnInf_OBJ543 1;
BA_ "VNSigSLHSSharedDiagnostic" SG_ 1346 DgnInf_OBJ542 1;
BA_ "SignalType" SG_ 1346 DgnInf_OBJ542 "UNM";
BA_ "SignalLongName" SG_ 1346 DgnInf_OBJ542 "Diagnostic Information OBJ542";
BA_ "VNSigAllNodes" SG_ 1346 DgnInf_OBJ542 1;
BA_ "VNSigSLHSSharedDiagnostic" SG_ 1345 DgnInf_OBJ541 1;
BA_ "SignalType" SG_ 1345 DgnInf_OBJ541 "UNM";
BA_ "SignalLongName" SG_ 1345 DgnInf_OBJ541 "Diagnostic Information OBJ541";
BA_ "VNSigAllNodes" SG_ 1345 DgnInf_OBJ541 1;
BA_ "VNSigSLHSSharedDiagnostic" SG_ 579 DgnInf 1;
BA_ "SignalType" SG_ 579 DgnInf "UNM";
BA_ "SignalLongName" SG_ 579 DgnInf "Diagnostic Information";
BA_ "VNSigAllNodes" SG_ 579 DgnInf 1;
BA_ "VNSigSLHSSharedDiagnostic" SG_ 577 DgnInf 1;
BA_ "SignalType" SG_ 577 DgnInf "UNM";
BA_ "SignalLongName" SG_ 577 DgnInf "Diagnostic Information";
BA_ "VNSigAllNodes" SG_ 577 DgnInf 1;
BA_ "VNSigSLHSSharedDiagnostic" SG_ 578 DgnInf 1;
BA_ "SignalType" SG_ 578 DgnInf "UNM";
BA_ "SignalLongName" SG_ 578 DgnInf "Diagnostic Information";
BA_ "VNSigAllNodes" SG_ 578 DgnInf 1;
BA_ "VNSigSLHSSharedDiagnostic" SG_ 582 DgnInf 1;
BA_ "SignalType" SG_ 582 DgnInf "UNM";
BA_ "SignalLongName" SG_ 582 DgnInf "Diagnostic Information";
BA_ "VNSigAllNodes" SG_ 582 DgnInf 1;
BA_ "VNSigSLHSSharedDiagnostic" SG_ 601 DgnInf 1;
BA_ "SignalType" SG_ 601 DgnInf "UNM";
BA_ "SignalLongName" SG_ 601 DgnInf "Diagnostic Information";
BA_ "VNSigAllNodes" SG_ 601 DgnInf 1;
BA_ "VNSigSLHSSharedDiagnostic" SG_ 1355 DgnInf_OBJ54B 1;
BA_ "SignalType" SG_ 1355 DgnInf_OBJ54B "UNM";
BA_ "SignalLongName" SG_ 1355 DgnInf_OBJ54B "Diagnostic Information OBJ54B";
BA_ "VNSigAllNodes" SG_ 1355 DgnInf_OBJ54B 1;
BA_ "VNSigSLHSSharedDiagnostic" SG_ 587 DgnInf 1;
BA_ "SignalType" SG_ 587 DgnInf "UNM";
BA_ "SignalLongName" SG_ 587 DgnInf "Diagnostic Information";
BA_ "VNSigAllNodes" SG_ 587 DgnInf 1;
BA_ "SignalType" SG_ 784 SysPwrMdV "ENM";
BA_ "SignalLongName" SG_ 784 SysPwrMdV "System Power Mode Validity";
BA_ "VNSigAllNodes" SG_ 784 SysPwrMdV 1;
BA_ "GenSigSendType" SG_ 784 SysPwrMd 10;
BA_ "SignalType" SG_ 784 SysPwrMd "ENM";
BA_ "SignalLongName" SG_ 784 SysPwrMd "System Power Mode";
BA_ "VNSigAllNodes" SG_ 784 SysPwrMd 1;
BA_ "SignalType" SG_ 784 WSWprAct "BLN";
BA_ "SignalLongName" SG_ 784 WSWprAct "Windshield Wiper Active";
BA_ "VNSigAllNodes" SG_ 784 WSWprAct 1;
BA_ "SignalType" SG_ 784 RtLwBmFld "BLN";
BA_ "SignalLongName" SG_ 784 RtLwBmFld "Right Low Beam Failed";
BA_ "VNSigAllNodes" SG_ 784 RtLwBmFld 1;
BA_ "SignalType" SG_ 784 OtsdAmbtLtLvlStatV "ENM";
BA_ "SignalLongName" SG_ 784 OtsdAmbtLtLvlStatV "Outside Ambient Light Level Status Validity";
BA_ "VNSigAllNodes" SG_ 784 OtsdAmbtLtLvlStatV 1;
BA_ "SignalType" SG_ 784 OtsdAmbtLtLvlStat "ENM";
BA_ "SignalLongName" SG_ 784 OtsdAmbtLtLvlStat "Outside Ambient Light Level Status";
BA_ "VNSigAllNodes" SG_ 784 OtsdAmbtLtLvlStat 1;
BA_ "SignalType" SG_ 784 LowBmAct "BLN";
BA_ "SignalLongName" SG_ 784 LowBmAct "Low Beam Active";
BA_ "VNSigAllNodes" SG_ 784 LowBmAct 1;
BA_ "SignalType" SG_ 784 LftLwBmFld "BLN";
BA_ "SignalLongName" SG_ 784 LftLwBmFld "Left Low Beam Failed";
BA_ "VNSigAllNodes" SG_ 784 LftLwBmFld 1;
BA_ "SignalType" SG_ 784 HighBmAct "BLN";
BA_ "SignalLongName" SG_ 784 HighBmAct "High Beam Active";
BA_ "VNSigAllNodes" SG_ 784 HighBmAct 1;
BA_ "GenSigSendType" SG_ 1539 RFSRRYear 10;
BA_ "SignalType" SG_ 1539 RFSRRYear "ASC";
BA_ "SignalLongName" SG_ 1539 RFSRRYear "Right Front Short Range Radar Year";
BA_ "VNSigAllNodes" SG_ 1539 RFSRRYear 1;
BA_ "GenSigSendType" SG_ 1539 RFSRRSerialNmbr 10;
BA_ "SignalType" SG_ 1539 RFSRRSerialNmbr "ASC";
BA_ "SignalLongName" SG_ 1539 RFSRRSerialNmbr "Right Front Short Range Radar Serial Number";
BA_ "VNSigAllNodes" SG_ 1539 RFSRRSerialNmbr 1;
BA_ "GenSigSendType" SG_ 1539 RFSRRJulianDate 10;
BA_ "SignalType" SG_ 1539 RFSRRJulianDate "ASC";
BA_ "SignalLongName" SG_ 1539 RFSRRJulianDate "Right Front Short Range Radar Julian Date";
BA_ "VNSigAllNodes" SG_ 1539 RFSRRJulianDate 1;
BA_ "SignalType" SG_ 776 Vpath_Data2ModeInfo "ENM";
BA_ "SignalLongName" SG_ 776 Vpath_Data2ModeInfo "Vehicle Path Data 2 Mode Information";
BA_ "VNSigAllNodes" SG_ 776 Vpath_Data2ModeInfo 1;
BA_ "SignalType" SG_ 776 Vpath2_Checksum "UNM";
BA_ "SignalLongName" SG_ 776 Vpath2_Checksum "Vehicle Path Data 2 Checksum";
BA_ "VNSigAllNodes" SG_ 776 Vpath2_Checksum 1;
BA_ "SignalType" SG_ 776 Vpath_Data2RollCnt "UNM";
BA_ "SignalLongName" SG_ 776 Vpath_Data2RollCnt "Vehicle Path Data 2 Rolling Count";
BA_ "VNSigAllNodes" SG_ 776 Vpath_Data2RollCnt 1;
BA_ "SignalType" SG_ 776 Vpath_Data2YawRateV "ENM";
BA_ "SignalLongName" SG_ 776 Vpath_Data2YawRateV "Vehicle Path Data 2 Yaw Rate Validity";
BA_ "VNSigAllNodes" SG_ 776 Vpath_Data2YawRateV 1;
BA_ "SignalType" SG_ 776 Vpath_Data2LongVelV "ENM";
BA_ "SignalLongName" SG_ 776 Vpath_Data2LongVelV "Vehicle Path Data 2 Longitudinal Velocity Validity";
BA_ "VNSigAllNodes" SG_ 776 Vpath_Data2LongVelV 1;
BA_ "SignalType" SG_ 776 Vpath_Data2LatVelV "ENM";
BA_ "SignalLongName" SG_ 776 Vpath_Data2LatVelV "Vehicle Path Data 2 Lateral Velocity Validity";
BA_ "VNSigAllNodes" SG_ 776 Vpath_Data2LatVelV 1;
BA_ "SignalType" SG_ 776 Vpath_Data2TravlDirctn "ENM";
BA_ "SignalLongName" SG_ 776 Vpath_Data2TravlDirctn "Vehicle Path Data 2 Travel Direction";
BA_ "VNSigAllNodes" SG_ 776 Vpath_Data2TravlDirctn 1;
BA_ "SignalType" SG_ 776 Vpath_Data2LongVel "SNM";
BA_ "SignalLongName" SG_ 776 Vpath_Data2LongVel "Vehicle Path Data 2 Longitudinal Velocity";
BA_ "VNSigAllNodes" SG_ 776 Vpath_Data2LongVel 1;
BA_ "SignalType" SG_ 776 Vpath_Data2YawRate "SNM";
BA_ "SignalLongName" SG_ 776 Vpath_Data2YawRate "Vehicle Path Data 2 Yaw Rate";
BA_ "VNSigAllNodes" SG_ 776 Vpath_Data2YawRate 1;
BA_ "SignalType" SG_ 776 Vpath_Data2LatVel "SNM";
BA_ "SignalLongName" SG_ 776 Vpath_Data2LatVel "Vehicle Path Data 2 Lateral Velocity";
BA_ "VNSigAllNodes" SG_ 776 Vpath_Data2LatVel 1;
BA_ "SignalType" SG_ 161 FTimeSyncMstrChksm "UNM";
BA_ "SignalLongName" SG_ 161 FTimeSyncMstrChksm "Front Time Sync Master Clock Checksum";
BA_ "VNSigAllNodes" SG_ 161 FTimeSyncMstrChksm 1;
BA_ "SignalType" SG_ 161 FTimeSyncMstrClock "UNM";
BA_ "SignalLongName" SG_ 161 FTimeSyncMstrClock "Front Time Sync Master Clock";
BA_ "VNSigAllNodes" SG_ 161 FTimeSyncMstrClock 1;
BA_ "SignalType" SG_ 161 SensorModeCmdLRR "ENM";
BA_ "SignalLongName" SG_ 161 SensorModeCmdLRR "Front Long Range Sensor Mode Command";
BA_ "VNSigAllNodes" SG_ 161 SensorModeCmdLRR 1;
BA_ "SignalType" SG_ 161 SensorModeCmdSRR "ENM";
BA_ "SignalLongName" SG_ 161 SensorModeCmdSRR "Sensor Mode Command Short Range Radar";
BA_ "VNSigAllNodes" SG_ 161 SensorModeCmdSRR 1;
BA_ "SignalType" SG_ 161 SensorModeCmdFCamera "ENM";
BA_ "SignalLongName" SG_ 161 SensorModeCmdFCamera "Sensor Mode Command Front Camera";
BA_ "VNSigAllNodes" SG_ 161 SensorModeCmdFCamera 1;
BA_ "SignalType" SG_ 161 FTimeSyncMstrClockV "ENM";
BA_ "SignalLongName" SG_ 161 FTimeSyncMstrClockV "Front Time Sync Master Clock Validity";
BA_ "VNSigAllNodes" SG_ 161 FTimeSyncMstrClockV 1;
BA_ "SignalType" SG_ 774 Vpath_RollingCount "UNM";
BA_ "SignalLongName" SG_ 774 Vpath_RollingCount "Vehicle Path Rolling Count";
BA_ "VNSigAllNodes" SG_ 774 Vpath_RollingCount 1;
BA_ "SignalType" SG_ 774 Vpath_TrnCtrLngOfstV "ENM";
BA_ "SignalLongName" SG_ 774 Vpath_TrnCtrLngOfstV "Vehicle Path Turn Center Longitudinal Offset Validity";
BA_ "VNSigAllNodes" SG_ 774 Vpath_TrnCtrLngOfstV 1;
BA_ "SignalType" SG_ 774 Vpath_Checksum "UNM";
BA_ "SignalLongName" SG_ 774 Vpath_Checksum "Vehicle Path Checksum";
BA_ "VNSigAllNodes" SG_ 774 Vpath_Checksum 1;
BA_ "SignalType" SG_ 774 Vpath_TrnCtrLngOfst "SNM";
BA_ "SignalLongName" SG_ 774 Vpath_TrnCtrLngOfst "Vehicle Path Turn Center Longitudinal Offset";
BA_ "VNSigAllNodes" SG_ 774 Vpath_TrnCtrLngOfst 1;
BA_ "SignalType" SG_ 774 Vpath_TrnCtrLatOfst "SNM";
BA_ "SignalLongName" SG_ 774 Vpath_TrnCtrLatOfst "Vehcile Path Turn Center Lateral Offset";
BA_ "VNSigAllNodes" SG_ 774 Vpath_TrnCtrLatOfst 1;
BA_ "SignalType" SG_ 774 Vpath_Curvature "SNM";
BA_ "SignalLongName" SG_ 774 Vpath_Curvature "Vehicle Path Curvature";
BA_ "VNSigAllNodes" SG_ 774 Vpath_Curvature 1;
BA_ "SignalType" SG_ 774 Vpath_CurvatureV "ENM";
BA_ "SignalLongName" SG_ 774 Vpath_CurvatureV "Vehicle Path Curvature Validity";
BA_ "VNSigAllNodes" SG_ 774 Vpath_CurvatureV 1;
BA_ "SignalType" SG_ 848 LnSnsLnChngStatus "ENM";
BA_ "SignalLongName" SG_ 848 LnSnsLnChngStatus "Lane Sense Lane Change Status";
BA_ "VNSigAllNodes" SG_ 848 LnSnsLnChngStatus 1;
BA_ "SignalType" SG_ 848 LnSnsBurstChecksum "UNM";
BA_ "SignalLongName" SG_ 848 LnSnsBurstChecksum "Lane Sense Burst Checksum";
BA_ "VNSigAllNodes" SG_ 848 LnSnsBurstChecksum 1;
BA_ "SignalType" SG_ 848 LaneSenseRollingCount "UNM";
BA_ "SignalLongName" SG_ 848 LaneSenseRollingCount "Lane Sense Rolling Count";
BA_ "VNSigAllNodes" SG_ 848 LaneSenseRollingCount 1;
BA_ "SignalType" SG_ 848 LaneSenseSystemOK "BLN";
BA_ "SignalLongName" SG_ 848 LaneSenseSystemOK "Lane Sense System OK";
BA_ "VNSigAllNodes" SG_ 848 LaneSenseSystemOK 1;
BA_ "SignalType" SG_ 848 LaneSnsLLnPosValid "ENM";
BA_ "SignalLongName" SG_ 848 LaneSnsLLnPosValid "Lane Sense Left Lane Position Valid";
BA_ "VNSigAllNodes" SG_ 848 LaneSnsLLnPosValid 1;
BA_ "SignalType" SG_ 848 LnSenseDistToLLnEdge "UNM";
BA_ "SignalLongName" SG_ 848 LnSenseDistToLLnEdge "Lane Sense Distance to Left Lane Edge";
BA_ "VNSigAllNodes" SG_ 848 LnSenseDistToLLnEdge 1;
BA_ "SignalType" SG_ 848 LnSnsRLnPosValid "ENM";
BA_ "SignalLongName" SG_ 848 LnSnsRLnPosValid "Lane Sense Right Lane Position Valid";
BA_ "VNSigAllNodes" SG_ 848 LnSnsRLnPosValid 1;
BA_ "SignalType" SG_ 848 LnSnsDistToRLnEdge "UNM";
BA_ "SignalLongName" SG_ 848 LnSnsDistToRLnEdge "Lane Sense Distance to Right Lane Edge";
BA_ "VNSigAllNodes" SG_ 848 LnSnsDistToRLnEdge 1;
BA_ "SignalType" SG_ 848 LaneSenseTimeStampV "ENM";
BA_ "SignalLongName" SG_ 848 LaneSenseTimeStampV "Lane Sense Data Time Stamp Validity";
BA_ "VNSigAllNodes" SG_ 848 LaneSenseTimeStampV 1;
BA_ "SignalType" SG_ 848 LaneSenseTimeStamp "UNM";
BA_ "SignalLongName" SG_ 848 LaneSenseTimeStamp "Lane Sense Data Time Stamp";
BA_ "VNSigAllNodes" SG_ 848 LaneSenseTimeStamp 1;
BA_ "SignalType" SG_ 848 LaneSenseSystemOKV "ENM";
BA_ "SignalLongName" SG_ 848 LaneSenseSystemOKV "Lane Sense System OK Validity";
BA_ "VNSigAllNodes" SG_ 848 LaneSenseSystemOKV 1;
BA_ "SignalType" SG_ 848 LnSnsTngtOfHdngLnRtV "ENM";
BA_ "SignalLongName" SG_ 848 LnSnsTngtOfHdngLnRtV "Lane Sense Tangent Of Heading In Lane Right Validity";
BA_ "VNSigAllNodes" SG_ 848 LnSnsTngtOfHdngLnRtV 1;
BA_ "SignalType" SG_ 848 LnSnsTngtOfHdngLnRt "SNM";
BA_ "SignalLongName" SG_ 848 LnSnsTngtOfHdngLnRt "Lane Sense Tangent Of Heading In Lane Right";
BA_ "VNSigAllNodes" SG_ 848 LnSnsTngtOfHdngLnRt 1;
BA_REL_ "GenSigSuprvResp" BU_SG_REL_ VIS_FO SG_ 1362 FObjConfCPSTrkObjectIDB 1;
BA_REL_ "GenSigTimeoutMsg" BU_SG_REL_ VIS_FO SG_ 1362 FObjConfCPSTrkObjectIDB 1362;
BA_REL_ "GenSigTimeoutTime" BU_SG_REL_ VIS_FO SG_ 1362 FObjConfCPSTrkObjectIDB 250;
BA_REL_ "GenSigSuprvResp" BU_SG_REL_ VIS_FO SG_ 1362 FObjConfCPSTrkObjectIDB 1;
BA_REL_ "GenSigTimeoutMsg" BU_SG_REL_ VIS_FO SG_ 1362 FObjConfCPSTrkObjectIDB 1362;
BA_REL_ "GenSigTimeoutTime" BU_SG_REL_ VIS_FO SG_ 1362 FObjConfCPSTrkObjectIDB 250;
BA_REL_ "GenSigSuprvResp" BU_SG_REL_ VIS_FO SG_ 1362 CPSVisConfLonPos1 1;
BA_REL_ "GenSigTimeoutMsg" BU_SG_REL_ VIS_FO SG_ 1362 CPSVisConfLonPos1 1362;
BA_REL_ "GenSigTimeoutTime" BU_SG_REL_ VIS_FO SG_ 1362 CPSVisConfLonPos1 250;
BA_REL_ "GenSigSuprvResp" BU_SG_REL_ VIS_FO SG_ 1362 CPSVisConfLatPos1 1;
BA_REL_ "GenSigTimeoutMsg" BU_SG_REL_ VIS_FO SG_ 1362 CPSVisConfLatPos1 1362;
BA_REL_ "GenSigTimeoutTime" BU_SG_REL_ VIS_FO SG_ 1362 CPSVisConfLatPos1 250;
BA_REL_ "GenSigSuprvResp" BU_SG_REL_ VIS_FO SG_ 1362 CPSVisConfChecksum 1;
BA_REL_ "GenSigTimeoutMsg" BU_SG_REL_ VIS_FO SG_ 1362 CPSVisConfChecksum 1362;
BA_REL_ "GenSigTimeoutTime" BU_SG_REL_ VIS_FO SG_ 1362 CPSVisConfChecksum 250;
BA_REL_ "GenSigSuprvResp" BU_SG_REL_ VIS_FO SG_ 1362 FObjConfCPSTrkRangeRate 1;
BA_REL_ "GenSigTimeoutMsg" BU_SG_REL_ VIS_FO SG_ 1362 FObjConfCPSTrkRangeRate 1362;
BA_REL_ "GenSigTimeoutTime" BU_SG_REL_ VIS_FO SG_ 1362 FObjConfCPSTrkRangeRate 250;
BA_REL_ "GenSigSuprvResp" BU_SG_REL_ VIS_FO SG_ 1362 CPSConfTimeStamp 1;
BA_REL_ "GenSigTimeoutMsg" BU_SG_REL_ VIS_FO SG_ 1362 CPSConfTimeStamp 1362;
BA_REL_ "GenSigTimeoutTime" BU_SG_REL_ VIS_FO SG_ 1362 CPSConfTimeStamp 250;
BA_REL_ "GenSigSuprvResp" BU_SG_REL_ VIS_FO SG_ 1362 FObjConfCPSRollingTrkCnt 1;
BA_REL_ "GenSigTimeoutMsg" BU_SG_REL_ VIS_FO SG_ 1362 FObjConfCPSRollingTrkCnt 1362;
BA_REL_ "GenSigTimeoutTime" BU_SG_REL_ VIS_FO SG_ 1362 FObjConfCPSRollingTrkCnt 250;
BA_REL_ "GenSigSuprvResp" BU_SG_REL_ VIS_FO SG_ 768 SmgrMotRollAngle 1;
BA_REL_ "GenSigTimeoutTime" BU_SG_REL_ VIS_FO SG_ 768 SmgrMotRollAngle 120;
BA_REL_ "GenSigSuprvResp" BU_SG_REL_ VIS_FO SG_ 768 SmgrMotChecksum 1;
BA_REL_ "GenSigTimeoutTime" BU_SG_REL_ VIS_FO SG_ 768 SmgrMotChecksum 120;
BA_REL_ "GenSigSuprvResp" BU_SG_REL_ VIS_FO SG_ 768 SmgrMotPitchAngle 1;
BA_REL_ "GenSigTimeoutTime" BU_SG_REL_ VIS_FO SG_ 768 SmgrMotPitchAngle 120;
BA_REL_ "GenSigSuprvResp" BU_SG_REL_ VIS_FO SG_ 768 SmgrMotLongSpeed 1;
BA_REL_ "GenSigTimeoutTime" BU_SG_REL_ VIS_FO SG_ 768 SmgrMotLongSpeed 120;
BA_REL_ "GenSigSuprvResp" BU_SG_REL_ VIS_FO SG_ 768 SmgrMotYawRate 1;
BA_REL_ "GenSigTimeoutTime" BU_SG_REL_ VIS_FO SG_ 768 SmgrMotYawRate 120;
BA_REL_ "GenSigSuprvResp" BU_SG_REL_ VIS_FO SG_ 768 SmgrMotRollingCnt 1;
BA_REL_ "GenSigTimeoutTime" BU_SG_REL_ VIS_FO SG_ 768 SmgrMotRollingCnt 120;
BA_REL_ "GenSigSuprvResp" BU_SG_REL_ VIS_FO SG_ 784 SysPwrMd 1;
BA_REL_ "GenSigTimeoutMsg" BU_SG_REL_ VIS_FO SG_ 784 SysPwrMd 784;
BA_REL_ "GenSigTimeoutTime" BU_SG_REL_ VIS_FO SG_ 784 SysPwrMd 250;
BA_REL_ "GenSigSuprvResp" BU_SG_REL_ LRR_FO SG_ 784 SysPwrMd 1;
BA_REL_ "GenSigTimeoutMsg" BU_SG_REL_ LRR_FO SG_ 784 SysPwrMd 784;
BA_REL_ "GenSigTimeoutTime" BU_SG_REL_ LRR_FO SG_ 784 SysPwrMd 250;
BA_REL_ "GenSigSuprvResp" BU_SG_REL_ VIS_FO SG_ 784 WSWprAct 1;
BA_REL_ "GenSigTimeoutMsg" BU_SG_REL_ VIS_FO SG_ 784 WSWprAct 784;
BA_REL_ "GenSigTimeoutTime" BU_SG_REL_ VIS_FO SG_ 784 WSWprAct 250;
BA_REL_ "GenSigSuprvResp" BU_SG_REL_ VIS_FO SG_ 784 OtsdAmbtLtLvlStat 1;
BA_REL_ "GenSigTimeoutMsg" BU_SG_REL_ VIS_FO SG_ 784 OtsdAmbtLtLvlStat 784;
BA_REL_ "GenSigTimeoutTime" BU_SG_REL_ VIS_FO SG_ 784 OtsdAmbtLtLvlStat 250;
BA_REL_ "GenSigSuprvResp" BU_SG_REL_ EOCM_F_FO SG_ 1539 RFSRRYear 1;
BA_REL_ "GenSigTimeoutTime" BU_SG_REL_ EOCM_F_FO SG_ 1539 RFSRRYear 120;
BA_REL_ "GenSigSuprvResp" BU_SG_REL_ EOCM_F_FO SG_ 1539 RFSRRSerialNmbr 1;
BA_REL_ "GenSigTimeoutTime" BU_SG_REL_ EOCM_F_FO SG_ 1539 RFSRRSerialNmbr 120;
BA_REL_ "GenSigSuprvResp" BU_SG_REL_ EOCM_F_FO SG_ 1539 RFSRRJulianDate 1;
BA_REL_ "GenSigTimeoutTime" BU_SG_REL_ EOCM_F_FO SG_ 1539 RFSRRJulianDate 120;
BA_REL_ "GenSigSuprvResp" BU_SG_REL_ VIS_FO SG_ 776 Vpath_Data2ModeInfo 1;
BA_REL_ "GenSigTimeoutTime" BU_SG_REL_ VIS_FO SG_ 776 Vpath_Data2ModeInfo 120;
BA_REL_ "GenSigSuprvResp" BU_SG_REL_ RSRR_FO SG_ 776 Vpath_Data2ModeInfo 1;
BA_REL_ "GenSigTimeoutTime" BU_SG_REL_ RSRR_FO SG_ 776 Vpath_Data2ModeInfo 250;
BA_REL_ "GenSigSuprvResp" BU_SG_REL_ RSRR_FO SG_ 776 Vpath_Data2ModeInfo 1;
BA_REL_ "GenSigTimeoutTime" BU_SG_REL_ RSRR_FO SG_ 776 Vpath_Data2ModeInfo 250;
BA_REL_ "GenSigSuprvResp" BU_SG_REL_ RFSRR_FO SG_ 776 Vpath_Data2ModeInfo 1;
BA_REL_ "GenSigTimeoutTime" BU_SG_REL_ RFSRR_FO SG_ 776 Vpath_Data2ModeInfo 250;
BA_REL_ "GenSigSuprvResp" BU_SG_REL_ RFSRR_FO SG_ 776 Vpath_Data2ModeInfo 1;
BA_REL_ "GenSigTimeoutTime" BU_SG_REL_ RFSRR_FO SG_ 776 Vpath_Data2ModeInfo 250;
BA_REL_ "GenSigSuprvResp" BU_SG_REL_ LRR_FO SG_ 776 Vpath_Data2ModeInfo 1;
BA_REL_ "GenSigTimeoutMsg" BU_SG_REL_ LRR_FO SG_ 776 Vpath_Data2ModeInfo 776;
BA_REL_ "GenSigTimeoutTime" BU_SG_REL_ LRR_FO SG_ 776 Vpath_Data2ModeInfo 120;
BA_REL_ "GenSigSuprvResp" BU_SG_REL_ LFSRR_FO SG_ 776 Vpath_Data2ModeInfo 1;
BA_REL_ "GenSigTimeoutTime" BU_SG_REL_ LFSRR_FO SG_ 776 Vpath_Data2ModeInfo 250;
BA_REL_ "GenSigSuprvResp" BU_SG_REL_ LFSRR_FO SG_ 776 Vpath_Data2ModeInfo 1;
BA_REL_ "GenSigTimeoutTime" BU_SG_REL_ LFSRR_FO SG_ 776 Vpath_Data2ModeInfo 250;
BA_REL_ "GenSigSuprvResp" BU_SG_REL_ VIS_FO SG_ 776 Vpath2_Checksum 1;
BA_REL_ "GenSigTimeoutMsg" BU_SG_REL_ VIS_FO SG_ 776 Vpath2_Checksum 776;
BA_REL_ "GenSigTimeoutTime" BU_SG_REL_ VIS_FO SG_ 776 Vpath2_Checksum 120;
BA_REL_ "GenSigSuprvResp" BU_SG_REL_ RFSRR_FO SG_ 776 Vpath2_Checksum 1;
BA_REL_ "GenSigTimeoutTime" BU_SG_REL_ RFSRR_FO SG_ 776 Vpath2_Checksum 250;
BA_REL_ "GenSigSuprvResp" BU_SG_REL_ LFSRR_FO SG_ 776 Vpath2_Checksum 1;
BA_REL_ "GenSigTimeoutTime" BU_SG_REL_ LFSRR_FO SG_ 776 Vpath2_Checksum 250;
BA_REL_ "GenSigSuprvResp" BU_SG_REL_ RSRR_FO SG_ 776 Vpath2_Checksum 1;
BA_REL_ "GenSigTimeoutTime" BU_SG_REL_ RSRR_FO SG_ 776 Vpath2_Checksum 250;
BA_REL_ "GenSigSuprvResp" BU_SG_REL_ LRR_FO SG_ 776 Vpath2_Checksum 1;
BA_REL_ "GenSigTimeoutMsg" BU_SG_REL_ LRR_FO SG_ 776 Vpath2_Checksum 776;
BA_REL_ "GenSigTimeoutTime" BU_SG_REL_ LRR_FO SG_ 776 Vpath2_Checksum 120;
BA_REL_ "GenSigSuprvResp" BU_SG_REL_ VIS_FO SG_ 776 Vpath_Data2RollCnt 1;
BA_REL_ "GenSigTimeoutTime" BU_SG_REL_ VIS_FO SG_ 776 Vpath_Data2RollCnt 120;
BA_REL_ "GenSigSuprvResp" BU_SG_REL_ RSRR_FO SG_ 776 Vpath_Data2RollCnt 1;
BA_REL_ "GenSigTimeoutTime" BU_SG_REL_ RSRR_FO SG_ 776 Vpath_Data2RollCnt 250;
BA_REL_ "GenSigSuprvResp" BU_SG_REL_ RSRR_FO SG_ 776 Vpath_Data2RollCnt 1;
BA_REL_ "GenSigTimeoutTime" BU_SG_REL_ RSRR_FO SG_ 776 Vpath_Data2RollCnt 250;
BA_REL_ "GenSigSuprvResp" BU_SG_REL_ RFSRR_FO SG_ 776 Vpath_Data2RollCnt 1;
BA_REL_ "GenSigTimeoutTime" BU_SG_REL_ RFSRR_FO SG_ 776 Vpath_Data2RollCnt 250;
BA_REL_ "GenSigSuprvResp" BU_SG_REL_ RFSRR_FO SG_ 776 Vpath_Data2RollCnt 1;
BA_REL_ "GenSigTimeoutTime" BU_SG_REL_ RFSRR_FO SG_ 776 Vpath_Data2RollCnt 250;
BA_REL_ "GenSigSuprvResp" BU_SG_REL_ LRR_FO SG_ 776 Vpath_Data2RollCnt 1;
BA_REL_ "GenSigTimeoutMsg" BU_SG_REL_ LRR_FO SG_ 776 Vpath_Data2RollCnt 776;
BA_REL_ "GenSigTimeoutTime" BU_SG_REL_ LRR_FO SG_ 776 Vpath_Data2RollCnt 120;
BA_REL_ "GenSigSuprvResp" BU_SG_REL_ LRR_FO SG_ 776 Vpath_Data2RollCnt 1;
BA_REL_ "GenSigTimeoutMsg" BU_SG_REL_ LRR_FO SG_ 776 Vpath_Data2RollCnt 776;
BA_REL_ "GenSigTimeoutTime" BU_SG_REL_ LRR_FO SG_ 776 Vpath_Data2RollCnt 120;
BA_REL_ "GenSigSuprvResp" BU_SG_REL_ LFSRR_FO SG_ 776 Vpath_Data2RollCnt 1;
BA_REL_ "GenSigTimeoutTime" BU_SG_REL_ LFSRR_FO SG_ 776 Vpath_Data2RollCnt 250;
BA_REL_ "GenSigSuprvResp" BU_SG_REL_ LFSRR_FO SG_ 776 Vpath_Data2RollCnt 1;
BA_REL_ "GenSigTimeoutTime" BU_SG_REL_ LFSRR_FO SG_ 776 Vpath_Data2RollCnt 250;
BA_REL_ "GenSigSuprvResp" BU_SG_REL_ VIS_FO SG_ 776 Vpath_Data2TravlDirctn 1;
BA_REL_ "GenSigTimeoutTime" BU_SG_REL_ VIS_FO SG_ 776 Vpath_Data2TravlDirctn 120;
BA_REL_ "GenSigSuprvResp" BU_SG_REL_ RSRR_FO SG_ 776 Vpath_Data2TravlDirctn 1;
BA_REL_ "GenSigTimeoutTime" BU_SG_REL_ RSRR_FO SG_ 776 Vpath_Data2TravlDirctn 250;
BA_REL_ "GenSigSuprvResp" BU_SG_REL_ RSRR_FO SG_ 776 Vpath_Data2TravlDirctn 1;
BA_REL_ "GenSigTimeoutTime" BU_SG_REL_ RSRR_FO SG_ 776 Vpath_Data2TravlDirctn 250;
BA_REL_ "GenSigSuprvResp" BU_SG_REL_ RFSRR_FO SG_ 776 Vpath_Data2TravlDirctn 1;
BA_REL_ "GenSigTimeoutTime" BU_SG_REL_ RFSRR_FO SG_ 776 Vpath_Data2TravlDirctn 250;
BA_REL_ "GenSigSuprvResp" BU_SG_REL_ RFSRR_FO SG_ 776 Vpath_Data2TravlDirctn 1;
BA_REL_ "GenSigTimeoutTime" BU_SG_REL_ RFSRR_FO SG_ 776 Vpath_Data2TravlDirctn 250;
BA_REL_ "GenSigSuprvResp" BU_SG_REL_ LRR_FO SG_ 776 Vpath_Data2TravlDirctn 1;
BA_REL_ "GenSigTimeoutMsg" BU_SG_REL_ LRR_FO SG_ 776 Vpath_Data2TravlDirctn 776;
BA_REL_ "GenSigTimeoutTime" BU_SG_REL_ LRR_FO SG_ 776 Vpath_Data2TravlDirctn 120;
BA_REL_ "GenSigSuprvResp" BU_SG_REL_ LRR_FO SG_ 776 Vpath_Data2TravlDirctn 1;
BA_REL_ "GenSigTimeoutMsg" BU_SG_REL_ LRR_FO SG_ 776 Vpath_Data2TravlDirctn 776;
BA_REL_ "GenSigTimeoutTime" BU_SG_REL_ LRR_FO SG_ 776 Vpath_Data2TravlDirctn 120;
BA_REL_ "GenSigSuprvResp" BU_SG_REL_ LFSRR_FO SG_ 776 Vpath_Data2TravlDirctn 1;
BA_REL_ "GenSigTimeoutTime" BU_SG_REL_ LFSRR_FO SG_ 776 Vpath_Data2TravlDirctn 250;
BA_REL_ "GenSigSuprvResp" BU_SG_REL_ LFSRR_FO SG_ 776 Vpath_Data2TravlDirctn 1;
BA_REL_ "GenSigTimeoutTime" BU_SG_REL_ LFSRR_FO SG_ 776 Vpath_Data2TravlDirctn 250;
BA_REL_ "GenSigSuprvResp" BU_SG_REL_ VIS_FO SG_ 776 Vpath_Data2LongVel 1;
BA_REL_ "GenSigTimeoutTime" BU_SG_REL_ VIS_FO SG_ 776 Vpath_Data2LongVel 120;
BA_REL_ "GenSigSuprvResp" BU_SG_REL_ RSRR_FO SG_ 776 Vpath_Data2LongVel 1;
BA_REL_ "GenSigTimeoutTime" BU_SG_REL_ RSRR_FO SG_ 776 Vpath_Data2LongVel 250;
BA_REL_ "GenSigSuprvResp" BU_SG_REL_ RSRR_FO SG_ 776 Vpath_Data2LongVel 1;
BA_REL_ "GenSigTimeoutTime" BU_SG_REL_ RSRR_FO SG_ 776 Vpath_Data2LongVel 250;
BA_REL_ "GenSigSuprvResp" BU_SG_REL_ RFSRR_FO SG_ 776 Vpath_Data2LongVel 1;
BA_REL_ "GenSigTimeoutTime" BU_SG_REL_ RFSRR_FO SG_ 776 Vpath_Data2LongVel 250;
BA_REL_ "GenSigSuprvResp" BU_SG_REL_ RFSRR_FO SG_ 776 Vpath_Data2LongVel 1;
BA_REL_ "GenSigTimeoutTime" BU_SG_REL_ RFSRR_FO SG_ 776 Vpath_Data2LongVel 250;
BA_REL_ "GenSigSuprvResp" BU_SG_REL_ LRR_FO SG_ 776 Vpath_Data2LongVel 1;
BA_REL_ "GenSigTimeoutMsg" BU_SG_REL_ LRR_FO SG_ 776 Vpath_Data2LongVel 776;
BA_REL_ "GenSigTimeoutTime" BU_SG_REL_ LRR_FO SG_ 776 Vpath_Data2LongVel 120;
BA_REL_ "GenSigSuprvResp" BU_SG_REL_ LRR_FO SG_ 776 Vpath_Data2LongVel 1;
BA_REL_ "GenSigTimeoutMsg" BU_SG_REL_ LRR_FO SG_ 776 Vpath_Data2LongVel 776;
BA_REL_ "GenSigTimeoutTime" BU_SG_REL_ LRR_FO SG_ 776 Vpath_Data2LongVel 120;
BA_REL_ "GenSigSuprvResp" BU_SG_REL_ LFSRR_FO SG_ 776 Vpath_Data2LongVel 1;
BA_REL_ "GenSigTimeoutTime" BU_SG_REL_ LFSRR_FO SG_ 776 Vpath_Data2LongVel 250;
BA_REL_ "GenSigSuprvResp" BU_SG_REL_ LFSRR_FO SG_ 776 Vpath_Data2LongVel 1;
BA_REL_ "GenSigTimeoutTime" BU_SG_REL_ LFSRR_FO SG_ 776 Vpath_Data2LongVel 250;
BA_REL_ "GenSigSuprvResp" BU_SG_REL_ VIS_FO SG_ 776 Vpath_Data2YawRate 1;
BA_REL_ "GenSigTimeoutTime" BU_SG_REL_ VIS_FO SG_ 776 Vpath_Data2YawRate 120;
BA_REL_ "GenSigSuprvResp" BU_SG_REL_ RSRR_FO SG_ 776 Vpath_Data2YawRate 1;
BA_REL_ "GenSigTimeoutTime" BU_SG_REL_ RSRR_FO SG_ 776 Vpath_Data2YawRate 250;
BA_REL_ "GenSigSuprvResp" BU_SG_REL_ RSRR_FO SG_ 776 Vpath_Data2YawRate 1;
BA_REL_ "GenSigTimeoutTime" BU_SG_REL_ RSRR_FO SG_ 776 Vpath_Data2YawRate 250;
BA_REL_ "GenSigSuprvResp" BU_SG_REL_ RFSRR_FO SG_ 776 Vpath_Data2YawRate 1;
BA_REL_ "GenSigTimeoutTime" BU_SG_REL_ RFSRR_FO SG_ 776 Vpath_Data2YawRate 250;
BA_REL_ "GenSigSuprvResp" BU_SG_REL_ RFSRR_FO SG_ 776 Vpath_Data2YawRate 1;
BA_REL_ "GenSigTimeoutTime" BU_SG_REL_ RFSRR_FO SG_ 776 Vpath_Data2YawRate 250;
BA_REL_ "GenSigSuprvResp" BU_SG_REL_ LRR_FO SG_ 776 Vpath_Data2YawRate 1;
BA_REL_ "GenSigTimeoutMsg" BU_SG_REL_ LRR_FO SG_ 776 Vpath_Data2YawRate 776;
BA_REL_ "GenSigTimeoutTime" BU_SG_REL_ LRR_FO SG_ 776 Vpath_Data2YawRate 120;
BA_REL_ "GenSigSuprvResp" BU_SG_REL_ LRR_FO SG_ 776 Vpath_Data2YawRate 1;
BA_REL_ "GenSigTimeoutMsg" BU_SG_REL_ LRR_FO SG_ 776 Vpath_Data2YawRate 776;
BA_REL_ "GenSigTimeoutTime" BU_SG_REL_ LRR_FO SG_ 776 Vpath_Data2YawRate 120;
BA_REL_ "GenSigSuprvResp" BU_SG_REL_ LFSRR_FO SG_ 776 Vpath_Data2YawRate 1;
BA_REL_ "GenSigTimeoutTime" BU_SG_REL_ LFSRR_FO SG_ 776 Vpath_Data2YawRate 250;
BA_REL_ "GenSigSuprvResp" BU_SG_REL_ LFSRR_FO SG_ 776 Vpath_Data2YawRate 1;
BA_REL_ "GenSigTimeoutTime" BU_SG_REL_ LFSRR_FO SG_ 776 Vpath_Data2YawRate 250;
BA_REL_ "GenSigSuprvResp" BU_SG_REL_ VIS_FO SG_ 776 Vpath_Data2LatVel 1;
BA_REL_ "GenSigTimeoutTime" BU_SG_REL_ VIS_FO SG_ 776 Vpath_Data2LatVel 120;
BA_REL_ "GenSigSuprvResp" BU_SG_REL_ RSRR_FO SG_ 776 Vpath_Data2LatVel 1;
BA_REL_ "GenSigTimeoutTime" BU_SG_REL_ RSRR_FO SG_ 776 Vpath_Data2LatVel 250;
BA_REL_ "GenSigSuprvResp" BU_SG_REL_ RSRR_FO SG_ 776 Vpath_Data2LatVel 1;
BA_REL_ "GenSigTimeoutTime" BU_SG_REL_ RSRR_FO SG_ 776 Vpath_Data2LatVel 250;
BA_REL_ "GenSigSuprvResp" BU_SG_REL_ RFSRR_FO SG_ 776 Vpath_Data2LatVel 1;
BA_REL_ "GenSigTimeoutTime" BU_SG_REL_ RFSRR_FO SG_ 776 Vpath_Data2LatVel 250;
BA_REL_ "GenSigSuprvResp" BU_SG_REL_ RFSRR_FO SG_ 776 Vpath_Data2LatVel 1;
BA_REL_ "GenSigTimeoutTime" BU_SG_REL_ RFSRR_FO SG_ 776 Vpath_Data2LatVel 250;
BA_REL_ "GenSigSuprvResp" BU_SG_REL_ LRR_FO SG_ 776 Vpath_Data2LatVel 1;
BA_REL_ "GenSigTimeoutMsg" BU_SG_REL_ LRR_FO SG_ 776 Vpath_Data2LatVel 776;
BA_REL_ "GenSigTimeoutTime" BU_SG_REL_ LRR_FO SG_ 776 Vpath_Data2LatVel 120;
BA_REL_ "GenSigSuprvResp" BU_SG_REL_ LRR_FO SG_ 776 Vpath_Data2LatVel 1;
BA_REL_ "GenSigTimeoutMsg" BU_SG_REL_ LRR_FO SG_ 776 Vpath_Data2LatVel 776;
BA_REL_ "GenSigTimeoutTime" BU_SG_REL_ LRR_FO SG_ 776 Vpath_Data2LatVel 120;
BA_REL_ "GenSigSuprvResp" BU_SG_REL_ LFSRR_FO SG_ 776 Vpath_Data2LatVel 1;
BA_REL_ "GenSigTimeoutTime" BU_SG_REL_ LFSRR_FO SG_ 776 Vpath_Data2LatVel 250;
BA_REL_ "GenSigSuprvResp" BU_SG_REL_ LFSRR_FO SG_ 776 Vpath_Data2LatVel 1;
BA_REL_ "GenSigTimeoutTime" BU_SG_REL_ LFSRR_FO SG_ 776 Vpath_Data2LatVel 250;
BA_REL_ "GenSigSuprvResp" BU_SG_REL_ VIS_FO SG_ 161 FTimeSyncMstrChksm 1;
BA_REL_ "GenSigTimeoutMsg" BU_SG_REL_ VIS_FO SG_ 161 FTimeSyncMstrChksm 161;
BA_REL_ "GenSigTimeoutTime" BU_SG_REL_ VIS_FO SG_ 161 FTimeSyncMstrChksm 250;
BA_REL_ "GenSigSuprvResp" BU_SG_REL_ RSRR_FO SG_ 161 FTimeSyncMstrChksm 1;
BA_REL_ "GenSigTimeoutMsg" BU_SG_REL_ RSRR_FO SG_ 161 FTimeSyncMstrChksm 161;
BA_REL_ "GenSigTimeoutTime" BU_SG_REL_ RSRR_FO SG_ 161 FTimeSyncMstrChksm 250;
BA_REL_ "GenSigSuprvResp" BU_SG_REL_ RSRR_FO SG_ 161 FTimeSyncMstrChksm 1;
BA_REL_ "GenSigTimeoutMsg" BU_SG_REL_ RSRR_FO SG_ 161 FTimeSyncMstrChksm 161;
BA_REL_ "GenSigTimeoutTime" BU_SG_REL_ RSRR_FO SG_ 161 FTimeSyncMstrChksm 250;
BA_REL_ "GenSigSuprvResp" BU_SG_REL_ RFSRR_FO SG_ 161 FTimeSyncMstrChksm 1;
BA_REL_ "GenSigTimeoutMsg" BU_SG_REL_ RFSRR_FO SG_ 161 FTimeSyncMstrChksm 161;
BA_REL_ "GenSigTimeoutTime" BU_SG_REL_ RFSRR_FO SG_ 161 FTimeSyncMstrChksm 250;
BA_REL_ "GenSigSuprvResp" BU_SG_REL_ RFSRR_FO SG_ 161 FTimeSyncMstrChksm 1;
BA_REL_ "GenSigTimeoutMsg" BU_SG_REL_ RFSRR_FO SG_ 161 FTimeSyncMstrChksm 161;
BA_REL_ "GenSigTimeoutTime" BU_SG_REL_ RFSRR_FO SG_ 161 FTimeSyncMstrChksm 250;
BA_REL_ "GenSigSuprvResp" BU_SG_REL_ LRR_FO SG_ 161 FTimeSyncMstrChksm 1;
BA_REL_ "GenSigTimeoutMsg" BU_SG_REL_ LRR_FO SG_ 161 FTimeSyncMstrChksm 161;
BA_REL_ "GenSigTimeoutTime" BU_SG_REL_ LRR_FO SG_ 161 FTimeSyncMstrChksm 250;
BA_REL_ "GenSigSuprvResp" BU_SG_REL_ LRR_FO SG_ 161 FTimeSyncMstrChksm 1;
BA_REL_ "GenSigTimeoutMsg" BU_SG_REL_ LRR_FO SG_ 161 FTimeSyncMstrChksm 161;
BA_REL_ "GenSigTimeoutTime" BU_SG_REL_ LRR_FO SG_ 161 FTimeSyncMstrChksm 250;
BA_REL_ "GenSigSuprvResp" BU_SG_REL_ LFSRR_FO SG_ 161 FTimeSyncMstrChksm 1;
BA_REL_ "GenSigTimeoutMsg" BU_SG_REL_ LFSRR_FO SG_ 161 FTimeSyncMstrChksm 161;
BA_REL_ "GenSigTimeoutTime" BU_SG_REL_ LFSRR_FO SG_ 161 FTimeSyncMstrChksm 250;
BA_REL_ "GenSigSuprvResp" BU_SG_REL_ LFSRR_FO SG_ 161 FTimeSyncMstrChksm 1;
BA_REL_ "GenSigTimeoutMsg" BU_SG_REL_ LFSRR_FO SG_ 161 FTimeSyncMstrChksm 161;
BA_REL_ "GenSigTimeoutTime" BU_SG_REL_ LFSRR_FO SG_ 161 FTimeSyncMstrChksm 250;
BA_REL_ "GenSigVBitResp" BU_SG_REL_ VIS_FO SG_ 161 FTimeSyncMstrClock 1;
BA_REL_ "GenSigSuprvResp" BU_SG_REL_ VIS_FO SG_ 161 FTimeSyncMstrClock 1;
BA_REL_ "GenSigTimeoutMsg" BU_SG_REL_ VIS_FO SG_ 161 FTimeSyncMstrClock 161;
BA_REL_ "GenSigTimeoutTime" BU_SG_REL_ VIS_FO SG_ 161 FTimeSyncMstrClock 250;
BA_REL_ "GenSigVBitResp" BU_SG_REL_ RSRR_FO SG_ 161 FTimeSyncMstrClock 1;
BA_REL_ "GenSigSuprvResp" BU_SG_REL_ RSRR_FO SG_ 161 FTimeSyncMstrClock 1;
BA_REL_ "GenSigTimeoutMsg" BU_SG_REL_ RSRR_FO SG_ 161 FTimeSyncMstrClock 161;
BA_REL_ "GenSigTimeoutTime" BU_SG_REL_ RSRR_FO SG_ 161 FTimeSyncMstrClock 250;
BA_REL_ "GenSigSuprvResp" BU_SG_REL_ RSRR_FO SG_ 161 FTimeSyncMstrClock 1;
BA_REL_ "GenSigTimeoutMsg" BU_SG_REL_ RSRR_FO SG_ 161 FTimeSyncMstrClock 161;
BA_REL_ "GenSigTimeoutTime" BU_SG_REL_ RSRR_FO SG_ 161 FTimeSyncMstrClock 250;
BA_REL_ "GenSigVBitResp" BU_SG_REL_ RFSRR_FO SG_ 161 FTimeSyncMstrClock 1;
BA_REL_ "GenSigSuprvResp" BU_SG_REL_ RFSRR_FO SG_ 161 FTimeSyncMstrClock 1;
BA_REL_ "GenSigTimeoutMsg" BU_SG_REL_ RFSRR_FO SG_ 161 FTimeSyncMstrClock 161;
BA_REL_ "GenSigTimeoutTime" BU_SG_REL_ RFSRR_FO SG_ 161 FTimeSyncMstrClock 250;
BA_REL_ "GenSigSuprvResp" BU_SG_REL_ RFSRR_FO SG_ 161 FTimeSyncMstrClock 1;
BA_REL_ "GenSigTimeoutMsg" BU_SG_REL_ RFSRR_FO SG_ 161 FTimeSyncMstrClock 161;
BA_REL_ "GenSigTimeoutTime" BU_SG_REL_ RFSRR_FO SG_ 161 FTimeSyncMstrClock 250;
BA_REL_ "GenSigVBitResp" BU_SG_REL_ LRR_FO SG_ 161 FTimeSyncMstrClock 1;
BA_REL_ "GenSigSuprvResp" BU_SG_REL_ LRR_FO SG_ 161 FTimeSyncMstrClock 1;
BA_REL_ "GenSigTimeoutMsg" BU_SG_REL_ LRR_FO SG_ 161 FTimeSyncMstrClock 161;
BA_REL_ "GenSigTimeoutTime" BU_SG_REL_ LRR_FO SG_ 161 FTimeSyncMstrClock 250;
BA_REL_ "GenSigSuprvResp" BU_SG_REL_ LRR_FO SG_ 161 FTimeSyncMstrClock 1;
BA_REL_ "GenSigTimeoutMsg" BU_SG_REL_ LRR_FO SG_ 161 FTimeSyncMstrClock 161;
BA_REL_ "GenSigTimeoutTime" BU_SG_REL_ LRR_FO SG_ 161 FTimeSyncMstrClock 250;
BA_REL_ "GenSigVBitResp" BU_SG_REL_ LFSRR_FO SG_ 161 FTimeSyncMstrClock 1;
BA_REL_ "GenSigSuprvResp" BU_SG_REL_ LFSRR_FO SG_ 161 FTimeSyncMstrClock 1;
BA_REL_ "GenSigTimeoutMsg" BU_SG_REL_ LFSRR_FO SG_ 161 FTimeSyncMstrClock 161;
BA_REL_ "GenSigTimeoutTime" BU_SG_REL_ LFSRR_FO SG_ 161 FTimeSyncMstrClock 250;
BA_REL_ "GenSigSuprvResp" BU_SG_REL_ LFSRR_FO SG_ 161 FTimeSyncMstrClock 1;
BA_REL_ "GenSigTimeoutMsg" BU_SG_REL_ LFSRR_FO SG_ 161 FTimeSyncMstrClock 161;
BA_REL_ "GenSigTimeoutTime" BU_SG_REL_ LFSRR_FO SG_ 161 FTimeSyncMstrClock 250;
BA_REL_ "GenSigSuprvResp" BU_SG_REL_ LRR_FO SG_ 161 SensorModeCmdLRR 1;
BA_REL_ "GenSigTimeoutMsg" BU_SG_REL_ LRR_FO SG_ 161 SensorModeCmdLRR 161;
BA_REL_ "GenSigTimeoutTime" BU_SG_REL_ LRR_FO SG_ 161 SensorModeCmdLRR 250;
BA_REL_ "GenSigSuprvResp" BU_SG_REL_ RSRR_FO SG_ 161 SensorModeCmdSRR 1;
BA_REL_ "GenSigTimeoutMsg" BU_SG_REL_ RSRR_FO SG_ 161 SensorModeCmdSRR 161;
BA_REL_ "GenSigTimeoutTime" BU_SG_REL_ RSRR_FO SG_ 161 SensorModeCmdSRR 250;
BA_REL_ "GenSigSuprvResp" BU_SG_REL_ RSRR_FO SG_ 161 SensorModeCmdSRR 1;
BA_REL_ "GenSigTimeoutMsg" BU_SG_REL_ RSRR_FO SG_ 161 SensorModeCmdSRR 161;
BA_REL_ "GenSigTimeoutTime" BU_SG_REL_ RSRR_FO SG_ 161 SensorModeCmdSRR 250;
BA_REL_ "GenSigSuprvResp" BU_SG_REL_ RFSRR_FO SG_ 161 SensorModeCmdSRR 1;
BA_REL_ "GenSigTimeoutMsg" BU_SG_REL_ RFSRR_FO SG_ 161 SensorModeCmdSRR 161;
BA_REL_ "GenSigTimeoutTime" BU_SG_REL_ RFSRR_FO SG_ 161 SensorModeCmdSRR 250;
BA_REL_ "GenSigSuprvResp" BU_SG_REL_ VIS_FO SG_ 161 SensorModeCmdFCamera 1;
BA_REL_ "GenSigTimeoutMsg" BU_SG_REL_ VIS_FO SG_ 161 SensorModeCmdFCamera 161;
BA_REL_ "GenSigTimeoutTime" BU_SG_REL_ VIS_FO SG_ 161 SensorModeCmdFCamera 250;
BA_REL_ "GenSigSuprvResp" BU_SG_REL_ VIS_FO SG_ 774 Vpath_RollingCount 1;
BA_REL_ "GenSigTimeoutTime" BU_SG_REL_ VIS_FO SG_ 774 Vpath_RollingCount 120;
BA_REL_ "GenSigSuprvResp" BU_SG_REL_ RSRR_FO SG_ 774 Vpath_RollingCount 1;
BA_REL_ "GenSigTimeoutTime" BU_SG_REL_ RSRR_FO SG_ 774 Vpath_RollingCount 250;
BA_REL_ "GenSigSuprvResp" BU_SG_REL_ RSRR_FO SG_ 774 Vpath_RollingCount 1;
BA_REL_ "GenSigTimeoutTime" BU_SG_REL_ RSRR_FO SG_ 774 Vpath_RollingCount 250;
BA_REL_ "GenSigSuprvResp" BU_SG_REL_ RFSRR_FO SG_ 774 Vpath_RollingCount 1;
BA_REL_ "GenSigTimeoutTime" BU_SG_REL_ RFSRR_FO SG_ 774 Vpath_RollingCount 250;
BA_REL_ "GenSigSuprvResp" BU_SG_REL_ RFSRR_FO SG_ 774 Vpath_RollingCount 1;
BA_REL_ "GenSigTimeoutTime" BU_SG_REL_ RFSRR_FO SG_ 774 Vpath_RollingCount 250;
BA_REL_ "GenSigSuprvResp" BU_SG_REL_ LRR_FO SG_ 774 Vpath_RollingCount 1;
BA_REL_ "GenSigTimeoutMsg" BU_SG_REL_ LRR_FO SG_ 774 Vpath_RollingCount 774;
BA_REL_ "GenSigTimeoutTime" BU_SG_REL_ LRR_FO SG_ 774 Vpath_RollingCount 120;
BA_REL_ "GenSigSuprvResp" BU_SG_REL_ LRR_FO SG_ 774 Vpath_RollingCount 1;
BA_REL_ "GenSigTimeoutMsg" BU_SG_REL_ LRR_FO SG_ 774 Vpath_RollingCount 774;
BA_REL_ "GenSigTimeoutTime" BU_SG_REL_ LRR_FO SG_ 774 Vpath_RollingCount 120;
BA_REL_ "GenSigSuprvResp" BU_SG_REL_ LFSRR_FO SG_ 774 Vpath_RollingCount 1;
BA_REL_ "GenSigTimeoutTime" BU_SG_REL_ LFSRR_FO SG_ 774 Vpath_RollingCount 250;
BA_REL_ "GenSigSuprvResp" BU_SG_REL_ LFSRR_FO SG_ 774 Vpath_RollingCount 1;
BA_REL_ "GenSigTimeoutTime" BU_SG_REL_ LFSRR_FO SG_ 774 Vpath_RollingCount 250;
BA_REL_ "GenSigSuprvResp" BU_SG_REL_ LRR_FO SG_ 774 Vpath_Checksum 1;
BA_REL_ "GenSigTimeoutMsg" BU_SG_REL_ LRR_FO SG_ 774 Vpath_Checksum 774;
BA_REL_ "GenSigTimeoutTime" BU_SG_REL_ LRR_FO SG_ 774 Vpath_Checksum 120;
BA_REL_ "GenSigSuprvResp" BU_SG_REL_ LRR_FO SG_ 774 Vpath_Checksum 1;
BA_REL_ "GenSigTimeoutMsg" BU_SG_REL_ LRR_FO SG_ 774 Vpath_Checksum 774;
BA_REL_ "GenSigTimeoutTime" BU_SG_REL_ LRR_FO SG_ 774 Vpath_Checksum 120;
BA_REL_ "GenSigSuprvResp" BU_SG_REL_ LRR_FO SG_ 774 Vpath_TrnCtrLngOfst 1;
BA_REL_ "GenSigTimeoutMsg" BU_SG_REL_ LRR_FO SG_ 774 Vpath_TrnCtrLngOfst 774;
BA_REL_ "GenSigTimeoutTime" BU_SG_REL_ LRR_FO SG_ 774 Vpath_TrnCtrLngOfst 120;
BA_REL_ "GenSigSuprvResp" BU_SG_REL_ VIS_FO SG_ 774 Vpath_TrnCtrLngOfst 1;
BA_REL_ "GenSigTimeoutTime" BU_SG_REL_ VIS_FO SG_ 774 Vpath_TrnCtrLngOfst 120;
BA_REL_ "GenSigSuprvResp" BU_SG_REL_ RSRR_FO SG_ 774 Vpath_TrnCtrLngOfst 1;
BA_REL_ "GenSigTimeoutTime" BU_SG_REL_ RSRR_FO SG_ 774 Vpath_TrnCtrLngOfst 250;
BA_REL_ "GenSigSuprvResp" BU_SG_REL_ RFSRR_FO SG_ 774 Vpath_TrnCtrLngOfst 1;
BA_REL_ "GenSigTimeoutTime" BU_SG_REL_ RFSRR_FO SG_ 774 Vpath_TrnCtrLngOfst 250;
BA_REL_ "GenSigSuprvResp" BU_SG_REL_ LFSRR_FO SG_ 774 Vpath_TrnCtrLngOfst 1;
BA_REL_ "GenSigTimeoutTime" BU_SG_REL_ LFSRR_FO SG_ 774 Vpath_TrnCtrLngOfst 250;
BA_REL_ "GenSigSuprvResp" BU_SG_REL_ LRR_FO SG_ 774 Vpath_TrnCtrLatOfst 1;
BA_REL_ "GenSigTimeoutMsg" BU_SG_REL_ LRR_FO SG_ 774 Vpath_TrnCtrLatOfst 774;
BA_REL_ "GenSigTimeoutTime" BU_SG_REL_ LRR_FO SG_ 774 Vpath_TrnCtrLatOfst 120;
BA_REL_ "GenSigSuprvResp" BU_SG_REL_ VIS_FO SG_ 774 Vpath_TrnCtrLatOfst 1;
BA_REL_ "GenSigTimeoutTime" BU_SG_REL_ VIS_FO SG_ 774 Vpath_TrnCtrLatOfst 120;
BA_REL_ "GenSigSuprvResp" BU_SG_REL_ RSRR_FO SG_ 774 Vpath_TrnCtrLatOfst 1;
BA_REL_ "GenSigTimeoutTime" BU_SG_REL_ RSRR_FO SG_ 774 Vpath_TrnCtrLatOfst 250;
BA_REL_ "GenSigSuprvResp" BU_SG_REL_ RFSRR_FO SG_ 774 Vpath_TrnCtrLatOfst 1;
BA_REL_ "GenSigTimeoutTime" BU_SG_REL_ RFSRR_FO SG_ 774 Vpath_TrnCtrLatOfst 250;
BA_REL_ "GenSigSuprvResp" BU_SG_REL_ LFSRR_FO SG_ 774 Vpath_TrnCtrLatOfst 1;
BA_REL_ "GenSigTimeoutTime" BU_SG_REL_ LFSRR_FO SG_ 774 Vpath_TrnCtrLatOfst 250;
BA_REL_ "GenSigSuprvResp" BU_SG_REL_ VIS_FO SG_ 774 Vpath_Curvature 1;
BA_REL_ "GenSigTimeoutMsg" BU_SG_REL_ VIS_FO SG_ 774 Vpath_Curvature 774;
BA_REL_ "GenSigTimeoutTime" BU_SG_REL_ VIS_FO SG_ 774 Vpath_Curvature 120;
BA_REL_ "GenSigSuprvResp" BU_SG_REL_ LRR_FO SG_ 774 Vpath_Curvature 1;
BA_REL_ "GenSigTimeoutMsg" BU_SG_REL_ LRR_FO SG_ 774 Vpath_Curvature 774;
BA_REL_ "GenSigTimeoutTime" BU_SG_REL_ LRR_FO SG_ 774 Vpath_Curvature 120;
BA_REL_ "GenSigSuprvResp" BU_SG_REL_ LRR_FO SG_ 774 Vpath_Curvature 1;
BA_REL_ "GenSigTimeoutMsg" BU_SG_REL_ LRR_FO SG_ 774 Vpath_Curvature 774;
BA_REL_ "GenSigTimeoutTime" BU_SG_REL_ LRR_FO SG_ 774 Vpath_Curvature 120;
BA_REL_ "GenSigTimeoutMsg" BU_SG_REL_ EOCM_F_FO SG_ 848 LnSnsLnChngStatus 848;
BA_REL_ "GenSigTimeoutMsg" BU_SG_REL_ EOCM_F_FO SG_ 848 LnSnsBurstChecksum 848;
BA_REL_ "GenSigSuprvResp" BU_SG_REL_ EOCM_F_FO SG_ 848 LaneSenseRollingCount 1;
BA_REL_ "GenSigTimeoutMsg" BU_SG_REL_ EOCM_F_FO SG_ 848 LaneSenseRollingCount 848;
BA_REL_ "GenSigTimeoutTime" BU_SG_REL_ EOCM_F_FO SG_ 848 LaneSenseRollingCount 150;
BA_REL_ "GenSigSuprvResp" BU_SG_REL_ EOCM_F_FO SG_ 848 LaneSenseRollingCount 1;
BA_REL_ "GenSigTimeoutMsg" BU_SG_REL_ EOCM_F_FO SG_ 848 LaneSenseRollingCount 848;
BA_REL_ "GenSigTimeoutTime" BU_SG_REL_ EOCM_F_FO SG_ 848 LaneSenseRollingCount 150;
BA_REL_ "GenSigTimeoutMsg" BU_SG_REL_ EOCM_F_FO SG_ 848 LaneSenseSystemOK 848;
BA_REL_ "GenSigTimeoutMsg" BU_SG_REL_ EOCM_F_FO SG_ 848 LaneSnsLLnPosValid 848;
BA_REL_ "GenSigTimeoutMsg" BU_SG_REL_ EOCM_F_FO SG_ 848 LnSenseDistToLLnEdge 848;
BA_REL_ "GenSigTimeoutMsg" BU_SG_REL_ EOCM_F_FO SG_ 848 LnSnsRLnPosValid 848;
BA_REL_ "GenSigTimeoutMsg" BU_SG_REL_ EOCM_F_FO SG_ 848 LnSnsDistToRLnEdge 848;
BA_REL_ "GenSigTimeoutMsg" BU_SG_REL_ EOCM_F_FO SG_ 848 LaneSenseTimeStamp 848;
VAL_ 1401 RwdFusTrkB9DynProp 4 "Moving in opposite direction" 3 "Moving in same direction as host" 2 "Has moved but currently stopped" 1 "Has never moved" 0 "Unknown" ;
VAL_ 1401 RwdFusTrkB9RelLane 3 "Left Lane" 2 "Right Lane" 1 "Host Lane" 0 "Unknown" ;
VAL_ 1401 RFusTrkB9ObjSrcLFSrr 1 "true" 0 "false" ;
VAL_ 1401 RFusTrkB9ObjSrcLCSrr 1 "true" 0 "false" ;
VAL_ 1401 RFusTrkB9ObjSrcRCSrr 1 "true" 0 "false" ;
VAL_ 1401 RFusTrkB9ObjSrcRFSrr 1 "true" 0 "false" ;
VAL_ 1401 RFusTrkB9ObjSrcVIs 1 "true" 0 "false" ;
VAL_ 1401 RwdFusTrkB9ObjSrcLrr 1 "true" 0 "false" ;
VAL_ 1400 RwdFusTrkB8DynProp 4 "Moving in opposite direction" 3 "Moving in same direction as host" 2 "Has moved but currently stopped" 1 "Has never moved" 0 "Unknown" ;
VAL_ 1400 RwdFusTrkB8RelLane 3 "Left Lane" 2 "Right Lane" 1 "Host Lane" 0 "Unknown" ;
VAL_ 1400 RFusTrkB8ObjSrcLFSrr 1 "true" 0 "false" ;
VAL_ 1400 RFusTrkB8ObjSrcLCSrr 1 "true" 0 "false" ;
VAL_ 1400 RFusTrkB8ObjSrcRCSrr 1 "true" 0 "false" ;
VAL_ 1400 RFusTrkB8ObjSrcRFSrr 1 "true" 0 "false" ;
VAL_ 1400 RFusTrkB8ObjSrcVIs 1 "true" 0 "false" ;
VAL_ 1400 RwdFusTrkB8ObjSrcLrr 1 "true" 0 "false" ;
VAL_ 1399 RwdFusTrkB7DynProp 4 "Moving in opposite direction" 3 "Moving in same direction as host" 2 "Has moved but currently stopped" 1 "Has never moved" 0 "Unknown" ;
VAL_ 1399 RwdFusTrkB7RelLane 3 "Left Lane" 2 "Right Lane" 1 "Host Lane" 0 "Unknown" ;
VAL_ 1399 RFusTrkB7ObjSrcLFSrr 1 "true" 0 "false" ;
VAL_ 1399 RFusTrkB7ObjSrcLCSrr 1 "true" 0 "false" ;
VAL_ 1399 RFusTrkB7ObjSrcRCSrr 1 "true" 0 "false" ;
VAL_ 1399 RFusTrkB7ObjSrcRFSrr 1 "true" 0 "false" ;
VAL_ 1399 RFusTrkB7ObjSrcVIs 1 "true" 0 "false" ;
VAL_ 1399 RwdFusTrkB7ObjSrcLrr 1 "true" 0 "false" ;
VAL_ 1398 RwdFusTrkB6DynProp 4 "Moving in opposite direction" 3 "Moving in same direction as host" 2 "Has moved but currently stopped" 1 "Has never moved" 0 "Unknown" ;
VAL_ 1398 RwdFusTrkB6RelLane 3 "Left Lane" 2 "Right Lane" 1 "Host Lane" 0 "Unknown" ;
VAL_ 1398 RFusTrkB6ObjSrcLFSrr 1 "true" 0 "false" ;
VAL_ 1398 RFusTrkB6ObjSrcLCSrr 1 "true" 0 "false" ;
VAL_ 1398 RFusTrkB6ObjSrcRCSrr 1 "true" 0 "false" ;
VAL_ 1398 RFusTrkB6ObjSrcRFSrr 1 "true" 0 "false" ;
VAL_ 1398 RFusTrkB6ObjSrcVIs 1 "true" 0 "false" ;
VAL_ 1398 RwdFusTrkB6ObjSrcLrr 1 "true" 0 "false" ;
VAL_ 1397 RwdFusTrkB5DynProp 4 "Moving in opposite direction" 3 "Moving in same direction as host" 2 "Has moved but currently stopped" 1 "Has never moved" 0 "Unknown" ;
VAL_ 1397 RwdFusTrkB5RelLane 3 "Left Lane" 2 "Right Lane" 1 "Host Lane" 0 "Unknown" ;
VAL_ 1397 RFusTrkB5ObjSrcLFSrr 1 "true" 0 "false" ;
VAL_ 1397 RFusTrkB5ObjSrcLCSrr 1 "true" 0 "false" ;
VAL_ 1397 RFusTrkB5ObjSrcRCSrr 1 "true" 0 "false" ;
VAL_ 1397 RFusTrkB5ObjSrcRFSrr 1 "true" 0 "false" ;
VAL_ 1397 RFusTrkB5ObjSrcVIs 1 "true" 0 "false" ;
VAL_ 1397 RwdFusTrkB5ObjSrcLrr 1 "true" 0 "false" ;
VAL_ 1396 RwdFusTrkB4DynProp 4 "Moving in opposite direction" 3 "Moving in same direction as host" 2 "Has moved but currently stopped" 1 "Has never moved" 0 "Unknown" ;
VAL_ 1396 RwdFusTrkB4RelLane 3 "Left Lane" 2 "Right Lane" 1 "Host Lane" 0 "Unknown" ;
VAL_ 1396 RFusTrkB4ObjSrcLFSrr 1 "true" 0 "false" ;
VAL_ 1396 RFusTrkB4ObjSrcLCSrr 1 "true" 0 "false" ;
VAL_ 1396 RFusTrkB4ObjSrcRCSrr 1 "true" 0 "false" ;
VAL_ 1396 RFusTrkB4ObjSrcRFSrr 1 "true" 0 "false" ;
VAL_ 1396 RFusTrkB4ObjSrcVIs 1 "true" 0 "false" ;
VAL_ 1396 RwdFusTrkB4ObjSrcLrr 1 "true" 0 "false" ;
VAL_ 1395 RwdFusTrkB3DynProp 4 "Moving in opposite direction" 3 "Moving in same direction as host" 2 "Has moved but currently stopped" 1 "Has never moved" 0 "Unknown" ;
VAL_ 1395 RwdFusTrkB3RelLane 3 "Left Lane" 2 "Right Lane" 1 "Host Lane" 0 "Unknown" ;
VAL_ 1395 RFusTrkB3ObjSrcLFSrr 1 "true" 0 "false" ;
VAL_ 1395 RFusTrkB3ObjSrcLCSrr 1 "true" 0 "false" ;
VAL_ 1395 RFusTrkB3ObjSrcRCSrr 1 "true" 0 "false" ;
VAL_ 1395 RFusTrkB3ObjSrcRFSrr 1 "true" 0 "false" ;
VAL_ 1395 RFusTrkB3ObjSrcVIs 1 "true" 0 "false" ;
VAL_ 1395 RwdFusTrkB3ObjSrcLrr 1 "true" 0 "false" ;
VAL_ 1394 RwdFusTrkB2DynProp 4 "Moving in opposite direction" 3 "Moving in same direction as host" 2 "Has moved but currently stopped" 1 "Has never moved" 0 "Unknown" ;
VAL_ 1394 RwdFusTrkB2RelLane 3 "Left Lane" 2 "Right Lane" 1 "Host Lane" 0 "Unknown" ;
VAL_ 1394 RFusTrkB2ObjSrcLFSrr 1 "true" 0 "false" ;
VAL_ 1394 RFusTrkB2ObjSrcLCSrr 1 "true" 0 "false" ;
VAL_ 1394 RFusTrkB2ObjSrcRCSrr 1 "true" 0 "false" ;
VAL_ 1394 RFusTrkB2ObjSrcRFSrr 1 "true" 0 "false" ;
VAL_ 1394 RFusTrkB2ObjSrcVIs 1 "true" 0 "false" ;
VAL_ 1394 RwdFusTrkB2ObjSrcLrr 1 "true" 0 "false" ;
VAL_ 1407 RwdFusTrkB15DynProp 4 "Moving in opposite direction" 3 "Moving in same direction as host" 2 "Has moved but currently stopped" 1 "Has never moved" 0 "Unknown" ;
VAL_ 1407 RwdFusTrkB15RelLane 3 "Left Lane" 2 "Right Lane" 1 "Host Lane" 0 "Unknown" ;
VAL_ 1407 RFusTrkB15ObjSrcLFSrr 1 "true" 0 "false" ;
VAL_ 1407 RFusTrkB15ObjSrcLCSrr 1 "true" 0 "false" ;
VAL_ 1407 RFusTrkB15ObjSrcRCSrr 1 "true" 0 "false" ;
VAL_ 1407 RFusTrkB15ObjSrcRFSrr 1 "true" 0 "false" ;
VAL_ 1407 RFusTkB15ObjSrcVIs 0 "false" 1 "true" ;
VAL_ 1407 RwdFusTrkB15ObjSrcLrr 1 "true" 0 "false" ;
VAL_ 1406 RwdFusTrkB14DynProp 4 "Moving in opposite direction" 3 "Moving in same direction as host" 2 "Has moved but currently stopped" 1 "Has never moved" 0 "Unknown" ;
VAL_ 1406 RwdFusTrkB14RelLane 3 "Left Lane" 2 "Right Lane" 1 "Host Lane" 0 "Unknown" ;
VAL_ 1406 RFusTrkB14ObjSrcLFSrr 1 "true" 0 "false" ;
VAL_ 1406 RFusTrkB14ObjSrcLCSrr 1 "true" 0 "false" ;
VAL_ 1406 RFusTrkB14ObjSrcRCSrr 1 "true" 0 "false" ;
VAL_ 1406 RFusTrkB14ObjSrcRFSrr 1 "true" 0 "false" ;
VAL_ 1406 RFusTrkB14ObjSrcVIs 1 "true" 0 "false" ;
VAL_ 1406 RwdFusTrkB14ObjSrcLrr 1 "true" 0 "false" ;
VAL_ 1405 RwdFusTrkB13DynProp 4 "Moving in opposite direction" 3 "Moving in same direction as host" 2 "Has moved but currently stopped" 1 "Has never moved" 0 "Unknown" ;
VAL_ 1405 RwdFusTrkB13RelLane 3 "Left Lane" 2 "Right Lane" 1 "Host Lane" 0 "Unknown" ;
VAL_ 1405 RFusTrkB13ObjSrcLFSrr 1 "true" 0 "false" ;
VAL_ 1405 RFusTrkB13ObjSrcLCSrr 1 "true" 0 "false" ;
VAL_ 1405 RFusTrkB13ObjSrcRCSrr 1 "true" 0 "false" ;
VAL_ 1405 RFusTrkB13ObjSrcRFSrr 1 "true" 0 "false" ;
VAL_ 1405 RFusTrkB13ObjSrcVIs 1 "true" 0 "false" ;
VAL_ 1405 RwdFusTrkB13ObjSrcLrr 1 "true" 0 "false" ;
VAL_ 1404 RwdFusTrkB12DynProp 4 "Moving in opposite direction" 3 "Moving in same direction as host" 2 "Has moved but currently stopped" 1 "Has never moved" 0 "Unknown" ;
VAL_ 1404 RwdFusTrkB12RelLane 3 "Left Lane" 2 "Right Lane" 1 "Host Lane" 0 "Unknown" ;
VAL_ 1404 RFusTrkB12ObjSrcLFSrr 1 "true" 0 "false" ;
VAL_ 1404 RFusTrkB12ObjSrcLCSrr 1 "true" 0 "false" ;
VAL_ 1404 RFusTrkB12ObjSrcRCSrr 1 "true" 0 "false" ;
VAL_ 1404 RFusTrkB12ObjSrcRFSrr 1 "true" 0 "false" ;
VAL_ 1404 RFusTrkB12ObjSrcVIs 1 "true" 0 "false" ;
VAL_ 1404 RwdFusTrkB12ObjSrcLrr 1 "true" 0 "false" ;
VAL_ 1403 RwdFusTrkB11DynProp 4 "Moving in opposite direction" 3 "Moving in same direction as host" 2 "Has moved but currently stopped" 1 "Has never moved" 0 "Unknown" ;
VAL_ 1403 RwdFusTrkB11RelLane 3 "Left Lane" 2 "Right Lane" 1 "Host Lane" 0 "Unknown" ;
VAL_ 1403 RFusTrkB11ObjSrcLFSrr 1 "true" 0 "false" ;
VAL_ 1403 RFusTrkB11ObjSrcLCSrr 1 "true" 0 "false" ;
VAL_ 1403 RFusTrkB11ObjSrcRCSrr 1 "true" 0 "false" ;
VAL_ 1403 RFusTrkB11ObjSrcRFSrr 1 "true" 0 "false" ;
VAL_ 1403 RFusTrkB11ObjSrcVIs 1 "true" 0 "false" ;
VAL_ 1403 RwdFusTrkB11ObjSrcLrr 0 "false" 1 "true" ;
VAL_ 1402 RwdFusTrkB10DynProp 4 "Moving in opposite direction" 3 "Moving in same direction as host" 2 "Has moved but currently stopped" 1 "Has never moved" 0 "Unknown" ;
VAL_ 1402 RwdFusTrkB10RelLane 3 "Left Lane" 2 "Right Lane" 1 "Host Lane" 0 "Unknown" ;
VAL_ 1402 RFusTrkB10ObjSrcLFSrr 1 "true" 0 "false" ;
VAL_ 1402 RFusTrkB10ObjSrcLCSrr 1 "true" 0 "false" ;
VAL_ 1402 RFusTrkB10ObjSrcRCSrr 1 "true" 0 "false" ;
VAL_ 1402 RFusTrkB10ObjSrcRFSrr 1 "true" 0 "false" ;
VAL_ 1402 RFusTrkB10ObjSrcVIs 1 "true" 0 "false" ;
VAL_ 1402 RwdFusTrkB10ObjSrcLrr 1 "true" 0 "false" ;
VAL_ 1393 RwdFusTrkB1DynProp 4 "Moving in opposite direction" 3 "Moving in same direction as host" 2 "Has moved but currently stopped" 1 "Has never moved" 0 "Unknown" ;
VAL_ 1393 RwdFusTrkB1RelLane 3 "Left Lane" 2 "Right Lane" 1 "Host Lane" 0 "Unknown" ;
VAL_ 1393 RFusTrkB1ObjSrcLFSrr 1 "true" 0 "false" ;
VAL_ 1393 RFusTrkB1ObjSrcLCSrr 1 "true" 0 "false" ;
VAL_ 1393 RFusTrkB1ObjSrcRCSrr 1 "true" 0 "false" ;
VAL_ 1393 RFusTrkB1ObjSrcRFSrr 1 "true" 0 "false" ;
VAL_ 1393 RFusTrkB1ObjSrcVIs 1 "true" 0 "false" ;
VAL_ 1393 RwdFusTrkB1ObjSrcLrr 1 "true" 0 "false" ;
VAL_ 1385 RwdFusTrkA9Confidence 3 "confident" 2 "speculative" 1 "highly speculative" 0 "invalid" ;
VAL_ 1385 RwdFusTrkA9MeasStatus 3 "Measured this cycle" 2 "Latent track not detctd this cyc" 1 "New Object" 0 "No Object" ;
VAL_ 1385 RwdFusTrkA9ObjType 7 "no object present" 6 "fixed roadside object" 5 "fixed overhead object" 4 "pedestrian" 3 "motocycle  / bicycle" 2 "Large vehicle (semi)" 1 "4 Wheel Vehicle (car, small trk)" 0 "Unknown" ;
VAL_ 1384 RwdFusTrkA8Confidence 3 "confident" 2 "speculative" 1 "highly speculative" 0 "invalid" ;
VAL_ 1384 RwdFusTrkA8MeasStatus 3 "Measured this cycle" 2 "Latent track not detctd this cyc" 1 "New Object" 0 "No Object" ;
VAL_ 1384 RwdFusTrkA8ObjType 7 "no object present" 6 "fixed roadside object" 5 "fixed overhead object" 4 "pedestrian" 3 "motocycle  / bicycle" 2 "Large vehicle (semi)" 1 "4 Wheel Vehicle (car, small trk)" 0 "Unknown" ;
VAL_ 1362 CPSConfTimeStampV 1 "Invalid" 0 "Valid" ;
VAL_ 1412 FACCTOSDynProp 4 "Moving in opposite direction" 3 "Moving in same direction as host" 2 "Has moved but currently stopped" 1 "Has never moved" 0 "Unknown" ;
VAL_ 1408 CPSTOSDynProp 4 "Moving in opposite direction" 3 "Moving in same direction as host" 2 "Has moved but currently stopped" 1 "Has never moved" 0 "Unknown" ;
VAL_ 1383 RwdFusTrkA7Confidence 3 "confident" 2 "speculative" 1 "highly speculative" 0 "invalid" ;
VAL_ 1383 RwdFusTrkA7MeasStatus 3 "Measured this cycle" 2 "Latent track not detctd this cyc" 1 "New Object" 0 "No Object" ;
VAL_ 1383 RwdFusTrkA7ObjType 7 "no object present" 6 "fixed roadside object" 5 "fixed overhead object" 4 "pedestrian" 3 "motocycle  / bicycle" 2 "Large vehicle (semi)" 1 "4 Wheel Vehicle (car, small trk)" 0 "Unknown" ;
VAL_ 1382 RwdFusTrkA6Confidence 3 "confident" 2 "speculative" 1 "highly speculative" 0 "invalid" ;
VAL_ 1382 RwdFusTrkA6MeasStatus 3 "Measured this cycle" 2 "Latent track not detctd this cyc" 1 "New Object" 0 "No Object" ;
VAL_ 1382 RwdFusTrkA6ObjType 7 "no object present" 6 "fixed roadside object" 5 "fixed overhead object" 4 "pedestrian" 3 "motocycle  / bicycle" 2 "Large vehicle (semi)" 1 "4 Wheel Vehicle (car, small trk)" 0 "Unknown" ;
VAL_ 1381 RwdFusTrkA5Confidence 3 "confident" 2 "speculative" 1 "highly speculative" 0 "invalid" ;
VAL_ 1381 RwdFusTrkA5MeasStatus 3 "Measured this cycle" 2 "Latent track not detctd this cyc" 1 "New Object" 0 "No Object" ;
VAL_ 1381 RwdFusTrkA5ObjType 7 "no object present" 6 "fixed roadside object" 5 "fixed overhead object" 4 "pedestrian" 3 "motocycle  / bicycle" 2 "Large vehicle (semi)" 1 "4 Wheel Vehicle (car, small trk)" 0 "Unknown" ;
VAL_ 768 SmgrMotRollAngleV 1 "Invalid" 0 "Valid" ;
VAL_ 768 SmgrMotPitchAngleV 1 "Invalid" 0 "Valid" ;
VAL_ 768 SmgrMotLongSpeedV 1 "Invalid" 0 "Valid" ;
VAL_ 768 SmgrMotYawRateV 1 "Invalid" 0 "Valid" ;
VAL_ 784 SysPwrMdV 1 "Invalid" 0 "Valid" ;
VAL_ 784 SysPwrMd 3 "Crank Request" 2 "Run" 1 "Accessory" 0 "Off" ;
VAL_ 784 WSWprAct 1 "true" 0 "false" ;
VAL_ 784 RtLwBmFld 1 "true" 0 "false" ;
VAL_ 784 OtsdAmbtLtLvlStatV 1 "Invalid" 0 "Valid" ;
VAL_ 784 OtsdAmbtLtLvlStat 2 "Day" 1 "Night" 0 "Unknown" ;
VAL_ 784 LowBmAct 1 "true" 0 "false" ;
VAL_ 784 LftLwBmFld 1 "true" 0 "false" ;
VAL_ 784 HighBmAct 1 "true" 0 "false" ;
VAL_ 776 Vpath_Data2ModeInfo 2 "Mid Hi Spped" 1 "Low Speed" 0 "Disabled" ;
VAL_ 776 Vpath_Data2YawRateV 1 "Invalid" 0 "Valid" ;
VAL_ 776 Vpath_Data2LongVelV 1 "Invalid" 0 "Valid" ;
VAL_ 776 Vpath_Data2LatVelV 1 "Invalid" 0 "Valid" ;
VAL_ 776 Vpath_Data2TravlDirctn 3 "Other (excessive side slip)" 2 "reverse / stopped in rvrs gear" 1 "Forward / stopped in frwd gear" 0 "Unknown" ;
VAL_ 161 SensorModeCmdLRR 5 "Sensing with Reduced Power" 4 "Undefined" 3 "Radio Silent" 2 "Sensing" 1 "Not Sensing" 0 "Undefined" ;
VAL_ 161 SensorModeCmdSRR 5 "Sensing with Reduced Power" 4 "Undefined" 3 "Radio Silent" 2 "Sensing" 1 "Not Sensing" 0 "Undefined" ;
VAL_ 161 SensorModeCmdFCamera 5 "Sensing with Reduced Power" 4 "Undefined" 3 "Radio Silent" 2 "Sensing" 1 "Not Sensing" 0 "Undefined" ;
VAL_ 161 FTimeSyncMstrClockV 1 "Invalid" 0 "Valid" ;
VAL_ 774 Vpath_TrnCtrLngOfstV 1 "Invalid" 0 "Valid" ;
VAL_ 774 Vpath_CurvatureV 1 "Invalid" 0 "Valid" ;
VAL_ 848 LnSnsLnChngStatus 2 "Lane Change Right" 1 "Lane Change Left" 0 "Idle" ;
VAL_ 848 LaneSenseSystemOK 1 "true" 0 "false" ;
VAL_ 848 LaneSnsLLnPosValid 1 "Invalid" 0 "Valid" ;
VAL_ 848 LnSnsRLnPosValid 1 "Invalid" 0 "Valid" ;
VAL_ 848 LaneSenseTimeStampV 1 "Invalid" 0 "Valid" ;
VAL_ 848 LaneSenseSystemOKV 1 "Invalid" 0 "Valid" ;
VAL_ 848 LnSnsTngtOfHdngLnRtV 1 "Invalid" 0 "Valid" ;
